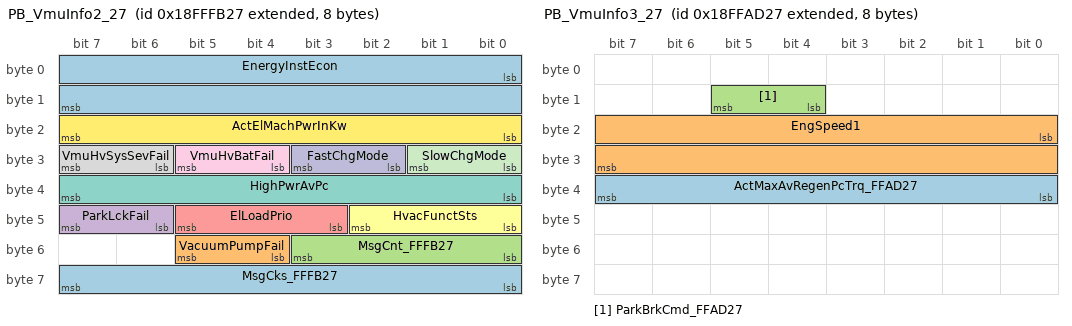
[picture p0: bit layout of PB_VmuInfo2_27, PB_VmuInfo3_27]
BO_ 2566912807 PB_VmuInfo2_27: 8 VCM
 SG_ MsgCks_FFFB27 : 56|8@1+ (1,0) [0|255] "count"  PCM
 SG_ VacuumPumpFail : 52|2@1+ (1,0) [0|3] ""  PCM
 SG_ MsgCnt_FFFB27 : 48|4@1+ (1,0) [0|15] "count"  PCM
 SG_ ParkLckFail : 46|2@1+ (1,0) [0|3] ""  PCM
 SG_ ElLoadPrio : 43|3@1+ (1,0) [0|7] ""  PCM
 SG_ HvacFunctSts : 40|3@1+ (1,0) [0|7] ""  PCM
 SG_ HighPwrAvPc : 32|8@1+ (0.4,0) [0|100] "%"  PCM
 SG_ VmuHvSysSevFail : 30|2@1+ (1,0) [0|3] ""  PCM
 SG_ VmuHvBatFail : 28|2@1+ (1,0) [0|3] ""  PCM
 SG_ FastChgMode : 26|2@1+ (1,0) [0|3] ""  PCM
 SG_ SlowChgMode : 24|2@1+ (1,0) [0|3] ""  PCM
 SG_ ActElMachPwrInKw : 16|8@1+ (1,-125) [-125|125] "%"  PCM
 SG_ EnergyInstEcon : 0|16@1+ (0.001953125,0) [0|125.498046875] "km/KWh"  PCM

BO_ 2566892839 PB_VmuInfo3_27: 8 VCM
 SG_ ActMaxAvRegenPcTrq_FFAD27 : 32|8@1+ (0.4,0) [0|100] "%"  PCM
 SG_ EngSpeed1 : 16|16@1+ (0.5,0) [0|32127.5] "rpm"  PCM
 SG_ ParkBrkCmd_FFAD27 : 12|2@1+ (1,0) [0|3] ""  PCM

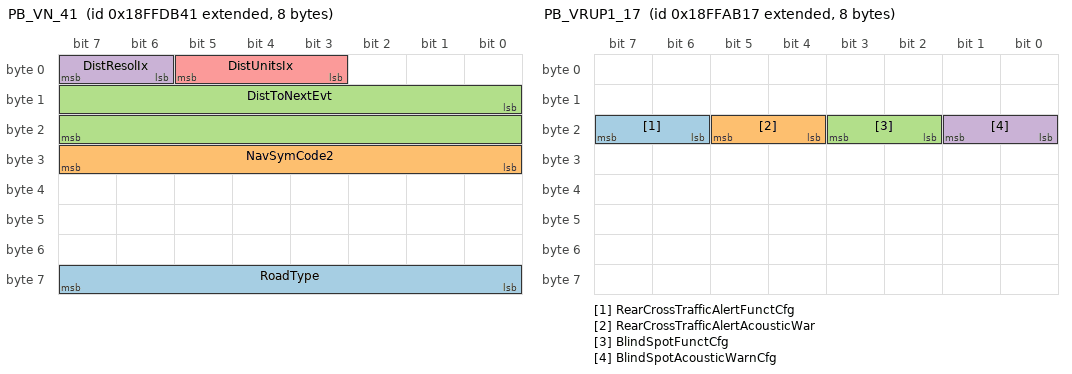
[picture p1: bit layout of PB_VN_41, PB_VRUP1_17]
BO_ 2566904641 PB_VN_41: 8 NIS_RDR
 SG_ RoadType : 56|8@1+ (1,0) [0|250] ""  PCM
 SG_ NavSymCode2 : 24|8@1+ (1,0) [0|250] ""  PCM
 SG_ DistToNextEvt : 8|16@1+ (1,0) [0|64255] ""  PCM
 SG_ DistResolIx : 6|2@1+ (1,0) [0|3] "binary"  PCM
 SG_ DistUnitsIx : 3|3@1+ (1,0) [0|7] "binary"  PCM

BO_ 2566896705 PB_VND_41: 8 NIS_RDR
 SG_ Long : 32|32@1+ (1E-007,-210) [-210|211.1081215] "deg"  PCM
 SG_ Lat : 0|32@1+ (1E-007,-210) [-210|211.1081215] "deg"  PCM

BO_ 2566896714 PB_VND_4A: 8 PCM
 SG_ Long_FFBC4A : 32|32@1+ (1E-007,-210) [-210|211.1081215] "deg" Vector__XXX
 SG_ Lat_FFBC4A : 0|32@1+ (1E-007,-210) [-210|211.1081215] "deg" Vector__XXX

BO_ 2634009665 PB_VNS_41: 402 NIS_RDR
 SG_ NavNextEvtStreetName : 0|8@1+ (1,0) [0|255] "ASCII"  PCM

BO_ 2566892311 PB_VRUP1_17: 8 ICC
 SG_ RearCrossTrafficAlertFunctCfg : 22|2@1+ (1,0) [0|3] ""  PCM
 SG_ RearCrossTrafficAlertAcousticWar : 20|2@1+ (1,0) [0|3] ""  PCM
 SG_ BlindSpotFunctCfg : 18|2@1+ (1,0) [0|3] ""  PCM
 SG_ BlindSpotAcousticWarnCfg : 16|2@1+ (1,0) [0|3] ""  PCM

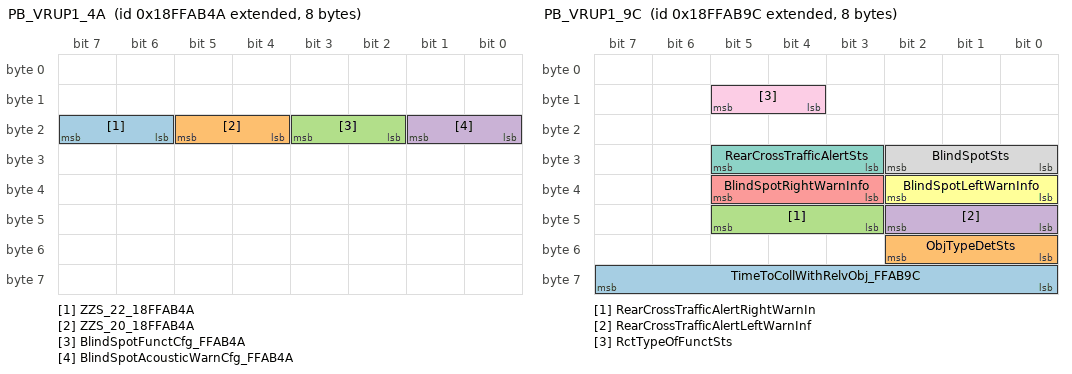
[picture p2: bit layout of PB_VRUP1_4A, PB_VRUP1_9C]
BO_ 2566892362 PB_VRUP1_4A: 8 PCM
 SG_ ZZS_22_18FFAB4A : 22|2@1+ (1,0) [0|3] "" Vector__XXX
 SG_ ZZS_20_18FFAB4A : 20|2@1+ (1,0) [0|3] "" Vector__XXX
 SG_ BlindSpotFunctCfg_FFAB4A : 18|2@1+ (1,0) [0|3] "" Vector__XXX
 SG_ BlindSpotAcousticWarnCfg_FFAB4A : 16|2@1+ (1,0) [0|3] "" Vector__XXX

BO_ 2566892444 PB_VRUP1_9C: 8 RSRRM
 SG_ TimeToCollWithRelvObj_FFAB9C : 56|8@1+ (0.05,0) [0|12.5] "s"  PCM
 SG_ ObjTypeDetSts : 48|3@1+ (1,0) [0|7] ""  PCM
 SG_ RearCrossTrafficAlertRightWarnIn : 43|3@1+ (1,0) [0|7] ""  PCM
 SG_ RearCrossTrafficAlertLeftWarnInf : 40|3@1+ (1,0) [0|7] ""  PCM
 SG_ BlindSpotRightWarnInfo : 35|3@1+ (1,0) [0|7] ""  PCM
 SG_ BlindSpotLeftWarnInfo : 32|3@1+ (1,0) [0|7] ""  PCM
 SG_ RearCrossTrafficAlertSts : 27|3@1+ (1,0) [0|7] ""  PCM
 SG_ BlindSpotSts : 24|3@1+ (1,0) [0|7] ""  PCM
 SG_ RctTypeOfFunctSts : 12|2@1+ (1,0) [0|3] ""  PCM

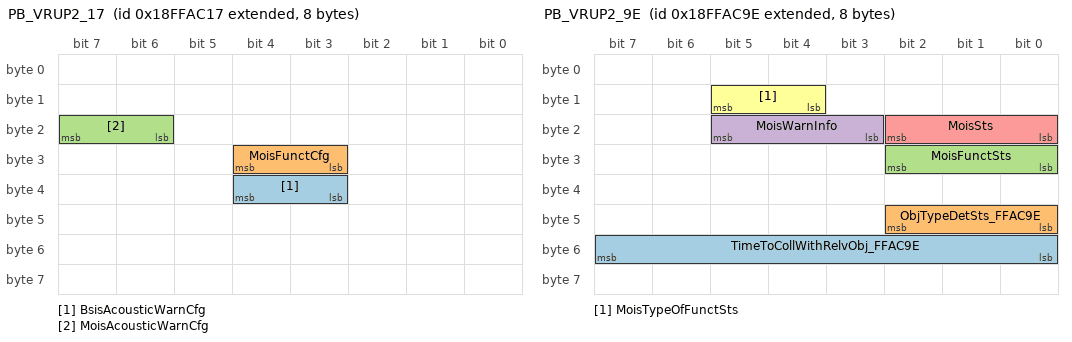
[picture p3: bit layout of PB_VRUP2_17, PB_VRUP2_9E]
BO_ 2566892567 PB_VRUP2_17: 8 ICC
 SG_ BsisAcousticWarnCfg : 35|2@1+ (1,0) [0|3] ""  PCM
 SG_ MoisFunctCfg : 27|2@1+ (1,0) [0|3] ""  PCM
 SG_ MoisAcousticWarnCfg : 22|2@1+ (1,0) [0|3] ""  PCM

BO_ 2566892618 PB_VRUP2_4A: 8 PCM
 SG_ BsisAcousticWarnCfg_FFAC4A : 35|2@1+ (1,0) [0|3] "" Vector__XXX

BO_ 2566892702 PB_VRUP2_9E: 8 ADCU
 SG_ TimeToCollWithRelvObj_FFAC9E : 48|8@1+ (0.05,0) [0|12.5] "s"  PCM
 SG_ ObjTypeDetSts_FFAC9E : 40|3@1+ (1,0) [0|7] ""  PCM
 SG_ MoisFunctSts : 24|3@1+ (1,0) [0|7] ""  PCM
 SG_ MoisWarnInfo : 19|3@1+ (1,0) [0|7] ""  PCM
 SG_ MoisSts : 16|3@1+ (1,0) [0|7] ""  PCM
 SG_ MoisTypeOfFunctSts : 12|2@1+ (1,0) [0|3] ""  PCM

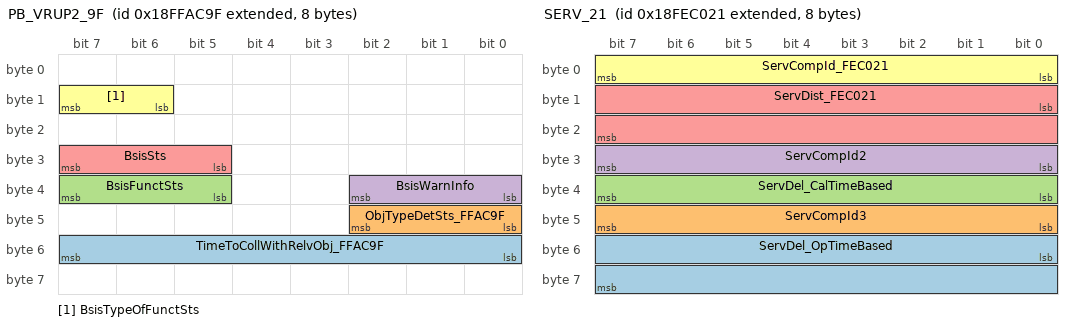
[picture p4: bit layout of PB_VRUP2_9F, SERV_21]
BO_ 2566892703 PB_VRUP2_9F: 8 NODE_9F
 SG_ TimeToCollWithRelvObj_FFAC9F : 48|8@1+ (0.05,0) [0|12.5] "s"  PCM
 SG_ ObjTypeDetSts_FFAC9F : 40|3@1+ (1,0) [0|7] ""  PCM
 SG_ BsisFunctSts : 37|3@1+ (1,0) [0|7] ""  PCM
 SG_ BsisWarnInfo : 32|3@1+ (1,0) [0|7] ""  PCM
 SG_ BsisSts : 29|3@1+ (1,0) [0|7] ""  PCM
 SG_ BsisTypeOfFunctSts : 14|2@1+ (1,0) [0|3] ""  PCM

BO_ 2566865010 PtoSts: 8 EM_PTO
 SG_ PtoDegrModeIx : 56|8@1+ (1,0) [0|255] ""  PCM
 SG_ Pto3EsvCtrl : 52|1@1+ (1,0) [0|1] ""  PCM
 SG_ Pto3LowOilPrs : 51|1@1+ (1,0) [0|1] ""  PCM
 SG_ Pto3Et2Ctrl : 50|1@1+ (1,0) [0|1] ""  PCM
 SG_ Pto3WaterTemp : 49|1@1+ (1,0) [0|1] ""  PCM
 SG_ Pto3VehSpeed : 48|1@1+ (1,0) [0|1] ""  PCM
 SG_ Pto3EngRpm : 47|1@1+ (1,0) [0|1] ""  PCM
 SG_ Pto3Gear : 46|1@1+ (1,0) [0|1] ""  PCM
 SG_ Pto3Clt : 45|1@1+ (1,0) [0|1] ""  PCM
 SG_ Pto3EmIn : 44|1@1+ (1,0) [0|1] ""  PCM
 SG_ Pto3Handbrake : 43|1@1+ (1,0) [0|1] ""  PCM
 SG_ Pto3Brk : 42|1@1+ (1,0) [0|1] ""  PCM
 SG_ Pto3DegrOpMode : 40|2@1+ (1,0) [0|3] ""  PCM
 SG_ Pto2EsvCtrl : 36|1@1+ (1,0) [0|1] ""  PCM
 SG_ Pto2LowOilPrs : 35|1@1+ (1,0) [0|1] ""  PCM
 SG_ Pto2Et2Ctrl : 34|1@1+ (1,0) [0|1] ""  PCM
 SG_ Pto2WaterTemp : 33|1@1+ (1,0) [0|1] ""  PCM
 SG_ Pto2VehSpeed : 32|1@1+ (1,0) [0|1] ""  PCM
 SG_ Pto2EngRpm : 31|1@1+ (1,0) [0|1] ""  PCM
 SG_ Pto2Gear : 30|1@1+ (1,0) [0|1] ""  PCM
 SG_ Pto2Clt : 29|1@1+ (1,0) [0|1] ""  PCM
 SG_ Pto2EmIn : 28|1@1+ (1,0) [0|1] ""  PCM
 SG_ Pto2Handbrake : 27|1@1+ (1,0) [0|1] ""  PCM
 SG_ Pto2Brk : 26|1@1+ (1,0) [0|1] ""  PCM
 SG_ Pto2DegrOpMode : 24|2@1+ (1,0) [0|3] ""  PCM
 SG_ Pto1EsvCtrl : 20|1@1+ (1,0) [0|1] ""  PCM
 SG_ Pto1LowOilPrs : 19|1@1+ (1,0) [0|1] ""  PCM
 SG_ Pto1Et2Ctrl : 18|1@1+ (1,0) [0|1] ""  PCM
 SG_ Pto1WaterTemp : 17|1@1+ (1,0) [0|1] ""  PCM
 SG_ Pto1VehSpeed : 16|1@1+ (1,0) [0|1] ""  PCM
 SG_ Pto1EngRpm : 15|1@1+ (1,0) [0|1] ""  PCM
 SG_ Pto1Gear : 14|1@1+ (1,0) [0|1] ""  PCM
 SG_ Pto1Clt : 13|1@1+ (1,0) [0|1] ""  PCM
 SG_ Pto1EmIn : 12|1@1+ (1,0) [0|1] ""  PCM
 SG_ Pto1Handbrake : 11|1@1+ (1,0) [0|1] ""  PCM
 SG_ Pto1Brk : 10|1@1+ (1,0) [0|1] ""  PCM
 SG_ Pto1DegrOpMode : 8|2@1+ (1,0) [0|3] ""  PCM
 SG_ Pto1EngdSts : 6|2@1+ (1,0) [0|3] ""  PCM
 SG_ Pto2EngdSts : 4|2@1+ (1,0) [0|3] ""  PCM
 SG_ Pto3EngdSts : 2|2@1+ (1,0) [0|3] ""  PCM
 SG_ DegrModeSts : 0|2@1+ (1,0) [0|3] ""  PCM

BO_ 2566840592 RC_DR: 19 EST54_IRCS
 SG_ RetPcTrqAtPeakTrqPnt5 : 144|8@1+ (1,-125) [-125|125] "%"  PCM
 SG_ RetRefTrq : 128|16@1+ (1,0) [0|64255] "Nm"  PCM
 SG_ RetSpeedAtPeakTrqPnt5 : 112|16@1+ (0.125,0) [0|8031.875] "rpm"  PCM
 SG_ RetPcTrqAtPnt4 : 104|8@1+ (1,-125) [-125|125] "%"  PCM
 SG_ RetSpeedAtPnt4 : 88|16@1+ (0.125,0) [0|8031.875] "rpm"  PCM
 SG_ RetPcTrqAtPnt3 : 80|8@1+ (1,-125) [-125|125] "%"  PCM
 SG_ RetSpeedAtPnt3 : 64|16@1+ (0.125,0) [0|8031.875] "rpm"  PCM
 SG_ RetPcTrqAtMaxSpeedPnt2 : 56|8@1+ (1,-125) [-125|125] "%"  PCM
 SG_ MaxRetSpeedPnt2 : 40|16@1+ (0.125,0) [0|8031.875] "rpm"  PCM
 SG_ RetPcTrqAtIdlePnt1 : 32|8@1+ (1,-125) [-125|125] "%"  PCM
 SG_ RetSpeedAtIdlePnt1 : 16|16@1+ (0.125,0) [0|8031.875] "rpm"  PCM
 SG_ RetCtrlMethod : 8|8@1+ (1,0) [0|250] "step"  PCM
 SG_ RetLoc : 4|4@1+ (1,0) [0|15] ""  PCM
 SG_ RetType : 0|4@1+ (1,0) [0|15] ""  PCM

BO_ 2565537610 RQST_4A: 3 PCM
 SG_ PgnRqst : 0|24@1+ (1,0) [0|16777215] "PGN" Vector__XXX

BO_ 2565472330 RQST_4A_00: 3 PCM
 SG_ PgnRqst_EA004A : 0|24@1+ (1,0) [0|16777215] "PGN"  ECM

BO_ 2565473098 RQST_4A_03: 3 PCM
 SG_ PgnRqst_EA034A : 0|24@1+ (1,0) [0|16777215] "PGN"  AI_G5_TCM

BO_ 2565474122 RQST_4A_07: 3 PCM
 SG_ PgnRqst_EA074A : 0|24@1+ (1,0) [0|16777215] "PGN"  NODE_7

BO_ 2565478986 RQST_4A_1A: 3 PCM
 SG_ PgnRqst_EA1A4A : 0|24@1+ (1,0) [0|16777215] "PGN"  ECS

BO_ 2565480778 RQST_4A_21: 3 PCM
 SG_ PgnRqst_EA214A : 0|24@1+ (1,0) [0|16777215] "PGN"  BCM

BO_ 2565481546 RQST_4A_24: 3 PCM
 SG_ PgnRqst_EA244A : 0|24@1+ (1,0) [0|16777215] "PGN"  NODE_24

BO_ 2565482314 RQST_4A_27: 3 PCM
 SG_ PgnRqst_EA274A : 0|24@1+ (1,0) [0|16777215] "PGN"  VCM

BO_ 2565485386 RQST_4A_33: 3 PCM
 SG_ PgnRqst_EA334A : 0|24@1+ (1,0) [0|16777215] "PGN"  OptiTire

BO_ 2565488970 RQST_4A_41: 3 PCM
 SG_ PgnRqst_EA414A : 0|24@1+ (1,0) [0|16777215] "PGN"  NIS_RDR

BO_ 2565491018 RQST_4A_49: 3 PCM
 SG_ PgnRqst_EA494A : 0|24@1+ (1,0) [0|16777215] "PGN"  NODE_49

BO_ 2565504074 RQST_4A_7C: 3 PCM
 SG_ PgnRqst_EA7C4A : 0|24@1+ (1,0) [0|16777215] "PGN"  NODE_7C

BO_ 2565506634 RQST_4A_86: 3 PCM
 SG_ PgnRqst_EA864A : 0|24@1+ (1,0) [0|16777215] "PGN"  NODE_86

BO_ 2565506890 RQST_4A_87: 3 PCM
 SG_ PgnRqst_EA874A : 0|24@1+ (1,0) [0|16777215] "PGN"  NODE_87

BO_ 2565533258 RQST_4A_EE: 3 PCM
 SG_ PgnRqst_EAEE4A : 0|24@1+ (1,0) [0|16777215] "PGN"  DTCO

BO_ 2565533514 RQST_4A_EF: 3 PCM
 SG_ PgnRqst_EAEF4A : 0|24@1+ (1,0) [0|16777215] "PGN"  NODE_EF

BO_ 2565534282 RQST_4A_F2: 3 PCM
 SG_ PgnRqst_EAF24A : 0|24@1+ (1,0) [0|16777215] "PGN"  NODE_F2

BO_ 2565534538 RQST_4A_F3: 3 PCM
 SG_ PgnRqst_EAF34A : 0|24@1+ (1,0) [0|16777215] "PGN"  NODE_F3

BO_ 2565534794 RQST_4A_F4: 3 PCM
 SG_ PgnRqst_EAF44A : 0|24@1+ (1,0) [0|16777215] "PGN"  NODE_F4

BO_ 2565535050 RQST_4A_F5: 3 PCM
 SG_ PgnRqst_EAF54A : 0|24@1+ (1,0) [0|16777215] "PGN"  NODE_F5

BO_ 2565535306 RQST_4A_F6: 3 PCM
 SG_ PgnRqst_EAF64A : 0|24@1+ (1,0) [0|16777215] "PGN"  NODE_F6

BO_ 2566832128 SERV_00: 8 ECM
 SG_ ServDist : 8|16@1+ (5,-160635) [-160635|160640] "km"  PCM
 SG_ ServCompId : 0|8@1+ (1,0) [0|250] "ID"  PCM

BO_ 2566832161 SERV_21: 8 BCM
 SG_ ServDel_OpTimeBased : 48|16@1+ (1,-32127) [-32127|32128] "h"  PCM
 SG_ ServCompId3 : 40|8@1+ (1,0) [0|250] "ID"  PCM
 SG_ ServDel_CalTimeBased : 32|8@1+ (1,-125) [-125|125] "week"  PCM
 SG_ ServCompId2 : 24|8@1+ (1,0) [0|250] "ID"  PCM
 SG_ ServDist_FEC021 : 8|16@1+ (5,-160635) [-160635|160640] "km"  PCM
 SG_ ServCompId_FEC021 : 0|8@1+ (1,0) [0|250] "ID"  PCM

BO_ 2566832366 SERV_EE: 8 DTCO
 SG_ ServDel_CalTimeBased_FEC0EE : 32|8@1+ (1,-125) [-125|125] "week"  PCM
 SG_ ServCompId2_FEC0EE : 24|8@1+ (1,0) [0|250] "ID"  PCM

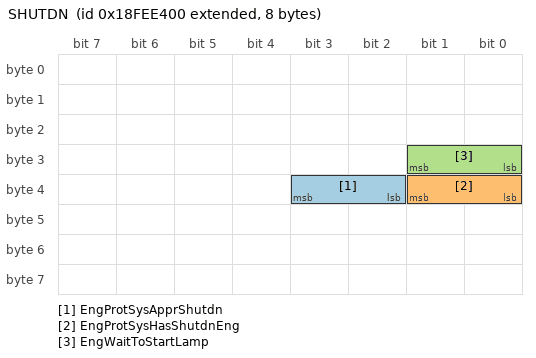
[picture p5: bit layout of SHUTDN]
BO_ 2566841344 SHUTDN: 8 ECM
 SG_ EngProtSysApprShutdn : 34|2@1+ (1,0) [0|3] ""  PCM
 SG_ EngProtSysHasShutdnEng : 32|2@1+ (1,0) [0|3] ""  PCM
 SG_ EngWaitToStartLamp : 24|2@1+ (1,0) [0|3] ""  PCM

BO_ 2566838789 SOFT_05: 202 NODE_5
 SG_ SwIdField5 : 40|8@1+ (1,0) [0|255] "ASCII"  PCM
 SG_ SwIdField4 : 32|8@1+ (1,0) [0|255] "ASCII"  PCM
 SG_ SwIdField3 : 24|8@1+ (1,0) [0|255] "ASCII"  PCM
 SG_ SwIdField2 : 16|8@1+ (1,0) [0|255] "ASCII"  PCM
 SG_ SwIdField1 : 8|8@1+ (1,0) [0|255] "ASCII"  PCM
 SG_ NumOfSwIdFields : 0|8@1+ (1,0) [0|250] "step"  PCM

BO_ 2566838791 SOFT_07: 202 NODE_7
 SG_ SwIdField5_FEDA07 : 40|8@1+ (1,0) [0|255] "ASCII"  PCM
 SG_ SwIdField4_FEDA07 : 32|8@1+ (1,0) [0|255] "ASCII"  PCM
 SG_ SwIdField3_FEDA07 : 24|8@1+ (1,0) [0|255] "ASCII"  PCM
 SG_ SwIdField2_FEDA07 : 16|8@1+ (1,0) [0|255] "ASCII"  PCM
 SG_ SwIdField1_FEDA07 : 8|8@1+ (1,0) [0|255] "ASCII"  PCM
 SG_ NumOfSwIdFields_FEDA07 : 0|8@1+ (1,0) [0|250] "step"  PCM

BO_ 2566838810 SOFT_1A: 202 ECS
 SG_ SwIdField5_FEDA1A : 40|8@1+ (1,0) [0|255] "ASCII"  PCM
 SG_ SwIdField4_FEDA1A : 32|8@1+ (1,0) [0|255] "ASCII"  PCM
 SG_ SwIdField3_FEDA1A : 24|8@1+ (1,0) [0|255] "ASCII"  PCM
 SG_ SwIdField2_FEDA1A : 16|8@1+ (1,0) [0|255] "ASCII"  PCM
 SG_ SwIdField1_FEDA1A : 8|8@1+ (1,0) [0|255] "ASCII"  PCM
 SG_ NumOfSwIdFields_FEDA1A : 0|8@1+ (1,0) [0|250] "step"  PCM

BO_ 2566838813 SOFT_1D: 202 SGW
 SG_ SwIdField5_FEDA1D : 40|8@1+ (1,0) [0|255] "ASCII"  PCM
 SG_ SwIdField4_FEDA1D : 32|8@1+ (1,0) [0|255] "ASCII"  PCM
 SG_ SwIdField3_FEDA1D : 24|8@1+ (1,0) [0|255] "ASCII"  PCM
 SG_ SwIdField2_FEDA1D : 16|8@1+ (1,0) [0|255] "ASCII"  PCM
 SG_ SwIdField1_FEDA1D : 8|8@1+ (1,0) [0|255] "ASCII"  PCM
 SG_ NumOfSwIdFields_FEDA1D : 0|8@1+ (1,0) [0|250] "step"  PCM

BO_ 2566838820 SOFT_24: 202 NODE_24
 SG_ SwIdField5_FEDA24 : 40|8@1+ (1,0) [0|255] "ASCII"  PCM
 SG_ SwIdField4_FEDA24 : 32|8@1+ (1,0) [0|255] "ASCII"  PCM
 SG_ SwIdField3_FEDA24 : 24|8@1+ (1,0) [0|255] "ASCII"  PCM
 SG_ SwIdField2_FEDA24 : 16|8@1+ (1,0) [0|255] "ASCII"  PCM
 SG_ SwIdField1_FEDA24 : 8|8@1+ (1,0) [0|255] "ASCII"  PCM
 SG_ NumOfSwIdFields_FEDA24 : 0|8@1+ (1,0) [0|250] "step"  PCM

BO_ 2566838823 SOFT_27: 202 VCM
 SG_ SwIdField5_FEDA27 : 40|8@1+ (1,0) [0|255] "ASCII"  PCM
 SG_ SwIdField4_FEDA27 : 32|8@1+ (1,0) [0|255] "ASCII"  PCM
 SG_ SwIdField3_FEDA27 : 24|8@1+ (1,0) [0|255] "ASCII"  PCM
 SG_ SwIdField2_FEDA27 : 16|8@1+ (1,0) [0|255] "ASCII"  PCM
 SG_ SwIdField1_FEDA27 : 8|8@1+ (1,0) [0|255] "ASCII"  PCM
 SG_ NumOfSwIdFields_FEDA27 : 0|8@1+ (1,0) [0|250] "step"  PCM

BO_ 2566838831 SOFT_2F: 202 ECAS
 SG_ SwIdField5_FEDA2F : 40|8@1+ (1,0) [0|255] "ASCII"  PCM
 SG_ SwIdField4_FEDA2F : 32|8@1+ (1,0) [0|255] "ASCII"  PCM
 SG_ SwIdField3_FEDA2F : 24|8@1+ (1,0) [0|255] "ASCII"  PCM
 SG_ SwIdField2_FEDA2F : 16|8@1+ (1,0) [0|255] "ASCII"  PCM
 SG_ SwIdField1_FEDA2F : 8|8@1+ (1,0) [0|255] "ASCII"  PCM
 SG_ NumOfSwIdFields_FEDA2F : 0|8@1+ (1,0) [0|250] "step"  PCM

BO_ 2566838832 SOFT_30: 190 CDC
 SG_ SwIdField5_FEDA30 : 40|8@1+ (1,0) [0|255] "ASCII"  PCM
 SG_ SwIdField4_FEDA30 : 32|8@1+ (1,0) [0|255] "ASCII"  PCM
 SG_ SwIdField3_FEDA30 : 24|8@1+ (1,0) [0|255] "ASCII"  PCM
 SG_ SwIdField2_FEDA30 : 16|8@1+ (1,0) [0|255] "ASCII"  PCM
 SG_ SwIdField1_FEDA30 : 8|8@1+ (1,0) [0|255] "ASCII"  PCM
 SG_ NumOfSwIdFields_FEDA30 : 0|8@1+ (1,0) [0|250] "step"  PCM

BO_ 2566838835 SOFT_33: 202 OptiTire
 SG_ SwIdField5_FEDA33 : 40|8@1+ (1,0) [0|255] "ASCII"  PCM
 SG_ SwIdField4_FEDA33 : 32|8@1+ (1,0) [0|255] "ASCII"  PCM
 SG_ SwIdField3_FEDA33 : 24|8@1+ (1,0) [0|255] "ASCII"  PCM
 SG_ SwIdField2_FEDA33 : 16|8@1+ (1,0) [0|255] "ASCII"  PCM
 SG_ SwIdField1_FEDA33 : 8|8@1+ (1,0) [0|255] "ASCII"  PCM
 SG_ NumOfSwIdFields_FEDA33 : 0|8@1+ (1,0) [0|250] "step"  PCM

BO_ 2566838849 SOFT_41: 202 NIS_RDR
 SG_ SwIdField5_FEDA41 : 40|8@1+ (1,0) [0|255] "ASCII"  PCM
 SG_ SwIdField4_FEDA41 : 32|8@1+ (1,0) [0|255] "ASCII"  PCM
 SG_ SwIdField3_FEDA41 : 24|8@1+ (1,0) [0|255] "ASCII"  PCM
 SG_ SwIdField2_FEDA41 : 16|8@1+ (1,0) [0|255] "ASCII"  PCM
 SG_ SwIdField1_FEDA41 : 8|8@1+ (1,0) [0|255] "ASCII"  PCM
 SG_ NumOfSwIdFields_FEDA41 : 0|8@1+ (1,0) [0|250] "step"  PCM

BO_ 2566838857 SOFT_49: 202 NODE_49
 SG_ SwIdField5_FEDA49 : 40|8@1+ (1,0) [0|255] "ASCII"  PCM
 SG_ SwIdField4_FEDA49 : 32|8@1+ (1,0) [0|255] "ASCII"  PCM
 SG_ SwIdField3_FEDA49 : 24|8@1+ (1,0) [0|255] "ASCII"  PCM
 SG_ SwIdField2_FEDA49 : 16|8@1+ (1,0) [0|255] "ASCII"  PCM
 SG_ SwIdField1_FEDA49 : 8|8@1+ (1,0) [0|255] "ASCII"  PCM
 SG_ NumOfSwIdFields_FEDA49 : 0|8@1+ (1,0) [0|250] "step"  PCM

BO_ 2566838858 SOFT_4A: 202 PCM
 SG_ SwIdField5_FEDA4A : 40|8@1+ (1,0) [0|255] "ASCII" Vector__XXX
 SG_ SwIdField4_FEDA4A : 32|8@1+ (1,0) [0|255] "ASCII" Vector__XXX
 SG_ SwIdField3_FEDA4A : 24|8@1+ (1,0) [0|255] "ASCII" Vector__XXX
 SG_ SwIdField2_FEDA4A : 16|8@1+ (1,0) [0|255] "ASCII" Vector__XXX
 SG_ SwIdField1_FEDA4A : 8|8@1+ (1,0) [0|255] "ASCII" Vector__XXX
 SG_ NumOfSwIdFields_FEDA4A : 0|8@1+ (1,0) [0|250] "step" Vector__XXX

BO_ 2566838861 SOFT_4D: 202 SCU
 SG_ SwIdField5_FEDA4D : 40|8@1+ (1,0) [0|255] "ASCII"  PCM
 SG_ SwIdField4_FEDA4D : 32|8@1+ (1,0) [0|255] "ASCII"  PCM
 SG_ SwIdField3_FEDA4D : 24|8@1+ (1,0) [0|255] "ASCII"  PCM
 SG_ SwIdField2_FEDA4D : 16|8@1+ (1,0) [0|255] "ASCII"  PCM
 SG_ SwIdField1_FEDA4D : 8|8@1+ (1,0) [0|255] "ASCII"  PCM
 SG_ NumOfSwIdFields_FEDA4D : 0|8@1+ (1,0) [0|250] "step"  PCM

BO_ 2566838904 SOFT_78: 202 PAM
 SG_ SwIdField5_FEDA78 : 40|8@1+ (1,0) [0|255] "ASCII"  PCM
 SG_ SwIdField4_FEDA78 : 32|8@1+ (1,0) [0|255] "ASCII"  PCM
 SG_ SwIdField3_FEDA78 : 24|8@1+ (1,0) [0|255] "ASCII"  PCM
 SG_ SwIdField2_FEDA78 : 16|8@1+ (1,0) [0|255] "ASCII"  PCM
 SG_ SwIdField1_FEDA78 : 8|8@1+ (1,0) [0|255] "ASCII"  PCM
 SG_ NumOfSwIdFields_FEDA78 : 0|8@1+ (1,0) [0|250] "step"  PCM

BO_ 2566838908 SOFT_7C: 202 NODE_7C
 SG_ SwIdField5_FEDA7C : 40|8@1+ (1,0) [0|255] "ASCII"  PCM
 SG_ SwIdField4_FEDA7C : 32|8@1+ (1,0) [0|255] "ASCII"  PCM
 SG_ SwIdField3_FEDA7C : 24|8@1+ (1,0) [0|255] "ASCII"  PCM
 SG_ SwIdField2_FEDA7C : 16|8@1+ (1,0) [0|255] "ASCII"  PCM
 SG_ SwIdField1_FEDA7C : 8|8@1+ (1,0) [0|255] "ASCII"  PCM
 SG_ NumOfSwIdFields_FEDA7C : 0|8@1+ (1,0) [0|250] "step"  PCM

BO_ 2566839023 SOFT_EF: 202 NODE_EF
 SG_ SwIdField5_FEDAEF : 40|8@1+ (1,0) [0|255] "ASCII"  PCM
 SG_ SwIdField4_FEDAEF : 32|8@1+ (1,0) [0|255] "ASCII"  PCM
 SG_ SwIdField3_FEDAEF : 24|8@1+ (1,0) [0|255] "ASCII"  PCM
 SG_ SwIdField2_FEDAEF : 16|8@1+ (1,0) [0|255] "ASCII"  PCM
 SG_ SwIdField1_FEDAEF : 8|8@1+ (1,0) [0|255] "ASCII"  PCM
 SG_ NumOfSwIdFields_FEDAEF : 0|8@1+ (1,0) [0|250] "step"  PCM

BO_ 2566839026 SOFT_F2: 202 NODE_F2
 SG_ SwIdField5_FEDAF2 : 40|8@1+ (1,0) [0|255] "ASCII"  PCM
 SG_ SwIdField4_FEDAF2 : 32|8@1+ (1,0) [0|255] "ASCII"  PCM
 SG_ SwIdField3_FEDAF2 : 24|8@1+ (1,0) [0|255] "ASCII"  PCM
 SG_ SwIdField2_FEDAF2 : 16|8@1+ (1,0) [0|255] "ASCII"  PCM
 SG_ SwIdField1_FEDAF2 : 8|8@1+ (1,0) [0|255] "ASCII"  PCM
 SG_ NumOfSwIdFields_FEDAF2 : 0|8@1+ (1,0) [0|250] "step"  PCM

BO_ 2566839027 SOFT_F3: 202 NODE_F3
 SG_ SwIdField5_FEDAF3 : 40|8@1+ (1,0) [0|255] "ASCII"  PCM
 SG_ SwIdField4_FEDAF3 : 32|8@1+ (1,0) [0|255] "ASCII"  PCM
 SG_ SwIdField3_FEDAF3 : 24|8@1+ (1,0) [0|255] "ASCII"  PCM
 SG_ SwIdField2_FEDAF3 : 16|8@1+ (1,0) [0|255] "ASCII"  PCM
 SG_ SwIdField1_FEDAF3 : 8|8@1+ (1,0) [0|255] "ASCII"  PCM
 SG_ NumOfSwIdFields_FEDAF3 : 0|8@1+ (1,0) [0|250] "step"  PCM

BO_ 2364543755 SSI_0B: 8 BSM
 SG_ PitchAngleFigOfMerit : 48|2@1+ (1,0) [0|3] ""  PCM
 SG_ PitchAngle : 0|16@1+ (0.002,-64) [-64|64.51] "deg"  PCM

CM_ BO_ 2566912807 "- Active also in Doze mode";
CM_ BO_ 2566896705 "- Navigation actual destination";
CM_ BO_ 2566896714 "- Navigation destination request";
CM_ BO_ 2566892444 "- Faster transmission rate when active and once afterwards";
CM_ BO_ 2566892702 "- Faster transmission rate when active and once afterwards";
CM_ BO_ 2566892703 "- Faster transmission rate when active and once afterwards";
CM_ BO_ 2566840592 "- Multipacket messages handled by SAE Transport Protocol (J1939/21, par 5.10, Multipacket Broadcast with TP.CM/BAM, TP.DT)";
CM_ BO_ 2565537610 "- Any Source Address and ECU specific or Global Destination Addresses shall be accepted (IVECO Std. 18-2253)";
CM_ SG_ 2565537610 PgnRqst "- Value Table filled with the most commonly used PGNs in Iveco applications, ECU implementation may differ";
CM_ BO_ 2565472330 "- Any Source Address and ECU specific or Global Destination Addresses shall be accepted (IVECO Std. 18-2253)";
CM_ SG_ 2565472330 PgnRqst_EA004A "- Value Table filled with the most commonly used PGNs in Iveco applications, ECU implementation may differ";
CM_ BO_ 2565473098 "- Any Source Address and ECU specific or Global Destination Addresses shall be accepted (IVECO Std. 18-2253)";
CM_ SG_ 2565473098 PgnRqst_EA034A "- Value Table filled with the most commonly used PGNs in Iveco applications, ECU implementation may differ";
CM_ BO_ 2565474122 "- Any Source Address and ECU specific or Global Destination Addresses shall be accepted (IVECO Std. 18-2253)";
CM_ SG_ 2565474122 PgnRqst_EA074A "- Value Table filled with the most commonly used PGNs in Iveco applications, ECU implementation may differ";
CM_ BO_ 2565478986 "- Any Source Address and ECU specific or Global Destination Addresses shall be accepted (IVECO Std. 18-2253)";
CM_ SG_ 2565478986 PgnRqst_EA1A4A "- Value Table filled with the most commonly used PGNs in Iveco applications, ECU implementation may differ";
CM_ BO_ 2565480778 "- Any Source Address and ECU specific or Global Destination Addresses shall be accepted (IVECO Std. 18-2253)";
CM_ SG_ 2565480778 PgnRqst_EA214A "- Value Table filled with the most commonly used PGNs in Iveco applications, ECU implementation may differ";
CM_ BO_ 2565481546 "- Any Source Address and ECU specific or Global Destination Addresses shall be accepted (IVECO Std. 18-2253)";
CM_ SG_ 2565481546 PgnRqst_EA244A "- Value Table filled with the most commonly used PGNs in Iveco applications, ECU implementation may differ";
CM_ BO_ 2565482314 "- Any Source Address and ECU specific or Global Destination Addresses shall be accepted (IVECO Std. 18-2253)";
CM_ SG_ 2565482314 PgnRqst_EA274A "- Value Table filled with the most commonly used PGNs in Iveco applications, ECU implementation may differ";
CM_ BO_ 2565485386 "- Any Source Address and ECU specific or Global Destination Addresses shall be accepted (IVECO Std. 18-2253)";
CM_ SG_ 2565485386 PgnRqst_EA334A "- Value Table filled with the most commonly used PGNs in Iveco applications, ECU implementation may differ";
CM_ BO_ 2565488970 "- Any Source Address and ECU specific or Global Destination Addresses shall be accepted (IVECO Std. 18-2253)";
CM_ SG_ 2565488970 PgnRqst_EA414A "- Value Table filled with the most commonly used PGNs in Iveco applications, ECU implementation may differ";
CM_ BO_ 2565491018 "- Any Source Address and ECU specific or Global Destination Addresses shall be accepted (IVECO Std. 18-2253)";
CM_ SG_ 2565491018 PgnRqst_EA494A "- Value Table filled with the most commonly used PGNs in Iveco applications, ECU implementation may differ";
CM_ BO_ 2565504074 "- Any Source Address and ECU specific or Global Destination Addresses shall be accepted (IVECO Std. 18-2253)";
CM_ SG_ 2565504074 PgnRqst_EA7C4A "- Value Table filled with the most commonly used PGNs in Iveco applications, ECU implementation may differ";
CM_ BO_ 2565506634 "- Any Source Address and ECU specific or Global Destination Addresses shall be accepted (IVECO Std. 18-2253)";
CM_ SG_ 2565506634 PgnRqst_EA864A "- Value Table filled with the most commonly used PGNs in Iveco applications, ECU implementation may differ";
CM_ BO_ 2565506890 "- Any Source Address and ECU specific or Global Destination Addresses shall be accepted (IVECO Std. 18-2253)";
CM_ SG_ 2565506890 PgnRqst_EA874A "- Value Table filled with the most commonly used PGNs in Iveco applications, ECU implementation may differ";
CM_ BO_ 2565533258 "- Any Source Address and ECU specific or Global Destination Addresses shall be accepted (IVECO Std. 18-2253)";
CM_ SG_ 2565533258 PgnRqst_EAEE4A "- Value Table filled with the most commonly used PGNs in Iveco applications, ECU implementation may differ";
CM_ BO_ 2565533514 "- Any Source Address and ECU specific or Global Destination Addresses shall be accepted (IVECO Std. 18-2253)";
CM_ SG_ 2565533514 PgnRqst_EAEF4A "- Value Table filled with the most commonly used PGNs in Iveco applications, ECU implementation may differ";
CM_ BO_ 2565534282 "- Any Source Address and ECU specific or Global Destination Addresses shall be accepted (IVECO Std. 18-2253)";
CM_ SG_ 2565534282 PgnRqst_EAF24A "- Value Table filled with the most commonly used PGNs in Iveco applications, ECU implementation may differ";
CM_ BO_ 2565534538 "- Any Source Address and ECU specific or Global Destination Addresses shall be accepted (IVECO Std. 18-2253)";
CM_ SG_ 2565534538 PgnRqst_EAF34A "- Value Table filled with the most commonly used PGNs in Iveco applications, ECU implementation may differ";
CM_ BO_ 2565534794 "- Any Source Address and ECU specific or Global Destination Addresses shall be accepted (IVECO Std. 18-2253)";
CM_ SG_ 2565534794 PgnRqst_EAF44A "- Value Table filled with the most commonly used PGNs in Iveco applications, ECU implementation may differ";
CM_ BO_ 2565535050 "- Any Source Address and ECU specific or Global Destination Addresses shall be accepted (IVECO Std. 18-2253)";
CM_ SG_ 2565535050 PgnRqst_EAF54A "- Value Table filled with the most commonly used PGNs in Iveco applications, ECU implementation may differ";
CM_ BO_ 2565535306 "- Any Source Address and ECU specific or Global Destination Addresses shall be accepted (IVECO Std. 18-2253)";
CM_ SG_ 2565535306 PgnRqst_EAF64A "- Value Table filled with the most commonly used PGNs in Iveco applications, ECU implementation may differ";
CM_ BO_ 2566832161 "-  3 Message Variant(s): Transm.Rates 1000, 60000, OnRequest
-  Cyclic Transmission Rate as result of PGN requests";
CM_ BO_ 2566838789 "- Multipacket message handled by SAE Transport Protocol (J1939/21, par 5.10, Multipacket Broadcast with TP.CM/BAM, TP.DT)";
CM_ SG_ 2566838789 SwIdField5 "- 8+1 characters maximum, IVECO Warning and Fault Database Version (IVECO Std. 18-2253)
-  Variable signal length, 8 bits used for dbc generation only";
CM_ SG_ 2566838789 SwIdField4 "- 15+1 characters maximum; Calibration Identification Number (IVECO Std. 18-2253)
-  Variable signal length, 8 bits used for dbc generation only";
CM_ SG_ 2566838789 SwIdField3 "- 8+1 characters (yyyymmdd); Manufacturer SW Issue Date, optional if Software Version is available (IVECO Std. 18-2253)
-  Variable signal length, 8 bits used for dbc generation only";
CM_ SG_ 2566838789 SwIdField2 "- 15+1 characters maximum; Manufacturer SW Version, Optional if Software Issue Date is available (IVECO Std. 18-2253)
-  Variable signal length, 8 bits used for dbc generation only";
CM_ SG_ 2566838789 SwIdField1 "- 15+1 characters maximum; Manufacturer SW P/N (IVECO Std. 18-2253)
-  Variable signal length, 8 bits used for dbc generation only";
CM_ SG_ 2566838789 NumOfSwIdFields "- 5 (IVECO Std. 18-2253)";
CM_ BO_ 2566838791 "- Multipacket message handled by SAE Transport Protocol (J1939/21, par 5.10, Multipacket Broadcast with TP.CM/BAM, TP.DT)
-  Transport Protocol with Control Flow  (RTS, CTS, EndOfMsgAck, Conn_Abort) shall be also supported by the receiver if the multipacket message has been solicited by a Destination Specific Request
-  Variable Message Length, maximum value used for dbc generation";
CM_ SG_ 2566838791 SwIdField5_FEDA07 "- 8+1 characters maximum, IVECO Warning and Fault Database Version (IVECO Std. 18-2253)
-  Variable signal length, 8 bits used for dbc generation only";
CM_ SG_ 2566838791 SwIdField4_FEDA07 "- 15+1 characters maximum; Calibration Identification Number (IVECO Std. 18-2253)
-  Variable signal length, 8 bits used for dbc generation only";
CM_ SG_ 2566838791 SwIdField3_FEDA07 "- 8+1 characters (yyyymmdd); Manufacturer SW Issue Date, optional if Software Version is available (IVECO Std. 18-2253)
-  Variable signal length, 8 bits used for dbc generation only";
CM_ SG_ 2566838791 SwIdField2_FEDA07 "- 15+1 characters maximum; Manufacturer SW Version, Optional if Software Issue Date is available (IVECO Std. 18-2253)
-  Variable signal length, 8 bits used for dbc generation only";
CM_ SG_ 2566838791 SwIdField1_FEDA07 "- 15+1 characters maximum; Manufacturer SW P/N (IVECO Std. 18-2253)
-  Variable signal length, 8 bits used for dbc generation only";
CM_ SG_ 2566838791 NumOfSwIdFields_FEDA07 "- 5 (IVECO Std. 18-2253)";
CM_ BO_ 2566838810 "- Multipacket message handled by SAE Transport Protocol (J1939/21, par 5.10, Multipacket Broadcast with TP.CM/BAM, TP.DT)
-  Transport Protocol with Control Flow  (RTS, CTS, EndOfMsgAck, Conn_Abort) shall be also supported by the receiver if the multipacket message has been solicited by a Destination Specific Request
-  Variable Message Length, maximum value used for dbc generation";
CM_ SG_ 2566838810 SwIdField5_FEDA1A "- 8+1 characters maximum, IVECO Warning and Fault Database Version (IVECO Std. 18-2253)
-  Variable signal length, 8 bits used for dbc generation only";
CM_ SG_ 2566838810 SwIdField4_FEDA1A "- 15+1 characters maximum; Calibration Identification Number (IVECO Std. 18-2253)
-  Variable signal length, 8 bits used for dbc generation only";
CM_ SG_ 2566838810 SwIdField3_FEDA1A "- 8+1 characters (yyyymmdd); Manufacturer SW Issue Date, optional if Software Version is available (IVECO Std. 18-2253)
-  Variable signal length, 8 bits used for dbc generation only";
CM_ SG_ 2566838810 SwIdField2_FEDA1A "- 15+1 characters maximum; Manufacturer SW Version, Optional if Software Issue Date is available (IVECO Std. 18-2253)
-  Variable signal length, 8 bits used for dbc generation only";
CM_ SG_ 2566838810 SwIdField1_FEDA1A "- 15+1 characters maximum; Manufacturer SW P/N (IVECO Std. 18-2253)
-  Variable signal length, 8 bits used for dbc generation only";
CM_ SG_ 2566838810 NumOfSwIdFields_FEDA1A "- 5 (IVECO Std. 18-2253)";
CM_ BO_ 2566838813 "- Multipacket message handled by SAE Transport Protocol (J1939/21, par 5.10, Multipacket Broadcast with TP.CM/BAM, TP.DT)
-  Transport Protocol with Control Flow  (RTS, CTS, EndOfMsgAck, Conn_Abort) shall be also supported by the receiver if the multipacket message has been solicited by a Destination Specific Request
-  Variable Message Length, maximum value used for dbc generation";
CM_ SG_ 2566838813 SwIdField5_FEDA1D "- 8+1 characters maximum, IVECO Warning and Fault Database Version (IVECO Std. 18-2253)
-  Variable signal length, 8 bits used for dbc generation only";
CM_ SG_ 2566838813 SwIdField4_FEDA1D "- 15+1 characters maximum; Calibration Identification Number (IVECO Std. 18-2253)
-  Variable signal length, 8 bits used for dbc generation only";
CM_ SG_ 2566838813 SwIdField3_FEDA1D "- 8+1 characters (yyyymmdd); Manufacturer SW Issue Date, optional if Software Version is available (IVECO Std. 18-2253)
-  Variable signal length, 8 bits used for dbc generation only";
CM_ SG_ 2566838813 SwIdField2_FEDA1D "- 15+1 characters maximum; Manufacturer SW Version, Optional if Software Issue Date is available (IVECO Std. 18-2253)
-  Variable signal length, 8 bits used for dbc generation only";
CM_ SG_ 2566838813 SwIdField1_FEDA1D "- Variable signal length, 8 bits used for dbc generation only";
CM_ SG_ 2566838813 NumOfSwIdFields_FEDA1D "- 5 (IVECO Std. 18-2253)";
CM_ BO_ 2566838820 "- Multipacket message handled by SAE Transport Protocol (J1939/21, par 5.10, Multipacket Broadcast with TP.CM/BAM, TP.DT)
-  Transport Protocol with Control Flow  (RTS, CTS, EndOfMsgAck, Conn_Abort) shall be also supported by the receiver if the multipacket message has been solicited by a Destination Specific Request
-  Variable Message Length, maximum value used for dbc generation";
CM_ SG_ 2566838820 SwIdField5_FEDA24 "- 8+1 characters maximum, IVECO Warning and Fault Database Version (IVECO Std. 18-2253)
-  Variable signal length, 8 bits used for dbc generation only";
CM_ SG_ 2566838820 SwIdField4_FEDA24 "- 15+1 characters maximum; Calibration Identification Number (IVECO Std. 18-2253)
-  Variable signal length, 8 bits used for dbc generation only";
CM_ SG_ 2566838820 SwIdField3_FEDA24 "- 8+1 characters (yyyymmdd); Manufacturer SW Issue Date, optional if Software Version is available (IVECO Std. 18-2253)
-  Variable signal length, 8 bits used for dbc generation only";
CM_ SG_ 2566838820 SwIdField2_FEDA24 "- 15+1 characters maximum; Manufacturer SW Version, Optional if Software Issue Date is available (IVECO Std. 18-2253)
-  Variable signal length, 8 bits used for dbc generation only";
CM_ SG_ 2566838820 SwIdField1_FEDA24 "- 15+1 characters maximum; Manufacturer SW P/N (IVECO Std. 18-2253)
-  Variable signal length, 8 bits used for dbc generation only";
CM_ SG_ 2566838820 NumOfSwIdFields_FEDA24 "- 5 (IVECO Std. 18-2253)";
CM_ BO_ 2566838823 "- Multipacket message handled by SAE Transport Protocol (J1939/21, par 5.10, Multipacket Broadcast with TP.CM/BAM, TP.DT)
-  Transport Protocol with Control Flow  (RTS, CTS, EndOfMsgAck, Conn_Abort) shall be also supported by the receiver if the multipacket message has been solicited by a Destination Specific Request
-  Variable Message Length, maximum value used for dbc generation";
CM_ SG_ 2566838823 SwIdField5_FEDA27 "- 8+1 characters maximum, IVECO Warning and Fault Database Version (IVECO Std. 18-2253)
-  Variable signal length, 8 bits used for dbc generation only";
CM_ SG_ 2566838823 SwIdField4_FEDA27 "- 15+1 characters maximum; Calibration Identification Number (IVECO Std. 18-2253)
-  Variable signal length, 8 bits used for dbc generation only";
CM_ SG_ 2566838823 SwIdField3_FEDA27 "- 8+1 characters (yyyymmdd); Manufacturer SW Issue Date, optional if Software Version is available (IVECO Std. 18-2253)
-  Variable signal length, 8 bits used for dbc generation only";
CM_ SG_ 2566838823 SwIdField2_FEDA27 "- 15+1 characters maximum; Manufacturer SW Version, Optional if Software Issue Date is available (IVECO Std. 18-2253)
-  Variable signal length, 8 bits used for dbc generation only";
CM_ SG_ 2566838823 SwIdField1_FEDA27 "- Variable signal length, 8 bits used for dbc generation only";
CM_ SG_ 2566838823 NumOfSwIdFields_FEDA27 "- 5 (IVECO Std. 18-2253)";
CM_ BO_ 2566838831 "- Multipacket message handled by SAE Transport Protocol (J1939/21, par 5.10, Multipacket Broadcast with TP.CM/BAM, TP.DT)
-  Transport Protocol with Control Flow  (RTS, CTS, EndOfMsgAck, Conn_Abort) shall be also supported by the receiver if the multipacket message has been solicited by a Destination Specific Request
-  Variable Message Length, maximum value used for dbc generation";
CM_ SG_ 2566838831 SwIdField5_FEDA2F "- 8+1 characters maximum, IVECO Warning and Fault Database Version (IVECO Std. 18-2253)
-  Variable signal length, 8 bits used for dbc generation only";
CM_ SG_ 2566838831 SwIdField4_FEDA2F "- 15+1 characters maximum; Calibration Identification Number (IVECO Std. 18-2253)
-  Variable signal length, 8 bits used for dbc generation only";
CM_ SG_ 2566838831 SwIdField3_FEDA2F "- 8+1 characters (yyyymmdd); Manufacturer SW Issue Date, optional if Software Version is available (IVECO Std. 18-2253)
-  Variable signal length, 8 bits used for dbc generation only";
CM_ SG_ 2566838831 SwIdField2_FEDA2F "- 15+1 characters maximum; Manufacturer SW Version, Optional if Software Issue Date is available (IVECO Std. 18-2253)
-  Variable signal length, 8 bits used for dbc generation only";
CM_ SG_ 2566838831 SwIdField1_FEDA2F "- 15+1 characters maximum; Manufacturer SW P/N (IVECO Std. 18-2253)
-  Variable signal length, 8 bits used for dbc generation only";
CM_ SG_ 2566838831 NumOfSwIdFields_FEDA2F "- 5 (IVECO Std. 18-2253)";
CM_ BO_ 2566838832 "- Multipacket message handled by SAE Transport Protocol (J1939/21, par 5.10, Multipacket Broadcast with TP.CM/BAM, TP.DT)
-  Transport Protocol with Control Flow  (RTS, CTS, EndOfMsgAck, Conn_Abort) shall be also supported by the receiver if the multipacket message has been solicited by a Destination Specific Request
-  Variable Message Length, maximum value used for dbc generation";
CM_ SG_ 2566838832 SwIdField5_FEDA30 "- 8+1 characters maximum, IVECO Warning and Fault Database Version (IVECO Std. 18-2253)
-  Variable signal length, 8 bits used for dbc generation only";
CM_ SG_ 2566838832 SwIdField4_FEDA30 "- 15+1 characters maximum; Calibration Identification Number (IVECO Std. 18-2253)
-  Variable signal length, 8 bits used for dbc generation only";
CM_ SG_ 2566838832 SwIdField3_FEDA30 "- 8+1 characters (yyyymmdd); Manufacturer SW Issue Date, optional if Software Version is available (IVECO Std. 18-2253)
-  Variable signal length, 8 bits used for dbc generation only";
CM_ SG_ 2566838832 SwIdField2_FEDA30 "- 15+1 characters maximum; Manufacturer SW Version, Optional if Software Issue Date is available (IVECO Std. 18-2253)
-  Variable signal length, 8 bits used for dbc generation only";
CM_ SG_ 2566838832 SwIdField1_FEDA30 "- 15+1 characters maximum; Manufacturer SW P/N (IVECO Std. 18-2253)
-  Variable signal length, 8 bits used for dbc generation only";
CM_ SG_ 2566838832 NumOfSwIdFields_FEDA30 "- 5 (IVECO Std. 18-2253)";
CM_ BO_ 2566838835 "- Multipacket message handled by SAE Transport Protocol (J1939/21, par 5.10, Multipacket Broadcast with TP.CM/BAM, TP.DT)
-  Transport Protocol with Control Flow  (RTS, CTS, EndOfMsgAck, Conn_Abort) shall be also supported by the receiver if the multipacket message has been solicited by a Destination Specific Request
-  Variable Message Length, maximum value used for dbc generation";
CM_ SG_ 2566838835 SwIdField5_FEDA33 "- 8+1 characters maximum, IVECO Warning and Fault Database Version (IVECO Std. 18-2253)
-  Variable signal length, 8 bits used for dbc generation only";
CM_ SG_ 2566838835 SwIdField4_FEDA33 "- 15+1 characters maximum; Calibration Identification Number (IVECO Std. 18-2253)
-  Variable signal length, 8 bits used for dbc generation only";
CM_ SG_ 2566838835 SwIdField3_FEDA33 "- 8+1 characters (yyyymmdd); Manufacturer SW Issue Date, optional if Software Version is available (IVECO Std. 18-2253)
-  Variable signal length, 8 bits used for dbc generation only";
CM_ SG_ 2566838835 SwIdField2_FEDA33 "- 15+1 characters maximum; Manufacturer SW Version, Optional if Software Issue Date is available (IVECO Std. 18-2253)
-  Variable signal length, 8 bits used for dbc generation only";
CM_ SG_ 2566838835 SwIdField1_FEDA33 "- 15+1 characters maximum; Manufacturer SW P/N (IVECO Std. 18-2253)
-  Variable signal length, 8 bits used for dbc generation only";
CM_ SG_ 2566838835 NumOfSwIdFields_FEDA33 "- 5 (IVECO Std. 18-2253)";
CM_ BO_ 2566838849 "- Multipacket message handled by SAE Transport Protocol (J1939/21, par 5.10, Multipacket Broadcast with TP.CM/BAM, TP.DT)
-  Transport Protocol with Control Flow  (RTS, CTS, EndOfMsgAck, Conn_Abort) shall be also supported by the receiver if the multipacket message has been solicited by a Destination Specific Request
-  Variable Message Length, maximum value used for dbc generation";
CM_ SG_ 2566838849 SwIdField5_FEDA41 "- 8+1 characters maximum, IVECO Warning and Fault Database Version (IVECO Std. 18-2253)
-  Variable signal length, 8 bits used for dbc generation only";
CM_ SG_ 2566838849 SwIdField4_FEDA41 "- 15+1 characters maximum; Calibration Identification Number (IVECO Std. 18-2253)
-  Variable signal length, 8 bits used for dbc generation only";
CM_ SG_ 2566838849 SwIdField3_FEDA41 "- 8+1 characters (yyyymmdd); Manufacturer SW Issue Date, optional if Software Version is available (IVECO Std. 18-2253)
-  Variable signal length, 8 bits used for dbc generation only";
CM_ SG_ 2566838849 SwIdField2_FEDA41 "- 15+1 characters maximum; Manufacturer SW Version, Optional if Software Issue Date is available (IVECO Std. 18-2253)
-  Variable signal length, 8 bits used for dbc generation only";
CM_ SG_ 2566838849 SwIdField1_FEDA41 "- 15+1 characters maximum; Manufacturer SW P/N (IVECO Std. 18-2253)
-  Variable signal length, 8 bits used for dbc generation only";
CM_ SG_ 2566838849 NumOfSwIdFields_FEDA41 "- 5 (IVECO Std. 18-2253)";
CM_ BO_ 2566838857 "- Multipacket message handled by SAE Transport Protocol (J1939/21, par 5.10, Multipacket Broadcast with TP.CM/BAM, TP.DT)
-  Transport Protocol with Control Flow  (RTS, CTS, EndOfMsgAck, Conn_Abort) shall be also supported by the receiver if the multipacket message has been solicited by a Destination Specific Request
-  Variable Message Length, maximum value used for dbc generation";
CM_ SG_ 2566838857 SwIdField5_FEDA49 "- 8+1 characters maximum, IVECO Warning and Fault Database Version (IVECO Std. 18-2253)
-  Variable signal length, 8 bits used for dbc generation only";
CM_ SG_ 2566838857 SwIdField4_FEDA49 "- 15+1 characters maximum; Calibration Identification Number (IVECO Std. 18-2253)
-  Variable signal length, 8 bits used for dbc generation only";
CM_ SG_ 2566838857 SwIdField3_FEDA49 "- 8+1 characters (yyyymmdd); Manufacturer SW Issue Date, optional if Software Version is available (IVECO Std. 18-2253)
-  Variable signal length, 8 bits used for dbc generation only";
CM_ SG_ 2566838857 SwIdField2_FEDA49 "- 15+1 characters maximum; Manufacturer SW Version, Optional if Software Issue Date is available (IVECO Std. 18-2253)
-  Variable signal length, 8 bits used for dbc generation only";
CM_ SG_ 2566838857 SwIdField1_FEDA49 "- 15+1 characters maximum; Manufacturer SW P/N (IVECO Std. 18-2253)
-  Variable signal length, 8 bits used for dbc generation only";
CM_ SG_ 2566838857 NumOfSwIdFields_FEDA49 "- 5 (IVECO Std. 18-2253)";
CM_ BO_ 2566838858 "- Multipacket message handled by SAE Transport Protocol (J1939/21, par 5.10, Multipacket Broadcast with TP.CM/BAM, TP.DT)
-  Transport Protocol with Control Flow  (RTS, CTS, EndOfMsgAck, Conn_Abort) shall be also supported by the receiver if the multipacket message has been solicited by a Destination Specific Request
-  Variable Message Length, maximum value used for dbc generation";
CM_ SG_ 2566838858 SwIdField5_FEDA4A "- 8+1 characters maximum, IVECO Warning and Fault Database Version (IVECO Std. 18-2253)
-  Variable signal length, 8 bits used for dbc generation only";
CM_ SG_ 2566838858 SwIdField4_FEDA4A "- 15+1 characters maximum; Calibration Identification Number (IVECO Std. 18-2253)
-  Variable signal length, 8 bits used for dbc generation only";
CM_ SG_ 2566838858 SwIdField3_FEDA4A "- 8+1 characters (yyyymmdd); Manufacturer SW Issue Date, optional if Software Version is available (IVECO Std. 18-2253)
-  Variable signal length, 8 bits used for dbc generation only";
CM_ SG_ 2566838858 SwIdField2_FEDA4A "- 15+1 characters maximum; Manufacturer SW Version, Optional if Software Issue Date is available (IVECO Std. 18-2253)
-  Variable signal length, 8 bits used for dbc generation only";
CM_ SG_ 2566838858 SwIdField1_FEDA4A "- 15+1 characters maximum; Manufacturer SW P/N (IVECO Std. 18-2253)
-  Variable signal length, 8 bits used for dbc generation only";
CM_ SG_ 2566838858 NumOfSwIdFields_FEDA4A "- 5 (IVECO Std. 18-2253)";
CM_ BO_ 2566838861 "- Multipacket message handled by SAE Transport Protocol (J1939/21, par 5.10, Multipacket Broadcast with TP.CM/BAM, TP.DT)
-  Transport Protocol with Control Flow  (RTS, CTS, EndOfMsgAck, Conn_Abort) shall be also supported by the receiver if the multipacket message has been solicited by a Destination Specific Request
-  Variable Message Length, maximum value used for dbc generation";
CM_ SG_ 2566838861 SwIdField5_FEDA4D "- 8+1 characters maximum, IVECO Warning and Fault Database Version (IVECO Std. 18-2253)
-  Variable signal length, 8 bits used for dbc generation only";
CM_ SG_ 2566838861 SwIdField4_FEDA4D "- 15+1 characters maximum; Calibration Identification Number (IVECO Std. 18-2253)
-  Variable signal length, 8 bits used for dbc generation only";
CM_ SG_ 2566838861 SwIdField3_FEDA4D "- 8+1 characters (yyyymmdd); Manufacturer SW Issue Date, optional if Software Version is available (IVECO Std. 18-2253)
-  Variable signal length, 8 bits used for dbc generation only";
CM_ SG_ 2566838861 SwIdField2_FEDA4D "- 15+1 characters maximum; Manufacturer SW Version, Optional if Software Issue Date is available (IVECO Std. 18-2253)
-  Variable signal length, 8 bits used for dbc generation only";
CM_ SG_ 2566838861 SwIdField1_FEDA4D "- 15+1 characters maximum; Manufacturer SW P/N (IVECO Std. 18-2253)
-  Variable signal length, 8 bits used for dbc generation only";
CM_ SG_ 2566838861 NumOfSwIdFields_FEDA4D "- 5 (IVECO Std. 18-2253)";
CM_ BO_ 2566838904 "- Multipacket message handled by SAE Transport Protocol (J1939/21, par 5.10, Multipacket Broadcast with TP.CM/BAM, TP.DT)
-  Transport Protocol with Control Flow  (RTS, CTS, EndOfMsgAck, Conn_Abort) shall be also supported by the receiver if the multipacket message has been solicited by a Destination Specific Request
-  Variable Message Length, maximum value used for dbc generation";
CM_ SG_ 2566838904 SwIdField5_FEDA78 "- 8+1 characters maximum, IVECO Warning and Fault Database Version (IVECO Std. 18-2253)
-  Variable signal length, 8 bits used for dbc generation only";
CM_ SG_ 2566838904 SwIdField4_FEDA78 "- 15+1 characters maximum; Calibration Identification Number (IVECO Std. 18-2253)
-  Variable signal length, 8 bits used for dbc generation only";
CM_ SG_ 2566838904 SwIdField3_FEDA78 "- 8+1 characters (yyyymmdd); Manufacturer SW Issue Date, optional if Software Version is available (IVECO Std. 18-2253)
-  Variable signal length, 8 bits used for dbc generation only";
CM_ SG_ 2566838904 SwIdField2_FEDA78 "- 15+1 characters maximum; Manufacturer SW Version, Optional if Software Issue Date is available (IVECO Std. 18-2253)
-  Variable signal length, 8 bits used for dbc generation only";
CM_ SG_ 2566838904 SwIdField1_FEDA78 "- 15+1 characters maximum; Manufacturer SW P/N (IVECO Std. 18-2253)
-  Variable signal length, 8 bits used for dbc generation only";
CM_ SG_ 2566838904 NumOfSwIdFields_FEDA78 "- 5 (IVECO Std. 18-2253)";
CM_ BO_ 2566838908 "- Multipacket message handled by SAE Transport Protocol (J1939/21, par 5.10, Multipacket Broadcast with TP.CM/BAM, TP.DT)
-  Transport Protocol with Control Flow  (RTS, CTS, EndOfMsgAck, Conn_Abort) shall be also supported by the receiver if the multipacket message has been solicited by a Destination Specific Request
-  Variable Message Length, maximum value used for dbc generation";
CM_ SG_ 2566838908 SwIdField5_FEDA7C "- 8+1 characters maximum, IVECO Warning and Fault Database Version (IVECO Std. 18-2253)
-  Variable signal length, 8 bits used for dbc generation only";
CM_ SG_ 2566838908 SwIdField4_FEDA7C "- 15+1 characters maximum; Calibration Identification Number (IVECO Std. 18-2253)
-  Variable signal length, 8 bits used for dbc generation only";
CM_ SG_ 2566838908 SwIdField3_FEDA7C "- 8+1 characters (yyyymmdd); Manufacturer SW Issue Date, optional if Software Version is available (IVECO Std. 18-2253)
-  Variable signal length, 8 bits used for dbc generation only";
CM_ SG_ 2566838908 SwIdField2_FEDA7C "- 15+1 characters maximum; Manufacturer SW Version, Optional if Software Issue Date is available (IVECO Std. 18-2253)
-  Variable signal length, 8 bits used for dbc generation only";
CM_ SG_ 2566838908 SwIdField1_FEDA7C "- 15+1 characters maximum; Manufacturer SW P/N (IVECO Std. 18-2253)
-  Variable signal length, 8 bits used for dbc generation only";
CM_ SG_ 2566838908 NumOfSwIdFields_FEDA7C "- 5 (IVECO Std. 18-2253)";
CM_ BO_ 2566839023 "- Multipacket message handled by SAE Transport Protocol (J1939/21, par 5.10, Multipacket Broadcast with TP.CM/BAM, TP.DT)
-  Transport Protocol with Control Flow  (RTS, CTS, EndOfMsgAck, Conn_Abort) shall be also supported by the receiver if the multipacket message has been solicited by a Destination Specific Request
-  Variable Message Length, maximum value used for dbc generation";
CM_ SG_ 2566839023 SwIdField5_FEDAEF "- 8+1 characters maximum, IVECO Warning and Fault Database Version (IVECO Std. 18-2253)
-  Variable signal length, 8 bits used for dbc generation only";
CM_ SG_ 2566839023 SwIdField4_FEDAEF "- 15+1 characters maximum; Calibration Identification Number (IVECO Std. 18-2253)
-  Variable signal length, 8 bits used for dbc generation only";
CM_ SG_ 2566839023 SwIdField3_FEDAEF "- 8+1 characters (yyyymmdd); Manufacturer SW Issue Date, optional if Software Version is available (IVECO Std. 18-2253)
-  Variable signal length, 8 bits used for dbc generation only";
CM_ SG_ 2566839023 SwIdField2_FEDAEF "- 15+1 characters maximum; Manufacturer SW Version, Optional if Software Issue Date is available (IVECO Std. 18-2253)
-  Variable signal length, 8 bits used for dbc generation only";
CM_ SG_ 2566839023 SwIdField1_FEDAEF "- 15+1 characters maximum; Manufacturer SW P/N (IVECO Std. 18-2253)
-  Variable signal length, 8 bits used for dbc generation only";
CM_ SG_ 2566839023 NumOfSwIdFields_FEDAEF "- 5 (IVECO Std. 18-2253)";
CM_ BO_ 2566839026 "- Multipacket message handled by SAE Transport Protocol (J1939/21, par 5.10, Multipacket Broadcast with TP.CM/BAM, TP.DT)
-  Transport Protocol with Control Flow  (RTS, CTS, EndOfMsgAck, Conn_Abort) shall be also supported by the receiver if the multipacket message has been solicited by a Destination Specific Request
-  Variable Message Length, maximum value used for dbc generation";
CM_ SG_ 2566839026 SwIdField5_FEDAF2 "- 8+1 characters maximum, IVECO Warning and Fault Database Version (IVECO Std. 18-2253)
-  Variable signal length, 8 bits used for dbc generation only";
CM_ SG_ 2566839026 SwIdField4_FEDAF2 "- 15+1 characters maximum; Calibration Identification Number (IVECO Std. 18-2253)
-  Variable signal length, 8 bits used for dbc generation only";
CM_ SG_ 2566839026 SwIdField3_FEDAF2 "- 8+1 characters (yyyymmdd); Manufacturer SW Issue Date, optional if Software Version is available (IVECO Std. 18-2253)
-  Variable signal length, 8 bits used for dbc generation only";
CM_ SG_ 2566839026 SwIdField2_FEDAF2 "- 15+1 characters maximum; Manufacturer SW Version, Optional if Software Issue Date is available (IVECO Std. 18-2253)
-  Variable signal length, 8 bits used for dbc generation only";
CM_ SG_ 2566839026 SwIdField1_FEDAF2 "- 15+1 characters maximum; Manufacturer SW P/N (IVECO Std. 18-2253)
-  Variable signal length, 8 bits used for dbc generation only";
CM_ SG_ 2566839026 NumOfSwIdFields_FEDAF2 "- 5 (IVECO Std. 18-2253)";
CM_ BO_ 2566839027 "- Multipacket message handled by SAE Transport Protocol (J1939/21, par 5.10, Multipacket Broadcast with TP.CM/BAM, TP.DT)
-  Transport Protocol with Control Flow  (RTS, CTS, EndOfMsgAck, Conn_Abort) shall be also supported by the receiver if the multipacket message has been solicited by a Destination Specific Request
-  Variable Message Length, maximum value used for dbc generation";
CM_ SG_ 2566839027 SwIdField5_FEDAF3 "- 8+1 characters maximum, IVECO Warning and Fault Database Version (IVECO Std. 18-2253)
-  Variable signal length, 8 bits used for dbc generation only";
CM_ SG_ 2566839027 SwIdField4_FEDAF3 "- 15+1 characters maximum; Calibration Identification Number (IVECO Std. 18-2253)
-  Variable signal length, 8 bits used for dbc generation only";
CM_ SG_ 2566839027 SwIdField3_FEDAF3 "- 8+1 characters (yyyymmdd); Manufacturer SW Issue Date, optional if Software Version is available (IVECO Std. 18-2253)
-  Variable signal length, 8 bits used for dbc generation only";
CM_ SG_ 2566839027 SwIdField2_FEDAF3 "- 15+1 characters maximum; Manufacturer SW Version, Optional if Software Issue Date is available (IVECO Std. 18-2253)
-  Variable signal length, 8 bits used for dbc generation only";
CM_ SG_ 2566839027 SwIdField1_FEDAF3 "- 15+1 characters maximum; Manufacturer SW P/N (IVECO Std. 18-2253)
-  Variable signal length, 8 bits used for dbc generation only";
CM_ SG_ 2566839027 NumOfSwIdFields_FEDAF3 "- 5 (IVECO Std. 18-2253)";
CM_ BO_ 2364543755 "- SAE Trans.Rate=10ms";
BA_DEF_ BO_  "CI_MsgDefinition" STRING ;
BA_DEF_ BO_  "CI_MsgId" INT 0 2147483647;
BA_DEF_ BO_  "CI_MsgName" STRING ;
BA_DEF_ BO_  "GenMsgCycleTime" INT 0 3600000;
BA_DEF_ BO_  "GenMsgCycleTimeFast" INT 0 3600000;
BA_DEF_ BO_  "GenMsgDelayTime" INT 0 3600000;
BA_DEF_ BO_  "GenMsgILSupport" ENUM  "No","Yes";
BA_DEF_ BO_  "GenMsgNrOfRepetition" INT 0 1000000;
BA_DEF_ BO_  "GenMsgRequestable" INT 0 1;
BA_DEF_ BO_  "GenMsgSendType" ENUM  "cyclic","NotUsed","NotUsed","NotUsed","NotUsed","NotUsed","NotUsed","IfActive","noMsgSendType";
BA_DEF_ BO_  "GenMsgStartDelayTime" INT 0 100000;
BA_DEF_ BO_  "TpJ1939VarDlc" ENUM  "No","Yes";
BA_DEF_ BO_  "VFrameFormat" ENUM  "StandardCAN","ExtendedCAN","reserved","J1939PG";
BA_DEF_ SG_  "CI_ParId" STRING ;
BA_DEF_ SG_  "CI_SigId" INT 0 2147483647;
BA_DEF_ SG_  "CI_SigName" STRING ;
BA_DEF_ SG_  "GenSigEVName" STRING ;
BA_DEF_ SG_  "GenSigILSupport" ENUM  "No","Yes";
BA_DEF_ SG_  "GenSigInactiveValue" INT 0 2147483647;
BA_DEF_ SG_  "GenSigSendType" ENUM  "Cyclic","OnWrite","OnWriteWithRepetition","OnChange","OnChangeWithRepetition","IfActive","IfActiveWithRepetition","NoSigSendType";
BA_DEF_ SG_  "GenSigStartValue" INT 0 2147483647;
BA_DEF_ SG_  "GenSigTimeoutTime_PCM" INT 0 3600000;
BA_DEF_ SG_  "GenSigTimeoutTime_SGW" INT 0 3600000;
BA_DEF_ SG_  "SPN" INT 0 524287;
BA_DEF_ SG_  "SigType" ENUM  "Default","Range","RangeSigned","ASCII","Discrete","Control","ReferencePGN","DTC","StringDelimiter","StringLength","StringLengthControl";
BA_DEF_DEF_  "CI_MsgDefinition" "";
BA_DEF_DEF_  "CI_MsgId" 0;
BA_DEF_DEF_  "CI_MsgName" "";
BA_DEF_DEF_  "GenMsgCycleTime" 0;
BA_DEF_DEF_  "GenMsgCycleTimeFast" 0;
BA_DEF_DEF_  "GenMsgDelayTime" 1;
BA_DEF_DEF_  "GenMsgILSupport" "Yes";
BA_DEF_DEF_  "GenMsgNrOfRepetition" 0;
BA_DEF_DEF_  "GenMsgRequestable" 0;
BA_DEF_DEF_  "GenMsgSendType" "noMsgSendType";
BA_DEF_DEF_  "GenMsgStartDelayTime" 0;
BA_DEF_DEF_  "TpJ1939VarDlc" "No";
BA_DEF_DEF_  "VFrameFormat" "J1939PG";
BA_DEF_DEF_  "CI_ParId" "";
BA_DEF_DEF_  "CI_SigId" 0;
BA_DEF_DEF_  "CI_SigName" "";
BA_DEF_DEF_  "GenSigEVName" "Env@Nodename_@Signame";
BA_DEF_DEF_  "GenSigILSupport" "Yes";
BA_DEF_DEF_  "GenSigInactiveValue" 0;
BA_DEF_DEF_  "GenSigSendType" "NoSigSendType";
BA_DEF_DEF_  "GenSigStartValue" 0;
BA_DEF_DEF_  "GenSigTimeoutTime_PCM" 0;
BA_DEF_DEF_  "GenSigTimeoutTime_SGW" 0;
BA_DEF_DEF_  "SPN" 0;
BA_DEF_DEF_  "SigType" "Default";
BA_ "CI_MsgDefinition" BO_ 2566912807 "Iveco Daily Electric";
BA_ "CI_MsgId" BO_ 2566912807 3692;
BA_ "CI_MsgName" BO_ 2566912807 "PB_VmuInfo2_27 - Proprietary B - VMU Information 2";
BA_ "GenMsgCycleTime" BO_ 2566912807 100;
BA_ "GenMsgCycleTimeFast" BO_ 2566912807 100;
BA_ "GenMsgDelayTime" BO_ 2566912807 50;
BA_ "GenMsgSendType" BO_ 2566912807 0;
BA_ "GenMsgStartDelayTime" BO_ 2566912807 88;
BA_ "CI_MsgDefinition" BO_ 2566892839 "Iveco Proprietary";
BA_ "CI_MsgId" BO_ 2566892839 44732;
BA_ "CI_MsgName" BO_ 2566892839 "PB_VmuInfo3_27 - Proprietary B - VMU Information 3";
BA_ "GenMsgCycleTime" BO_ 2566892839 50;
BA_ "GenMsgCycleTimeFast" BO_ 2566892839 50;
BA_ "GenMsgDelayTime" BO_ 2566892839 25;
BA_ "GenMsgSendType" BO_ 2566892839 0;
BA_ "GenMsgStartDelayTime" BO_ 2566892839 48;
BA_ "CI_MsgDefinition" BO_ 2566904641 "Iveco NH Proprietary";
BA_ "CI_MsgId" BO_ 2566904641 10301;
BA_ "CI_MsgName" BO_ 2566904641 "PB_VN_41 - Proprietary B - Iveco Vehicle Navigation";
BA_ "GenMsgCycleTime" BO_ 2566904641 1000;
BA_ "GenMsgCycleTimeFast" BO_ 2566904641 1000;
BA_ "GenMsgDelayTime" BO_ 2566904641 100;
BA_ "GenMsgSendType" BO_ 2566904641 0;
BA_ "GenMsgStartDelayTime" BO_ 2566904641 276;
BA_ "CI_MsgDefinition" BO_ 2566896705 "Iveco Proprietary";
BA_ "CI_MsgId" BO_ 2566896705 10313;
BA_ "CI_MsgName" BO_ 2566896705 "PB_VND_41 - Proprietary B - Vehicle Navigation Destination";
BA_ "GenMsgCycleTime" BO_ 2566896705 1000;
BA_ "GenMsgCycleTimeFast" BO_ 2566896705 1000;
BA_ "GenMsgDelayTime" BO_ 2566896705 500;
BA_ "GenMsgSendType" BO_ 2566896705 0;
BA_ "GenMsgStartDelayTime" BO_ 2566896705 268;
BA_ "CI_MsgDefinition" BO_ 2566896714 "Iveco Proprietary";
BA_ "CI_MsgId" BO_ 2566896714 10316;
BA_ "CI_MsgName" BO_ 2566896714 "PB_VND_4A - Proprietary B - Vehicle Navigation Destination";
BA_ "GenMsgCycleTime" BO_ 2566896714 1000;
BA_ "GenMsgCycleTimeFast" BO_ 2566896714 1000;
BA_ "GenMsgDelayTime" BO_ 2566896714 500;
BA_ "GenMsgSendType" BO_ 2566896714 0;
BA_ "GenMsgStartDelayTime" BO_ 2566896714 30;
BA_ "CI_MsgDefinition" BO_ 2634009665 "Iveco Proprietary";
BA_ "CI_MsgId" BO_ 2634009665 44876;
BA_ "CI_MsgName" BO_ 2634009665 "PB_VNS_41 - Proprietary B - Iveco Vehicle Navigation Street Name";
BA_ "TpJ1939VarDlc" BO_ 2634009665 1;
BA_ "CI_MsgDefinition" BO_ 2566892311 "Iveco Proprietary";
BA_ "CI_MsgId" BO_ 2566892311 42263;
BA_ "CI_MsgName" BO_ 2566892311 "PB_VRUP1_17 - Proprietary B - Vulnerable Road User Protection 1";
BA_ "GenMsgCycleTime" BO_ 2566892311 1000;
BA_ "GenMsgCycleTimeFast" BO_ 2566892311 1000;
BA_ "GenMsgDelayTime" BO_ 2566892311 100;
BA_ "GenMsgSendType" BO_ 2566892311 0;
BA_ "GenMsgStartDelayTime" BO_ 2566892311 261;
BA_ "CI_MsgDefinition" BO_ 2566892362 "Iveco Proprietary";
BA_ "CI_MsgId" BO_ 2566892362 42271;
BA_ "CI_MsgName" BO_ 2566892362 "PB_VRUP1_4A - Proprietary B - Vulnerable Road User Protection 1";
BA_ "CI_MsgDefinition" BO_ 2566892444 "Iveco Proprietary";
BA_ "CI_MsgId" BO_ 2566892444 42244;
BA_ "CI_MsgName" BO_ 2566892444 "PB_VRUP1_9C - Proprietary B - Vulnerable Road User Protection 1";
BA_ "GenMsgCycleTime" BO_ 2566892444 200;
BA_ "GenMsgCycleTimeFast" BO_ 2566892444 20;
BA_ "GenMsgDelayTime" BO_ 2566892444 10;
BA_ "GenMsgSendType" BO_ 2566892444 0;
BA_ "GenMsgStartDelayTime" BO_ 2566892444 25;
BA_ "CI_MsgDefinition" BO_ 2566892567 "Iveco Proprietary";
BA_ "CI_MsgId" BO_ 2566892567 42294;
BA_ "CI_MsgName" BO_ 2566892567 "PB_VRUP2_17 - Proprietary B - Vulnerable Road User Protection 1";
BA_ "GenMsgCycleTime" BO_ 2566892567 1000;
BA_ "GenMsgCycleTimeFast" BO_ 2566892567 1000;
BA_ "GenMsgDelayTime" BO_ 2566892567 100;
BA_ "GenMsgSendType" BO_ 2566892567 0;
BA_ "GenMsgStartDelayTime" BO_ 2566892567 262;
BA_ "CI_MsgDefinition" BO_ 2566892618 "Iveco Proprietary";
BA_ "CI_MsgId" BO_ 2566892618 42728;
BA_ "CI_MsgName" BO_ 2566892618 "PB_VRUP2_4A - Proprietary B - Vulnerable Road User Protection 1";
BA_ "CI_MsgDefinition" BO_ 2566892702 "Iveco Proprietary";
BA_ "CI_MsgId" BO_ 2566892702 42279;
BA_ "CI_MsgName" BO_ 2566892702 "PB_VRUP2_9E - Proprietary B - Vulnerable Road User Protection 1";
BA_ "GenMsgCycleTime" BO_ 2566892702 200;
BA_ "GenMsgCycleTimeFast" BO_ 2566892702 50;
BA_ "GenMsgDelayTime" BO_ 2566892702 25;
BA_ "GenMsgSendType" BO_ 2566892702 0;
BA_ "GenMsgStartDelayTime" BO_ 2566892702 46;
BA_ "CI_MsgDefinition" BO_ 2566892703 "Iveco Proprietary";
BA_ "CI_MsgId" BO_ 2566892703 42286;
BA_ "CI_MsgName" BO_ 2566892703 "PB_VRUP2_9F - Proprietary B - Vulnerable Road User Protection 1";
BA_ "GenMsgCycleTime" BO_ 2566892703 200;
BA_ "GenMsgCycleTimeFast" BO_ 2566892703 50;
BA_ "GenMsgDelayTime" BO_ 2566892703 25;
BA_ "GenMsgSendType" BO_ 2566892703 0;
BA_ "GenMsgStartDelayTime" BO_ 2566892703 47;
BA_ "CI_MsgDefinition" BO_ 2566865010 "Iveco SPR2 Proprietary";
BA_ "CI_MsgId" BO_ 2566865010 10836;
BA_ "CI_MsgName" BO_ 2566865010 "PtoSts - PTO Status";
BA_ "GenMsgCycleTime" BO_ 2566865010 1000;
BA_ "GenMsgCycleTimeFast" BO_ 2566865010 1000;
BA_ "GenMsgDelayTime" BO_ 2566865010 500;
BA_ "GenMsgSendType" BO_ 2566865010 0;
BA_ "GenMsgStartDelayTime" BO_ 2566865010 254;
BA_ "CI_MsgDefinition" BO_ 2566840592 "J1939DA";
BA_ "CI_MsgId" BO_ 2566840592 1075;
BA_ "CI_MsgName" BO_ 2566840592 "RC_DR - Retarder Configuration";
BA_ "GenMsgCycleTime" BO_ 2566840592 5000;
BA_ "GenMsgCycleTimeFast" BO_ 2566840592 5000;
BA_ "GenMsgDelayTime" BO_ 2566840592 500;
BA_ "GenMsgSendType" BO_ 2566840592 0;
BA_ "GenMsgStartDelayTime" BO_ 2566840592 337;
BA_ "CI_MsgDefinition" BO_ 2565537610 "J1939-21";
BA_ "CI_MsgId" BO_ 2565537610 26957;
BA_ "CI_MsgName" BO_ 2565537610 "RQST_4A - Request";
BA_ "CI_MsgDefinition" BO_ 2565472330 "J1939-21";
BA_ "CI_MsgId" BO_ 2565472330 26939;
BA_ "CI_MsgName" BO_ 2565472330 "RQST_4A_00 - Request";
BA_ "CI_MsgDefinition" BO_ 2565473098 "J1939-21";
BA_ "CI_MsgId" BO_ 2565473098 26941;
BA_ "CI_MsgName" BO_ 2565473098 "RQST_4A_03 - Request";
BA_ "CI_MsgDefinition" BO_ 2565474122 "J1939-21";
BA_ "CI_MsgId" BO_ 2565474122 38656;
BA_ "CI_MsgName" BO_ 2565474122 "RQST_4A_07 - Request";
BA_ "CI_MsgDefinition" BO_ 2565478986 "J1939-21";
BA_ "CI_MsgId" BO_ 2565478986 34420;
BA_ "CI_MsgName" BO_ 2565478986 "RQST_4A_1A - Request";
BA_ "CI_MsgDefinition" BO_ 2565480778 "J1939-21";
BA_ "CI_MsgId" BO_ 2565480778 26947;
BA_ "CI_MsgName" BO_ 2565480778 "RQST_4A_21 - Request";
BA_ "CI_MsgDefinition" BO_ 2565481546 "J1939-21";
BA_ "CI_MsgId" BO_ 2565481546 38658;
BA_ "CI_MsgName" BO_ 2565481546 "RQST_4A_24 - Request";
BA_ "CI_MsgDefinition" BO_ 2565482314 "J1939-21";
BA_ "CI_MsgId" BO_ 2565482314 26949;
BA_ "CI_MsgName" BO_ 2565482314 "RQST_4A_27 - Request";
BA_ "CI_MsgDefinition" BO_ 2565485386 "J1939-21";
BA_ "CI_MsgId" BO_ 2565485386 26951;
BA_ "CI_MsgName" BO_ 2565485386 "RQST_4A_33 - Request";
BA_ "CI_MsgDefinition" BO_ 2565488970 "J1939-21";
BA_ "CI_MsgId" BO_ 2565488970 26953;
BA_ "CI_MsgName" BO_ 2565488970 "RQST_4A_41 - Request";
BA_ "CI_MsgDefinition" BO_ 2565491018 "J1939-21";
BA_ "CI_MsgId" BO_ 2565491018 34422;
BA_ "CI_MsgName" BO_ 2565491018 "RQST_4A_49 - Request";
BA_ "CI_MsgDefinition" BO_ 2565504074 "J1939-21";
BA_ "CI_MsgId" BO_ 2565504074 36876;
BA_ "CI_MsgName" BO_ 2565504074 "RQST_4A_7C - Request";
BA_ "CI_MsgDefinition" BO_ 2565506634 "J1939-21";
BA_ "CI_MsgId" BO_ 2565506634 40589;
BA_ "CI_MsgName" BO_ 2565506634 "RQST_4A_86 - Request";
BA_ "CI_MsgDefinition" BO_ 2565506890 "J1939-21";
BA_ "CI_MsgId" BO_ 2565506890 40591;
BA_ "CI_MsgName" BO_ 2565506890 "RQST_4A_87 - Request";
BA_ "CI_MsgDefinition" BO_ 2565533258 "J1939-21";
BA_ "CI_MsgId" BO_ 2565533258 26955;
BA_ "CI_MsgName" BO_ 2565533258 "RQST_4A_EE - Request";
BA_ "CI_MsgDefinition" BO_ 2565533514 "J1939-21";
BA_ "CI_MsgId" BO_ 2565533514 34787;
BA_ "CI_MsgName" BO_ 2565533514 "RQST_4A_EF - Request";
BA_ "CI_MsgDefinition" BO_ 2565534282 "J1939-21";
BA_ "CI_MsgId" BO_ 2565534282 39146;
BA_ "CI_MsgName" BO_ 2565534282 "RQST_4A_F2 - Request";
BA_ "CI_MsgDefinition" BO_ 2565534538 "J1939-21";
BA_ "CI_MsgId" BO_ 2565534538 32808;
BA_ "CI_MsgName" BO_ 2565534538 "RQST_4A_F3 - Request";
BA_ "CI_MsgDefinition" BO_ 2565534794 "J1939-21";
BA_ "CI_MsgId" BO_ 2565534794 26840;
BA_ "CI_MsgName" BO_ 2565534794 "RQST_4A_F4 - Request";
BA_ "CI_MsgDefinition" BO_ 2565535050 "J1939-21";
BA_ "CI_MsgId" BO_ 2565535050 26842;
BA_ "CI_MsgName" BO_ 2565535050 "RQST_4A_F5 - Request";
BA_ "CI_MsgDefinition" BO_ 2565535306 "J1939-21";
BA_ "CI_MsgId" BO_ 2565535306 26844;
BA_ "CI_MsgName" BO_ 2565535306 "RQST_4A_F6 - Request";
BA_ "CI_MsgDefinition" BO_ 2566832128 "J1939DA";
BA_ "CI_MsgId" BO_ 2566832128 5866;
BA_ "CI_MsgName" BO_ 2566832128 "SERV_00 - Service Information";
BA_ "CI_MsgDefinition" BO_ 2566832161 "J1939DA";
BA_ "CI_MsgId" BO_ 2566832161 5890;
BA_ "CI_MsgName" BO_ 2566832161 "SERV_21 - Service Information";
BA_ "GenMsgCycleTime" BO_ 2566832161 1000;
BA_ "GenMsgCycleTimeFast" BO_ 2566832161 1000;
BA_ "GenMsgDelayTime" BO_ 2566832161 500;
BA_ "GenMsgSendType" BO_ 2566832161 0;
BA_ "GenMsgStartDelayTime" BO_ 2566832161 183;
BA_ "CI_MsgDefinition" BO_ 2566832366 "J1939DA";
BA_ "CI_MsgId" BO_ 2566832366 5916;
BA_ "CI_MsgName" BO_ 2566832366 "SERV_EE - Service Information";
BA_ "CI_MsgDefinition" BO_ 2566841344 "J1939DA";
BA_ "CI_MsgId" BO_ 2566841344 2164;
BA_ "CI_MsgName" BO_ 2566841344 "SHUTDN - Shutdown";
BA_ "GenMsgCycleTime" BO_ 2566841344 1000;
BA_ "GenMsgCycleTimeFast" BO_ 2566841344 1000;
BA_ "GenMsgDelayTime" BO_ 2566841344 500;
BA_ "GenMsgSendType" BO_ 2566841344 0;
BA_ "GenMsgStartDelayTime" BO_ 2566841344 228;
BA_ "CI_MsgDefinition" BO_ 2566838789 "J1939DA";
BA_ "CI_MsgId" BO_ 2566838789 26223;
BA_ "CI_MsgName" BO_ 2566838789 "SOFT_05 - Software Identification";
BA_ "TpJ1939VarDlc" BO_ 2566838789 1;
BA_ "CI_MsgDefinition" BO_ 2566838791 "J1939DA";
BA_ "CI_MsgId" BO_ 2566838791 38558;
BA_ "CI_MsgName" BO_ 2566838791 "SOFT_07 - Software Identification";
BA_ "TpJ1939VarDlc" BO_ 2566838791 1;
BA_ "CI_MsgDefinition" BO_ 2566838810 "J1939DA";
BA_ "CI_MsgId" BO_ 2566838810 34486;
BA_ "CI_MsgName" BO_ 2566838810 "SOFT_1A - Software Identification";
BA_ "TpJ1939VarDlc" BO_ 2566838810 1;
BA_ "CI_MsgDefinition" BO_ 2566838813 "J1939DA";
BA_ "CI_MsgId" BO_ 2566838813 26279;
BA_ "CI_MsgName" BO_ 2566838813 "SOFT_1D - Software Identification";
BA_ "TpJ1939VarDlc" BO_ 2566838813 1;
BA_ "CI_MsgDefinition" BO_ 2566838820 "J1939DA";
BA_ "CI_MsgId" BO_ 2566838820 38565;
BA_ "CI_MsgName" BO_ 2566838820 "SOFT_24 - Software Identification";
BA_ "TpJ1939VarDlc" BO_ 2566838820 1;
BA_ "CI_MsgDefinition" BO_ 2566838823 "J1939DA";
BA_ "CI_MsgId" BO_ 2566838823 26293;
BA_ "CI_MsgName" BO_ 2566838823 "SOFT_27 - Software Identification";
BA_ "TpJ1939VarDlc" BO_ 2566838823 1;
BA_ "CI_MsgDefinition" BO_ 2566838831 "J1939DA";
BA_ "CI_MsgId" BO_ 2566838831 26307;
BA_ "CI_MsgName" BO_ 2566838831 "SOFT_2F - Software Identification";
BA_ "TpJ1939VarDlc" BO_ 2566838831 1;
BA_ "CI_MsgDefinition" BO_ 2566838832 "J1939DA";
BA_ "CI_MsgId" BO_ 2566838832 39844;
BA_ "CI_MsgName" BO_ 2566838832 "SOFT_30 - Software Identification";
BA_ "GenMsgDelayTime" BO_ 2566838832 10;
BA_ "TpJ1939VarDlc" BO_ 2566838832 1;
BA_ "CI_MsgDefinition" BO_ 2566838835 "J1939DA";
BA_ "CI_MsgId" BO_ 2566838835 26314;
BA_ "CI_MsgName" BO_ 2566838835 "SOFT_33 - Software Identification";
BA_ "TpJ1939VarDlc" BO_ 2566838835 1;
BA_ "CI_MsgDefinition" BO_ 2566838849 "J1939DA";
BA_ "CI_MsgId" BO_ 2566838849 26328;
BA_ "CI_MsgName" BO_ 2566838849 "SOFT_41 - Software Identification";
BA_ "TpJ1939VarDlc" BO_ 2566838849 1;
BA_ "CI_MsgDefinition" BO_ 2566838857 "J1939DA";
BA_ "CI_MsgId" BO_ 2566838857 34493;
BA_ "CI_MsgName" BO_ 2566838857 "SOFT_49 - Software Identification";
BA_ "TpJ1939VarDlc" BO_ 2566838857 1;
BA_ "CI_MsgDefinition" BO_ 2566838858 "J1939DA";
BA_ "CI_MsgId" BO_ 2566838858 26363;
BA_ "CI_MsgName" BO_ 2566838858 "SOFT_4A - Software Identification";
BA_ "TpJ1939VarDlc" BO_ 2566838858 1;
BA_ "CI_MsgDefinition" BO_ 2566838861 "J1939DA";
BA_ "CI_MsgId" BO_ 2566838861 37242;
BA_ "CI_MsgName" BO_ 2566838861 "SOFT_4D - Software Identification";
BA_ "TpJ1939VarDlc" BO_ 2566838861 1;
BA_ "CI_MsgDefinition" BO_ 2566838904 "J1939DA";
BA_ "CI_MsgId" BO_ 2566838904 40195;
BA_ "CI_MsgName" BO_ 2566838904 "SOFT_78 - Software Identification";
BA_ "TpJ1939VarDlc" BO_ 2566838904 1;
BA_ "CI_MsgDefinition" BO_ 2566838908 "J1939DA";
BA_ "CI_MsgId" BO_ 2566838908 36827;
BA_ "CI_MsgName" BO_ 2566838908 "SOFT_7C - Software Identification";
BA_ "TpJ1939VarDlc" BO_ 2566838908 1;
BA_ "CI_MsgDefinition" BO_ 2566839023 "J1939DA";
BA_ "CI_MsgId" BO_ 2566839023 34794;
BA_ "CI_MsgName" BO_ 2566839023 "SOFT_EF - Software Identification";
BA_ "TpJ1939VarDlc" BO_ 2566839023 1;
BA_ "CI_MsgDefinition" BO_ 2566839026 "J1939DA";
BA_ "CI_MsgId" BO_ 2566839026 39082;
BA_ "CI_MsgName" BO_ 2566839026 "SOFT_F2 - Software Identification";
BA_ "TpJ1939VarDlc" BO_ 2566839026 1;
BA_ "CI_MsgDefinition" BO_ 2566839027 "J1939DA";
BA_ "CI_MsgId" BO_ 2566839027 33380;
BA_ "CI_MsgName" BO_ 2566839027 "SOFT_F3 - Software Identification";
BA_ "TpJ1939VarDlc" BO_ 2566839027 1;
BA_ "CI_MsgDefinition" BO_ 2364543755 "J1939DA";
BA_ "CI_MsgId" BO_ 2364543755 891;
BA_ "CI_MsgName" BO_ 2364543755 "SSI_0B - Slope Sensor Information";
BA_ "GenMsgCycleTime" BO_ 2364543755 100;
BA_ "GenMsgCycleTimeFast" BO_ 2364543755 100;
BA_ "GenMsgDelayTime" BO_ 2364543755 10;
BA_ "GenMsgSendType" BO_ 2364543755 0;
BA_ "GenMsgStartDelayTime" BO_ 2364543755 52;
BA_ "CI_ParId" SG_ 2566912807 MsgCks_FFFB27 "7042";
BA_ "CI_SigId" SG_ 2566912807 MsgCks_FFFB27 40253;
BA_ "CI_SigName" SG_ 2566912807 MsgCks_FFFB27 "Message Checksum";
BA_ "GenSigTimeoutTime_PCM" SG_ 2566912807 MsgCks_FFFB27 500;
BA_ "SPN" SG_ 2566912807 MsgCks_FFFB27 7042;
BA_ "SigType" SG_ 2566912807 MsgCks_FFFB27 1;
BA_ "CI_ParId" SG_ 2566912807 VacuumPumpFail "ID2587";
BA_ "CI_SigId" SG_ 2566912807 VacuumPumpFail 45400;
BA_ "CI_SigName" SG_ 2566912807 VacuumPumpFail "Vacuum Pump Failure";
BA_ "GenSigTimeoutTime_PCM" SG_ 2566912807 VacuumPumpFail 500;
BA_ "SigType" SG_ 2566912807 VacuumPumpFail 4;
BA_ "CI_ParId" SG_ 2566912807 MsgCnt_FFFB27 "7041";
BA_ "CI_SigId" SG_ 2566912807 MsgCnt_FFFB27 40252;
BA_ "CI_SigName" SG_ 2566912807 MsgCnt_FFFB27 "Message Counter";
BA_ "GenSigTimeoutTime_PCM" SG_ 2566912807 MsgCnt_FFFB27 500;
BA_ "SPN" SG_ 2566912807 MsgCnt_FFFB27 7041;
BA_ "CI_ParId" SG_ 2566912807 ParkLckFail "ID2586";
BA_ "CI_SigId" SG_ 2566912807 ParkLckFail 45399;
BA_ "CI_SigName" SG_ 2566912807 ParkLckFail "Park Lock Failure";
BA_ "GenSigTimeoutTime_PCM" SG_ 2566912807 ParkLckFail 500;
BA_ "SigType" SG_ 2566912807 ParkLckFail 4;
BA_ "CI_ParId" SG_ 2566912807 ElLoadPrio "ID1504";
BA_ "CI_SigId" SG_ 2566912807 ElLoadPrio 35831;
BA_ "CI_SigName" SG_ 2566912807 ElLoadPrio "Electrical Load Priority";
BA_ "GenSigTimeoutTime_PCM" SG_ 2566912807 ElLoadPrio 500;
BA_ "CI_ParId" SG_ 2566912807 HvacFunctSts "ID1514";
BA_ "CI_SigId" SG_ 2566912807 HvacFunctSts 35252;
BA_ "CI_SigName" SG_ 2566912807 HvacFunctSts "HVAC Functional Status";
BA_ "GenSigTimeoutTime_PCM" SG_ 2566912807 HvacFunctSts 500;
BA_ "CI_ParId" SG_ 2566912807 HighPwrAvPc "ID1510";
BA_ "CI_SigId" SG_ 2566912807 HighPwrAvPc 33132;
BA_ "CI_SigName" SG_ 2566912807 HighPwrAvPc "High Power Available Percent ";
BA_ "GenSigTimeoutTime_PCM" SG_ 2566912807 HighPwrAvPc 500;
BA_ "SigType" SG_ 2566912807 HighPwrAvPc 1;
BA_ "CI_ParId" SG_ 2566912807 VmuHvSysSevFail "ID2578";
BA_ "CI_SigId" SG_ 2566912807 VmuHvSysSevFail 45356;
BA_ "CI_SigName" SG_ 2566912807 VmuHvSysSevFail "VMU HV System Severe Failure";
BA_ "GenSigTimeoutTime_PCM" SG_ 2566912807 VmuHvSysSevFail 500;
BA_ "SigType" SG_ 2566912807 VmuHvSysSevFail 4;
BA_ "CI_ParId" SG_ 2566912807 VmuHvBatFail "ID2577";
BA_ "CI_SigId" SG_ 2566912807 VmuHvBatFail 45355;
BA_ "CI_SigName" SG_ 2566912807 VmuHvBatFail "VMU HV Battery Failure";
BA_ "GenSigTimeoutTime_PCM" SG_ 2566912807 VmuHvBatFail 500;
BA_ "SigType" SG_ 2566912807 VmuHvBatFail 4;
BA_ "CI_ParId" SG_ 2566912807 FastChgMode "ID1509";
BA_ "CI_SigId" SG_ 2566912807 FastChgMode 32956;
BA_ "CI_SigName" SG_ 2566912807 FastChgMode "Fast Charging Mode";
BA_ "GenSigTimeoutTime_PCM" SG_ 2566912807 FastChgMode 500;
BA_ "SigType" SG_ 2566912807 FastChgMode 4;
BA_ "CI_ParId" SG_ 2566912807 SlowChgMode "ID1508";
BA_ "CI_SigId" SG_ 2566912807 SlowChgMode 32955;
BA_ "CI_SigName" SG_ 2566912807 SlowChgMode "Slow Charging Mode";
BA_ "GenSigTimeoutTime_PCM" SG_ 2566912807 SlowChgMode 500;
BA_ "SigType" SG_ 2566912807 SlowChgMode 4;
BA_ "CI_ParId" SG_ 2566912807 ActElMachPwrInKw "ID1507";
BA_ "CI_SigId" SG_ 2566912807 ActElMachPwrInKw 3694;
BA_ "CI_SigName" SG_ 2566912807 ActElMachPwrInKw "Actual Electric Machine Power in KW";
BA_ "GenSigTimeoutTime_PCM" SG_ 2566912807 ActElMachPwrInKw 500;
BA_ "SigType" SG_ 2566912807 ActElMachPwrInKw 1;
BA_ "CI_ParId" SG_ 2566912807 EnergyInstEcon "ID1506";
BA_ "CI_SigId" SG_ 2566912807 EnergyInstEcon 3693;
BA_ "CI_SigName" SG_ 2566912807 EnergyInstEcon "Energy Instantaneous Economy";
BA_ "GenSigTimeoutTime_PCM" SG_ 2566912807 EnergyInstEcon 500;
BA_ "SigType" SG_ 2566912807 EnergyInstEcon 1;
BA_ "CI_ParId" SG_ 2566892839 ActMaxAvRegenPcTrq_FFAD27 "ID2511";
BA_ "CI_SigId" SG_ 2566892839 ActMaxAvRegenPcTrq_FFAD27 44736;
BA_ "CI_SigName" SG_ 2566892839 ActMaxAvRegenPcTrq_FFAD27 "Actual Maximum Available Regeneration - Percent Torque";
BA_ "GenSigTimeoutTime_PCM" SG_ 2566892839 ActMaxAvRegenPcTrq_FFAD27 500;
BA_ "SigType" SG_ 2566892839 ActMaxAvRegenPcTrq_FFAD27 1;
BA_ "CI_ParId" SG_ 2566892839 EngSpeed1 "4201";
BA_ "CI_SigId" SG_ 2566892839 EngSpeed1 44735;
BA_ "CI_SigName" SG_ 2566892839 EngSpeed1 "Engine Speed 1";
BA_ "GenSigTimeoutTime_PCM" SG_ 2566892839 EngSpeed1 500;
BA_ "SPN" SG_ 2566892839 EngSpeed1 4201;
BA_ "SigType" SG_ 2566892839 EngSpeed1 1;
BA_ "CI_ParId" SG_ 2566892839 ParkBrkCmd_FFAD27 "5630";
BA_ "CI_SigId" SG_ 2566892839 ParkBrkCmd_FFAD27 45398;
BA_ "CI_SigName" SG_ 2566892839 ParkBrkCmd_FFAD27 "Park Brake Command";
BA_ "GenSigTimeoutTime_PCM" SG_ 2566892839 ParkBrkCmd_FFAD27 500;
BA_ "SPN" SG_ 2566892839 ParkBrkCmd_FFAD27 5630;
BA_ "SigType" SG_ 2566892839 ParkBrkCmd_FFAD27 4;
BA_ "CI_ParId" SG_ 2566904641 RoadType "I247";
BA_ "CI_SigId" SG_ 2566904641 RoadType 10310;
BA_ "CI_SigName" SG_ 2566904641 RoadType "Road Type";
BA_ "GenSigSendType" SG_ 2566904641 RoadType 3;
BA_ "GenSigTimeoutTime_PCM" SG_ 2566904641 RoadType 5000;
BA_ "CI_ParId" SG_ 2566904641 NavSymCode2 "I256";
BA_ "CI_SigId" SG_ 2566904641 NavSymCode2 44594;
BA_ "CI_SigName" SG_ 2566904641 NavSymCode2 "Navigation Symbol Code 2";
BA_ "GenSigSendType" SG_ 2566904641 NavSymCode2 3;
BA_ "GenSigTimeoutTime_PCM" SG_ 2566904641 NavSymCode2 5000;
BA_ "CI_ParId" SG_ 2566904641 DistToNextEvt "I730";
BA_ "CI_SigId" SG_ 2566904641 DistToNextEvt 10305;
BA_ "CI_SigName" SG_ 2566904641 DistToNextEvt "Distance to Next Event";
BA_ "GenSigSendType" SG_ 2566904641 DistToNextEvt 3;
BA_ "GenSigTimeoutTime_PCM" SG_ 2566904641 DistToNextEvt 5000;
BA_ "CI_ParId" SG_ 2566904641 DistResolIx "I729";
BA_ "CI_SigId" SG_ 2566904641 DistResolIx 10304;
BA_ "CI_SigName" SG_ 2566904641 DistResolIx "Distance Resolution Index";
BA_ "GenSigSendType" SG_ 2566904641 DistResolIx 3;
BA_ "GenSigTimeoutTime_PCM" SG_ 2566904641 DistResolIx 5000;
BA_ "CI_ParId" SG_ 2566904641 DistUnitsIx "I728";
BA_ "CI_SigId" SG_ 2566904641 DistUnitsIx 10303;
BA_ "CI_SigName" SG_ 2566904641 DistUnitsIx "Distance Units Index";
BA_ "GenSigSendType" SG_ 2566904641 DistUnitsIx 3;
BA_ "GenSigTimeoutTime_PCM" SG_ 2566904641 DistUnitsIx 5000;
BA_ "CI_ParId" SG_ 2566896705 Long "585";
BA_ "CI_SigId" SG_ 2566896705 Long 10315;
BA_ "CI_SigName" SG_ 2566896705 Long "Longitude";
BA_ "GenSigSendType" SG_ 2566896705 Long 3;
BA_ "GenSigTimeoutTime_PCM" SG_ 2566896705 Long 5000;
BA_ "SPN" SG_ 2566896705 Long 585;
BA_ "SigType" SG_ 2566896705 Long 1;
BA_ "CI_ParId" SG_ 2566896705 Lat "584";
BA_ "CI_SigId" SG_ 2566896705 Lat 10314;
BA_ "CI_SigName" SG_ 2566896705 Lat "Latitude";
BA_ "GenSigSendType" SG_ 2566896705 Lat 3;
BA_ "GenSigTimeoutTime_PCM" SG_ 2566896705 Lat 5000;
BA_ "SPN" SG_ 2566896705 Lat 584;
BA_ "SigType" SG_ 2566896705 Lat 1;
BA_ "CI_ParId" SG_ 2566896714 Long_FFBC4A "585";
BA_ "CI_SigId" SG_ 2566896714 Long_FFBC4A 10318;
BA_ "CI_SigName" SG_ 2566896714 Long_FFBC4A "Longitude";
BA_ "GenSigSendType" SG_ 2566896714 Long_FFBC4A 3;
BA_ "GenSigTimeoutTime_SGW" SG_ 2566896714 Long_FFBC4A 5000;
BA_ "SPN" SG_ 2566896714 Long_FFBC4A 585;
BA_ "SigType" SG_ 2566896714 Long_FFBC4A 1;
BA_ "CI_ParId" SG_ 2566896714 Lat_FFBC4A "584";
BA_ "CI_SigId" SG_ 2566896714 Lat_FFBC4A 10317;
BA_ "CI_SigName" SG_ 2566896714 Lat_FFBC4A "Latitude";
BA_ "GenSigSendType" SG_ 2566896714 Lat_FFBC4A 3;
BA_ "GenSigTimeoutTime_SGW" SG_ 2566896714 Lat_FFBC4A 5000;
BA_ "SPN" SG_ 2566896714 Lat_FFBC4A 584;
BA_ "SigType" SG_ 2566896714 Lat_FFBC4A 1;
BA_ "CI_ParId" SG_ 2634009665 NavNextEvtStreetName "I727";
BA_ "CI_SigId" SG_ 2634009665 NavNextEvtStreetName 44877;
BA_ "CI_SigName" SG_ 2634009665 NavNextEvtStreetName "Navigation Next Event Street Name";
BA_ "GenSigSendType" SG_ 2634009665 NavNextEvtStreetName 3;
BA_ "SigType" SG_ 2634009665 NavNextEvtStreetName 8;
BA_ "CI_ParId" SG_ 2566892311 RearCrossTrafficAlertFunctCfg "ID2290";
BA_ "CI_SigId" SG_ 2566892311 RearCrossTrafficAlertFunctCfg 42270;
BA_ "CI_SigName" SG_ 2566892311 RearCrossTrafficAlertFunctCfg "Rear Cross Traffic Alert Function Configuration";
BA_ "GenSigSendType" SG_ 2566892311 RearCrossTrafficAlertFunctCfg 3;
BA_ "GenSigTimeoutTime_PCM" SG_ 2566892311 RearCrossTrafficAlertFunctCfg 5000;
BA_ "SigType" SG_ 2566892311 RearCrossTrafficAlertFunctCfg 4;
BA_ "CI_ParId" SG_ 2566892311 RearCrossTrafficAlertAcousticWar "ID2289";
BA_ "CI_SigId" SG_ 2566892311 RearCrossTrafficAlertAcousticWar 42269;
BA_ "CI_SigName" SG_ 2566892311 RearCrossTrafficAlertAcousticWar "Rear Cross Traffic Alert Acoustic Warning Configuration";
BA_ "GenSigSendType" SG_ 2566892311 RearCrossTrafficAlertAcousticWar 3;
BA_ "GenSigTimeoutTime_PCM" SG_ 2566892311 RearCrossTrafficAlertAcousticWar 5000;
BA_ "SigType" SG_ 2566892311 RearCrossTrafficAlertAcousticWar 4;
BA_ "CI_ParId" SG_ 2566892311 BlindSpotFunctCfg "ID2285";
BA_ "CI_SigId" SG_ 2566892311 BlindSpotFunctCfg 42267;
BA_ "CI_SigName" SG_ 2566892311 BlindSpotFunctCfg "Blind Spot Function Configuration";
BA_ "GenSigSendType" SG_ 2566892311 BlindSpotFunctCfg 3;
BA_ "GenSigTimeoutTime_PCM" SG_ 2566892311 BlindSpotFunctCfg 5000;
BA_ "SigType" SG_ 2566892311 BlindSpotFunctCfg 4;
BA_ "CI_ParId" SG_ 2566892311 BlindSpotAcousticWarnCfg "ID2284";
BA_ "CI_SigId" SG_ 2566892311 BlindSpotAcousticWarnCfg 42266;
BA_ "CI_SigName" SG_ 2566892311 BlindSpotAcousticWarnCfg "Blind Spot Acoustic Warning Configuration";
BA_ "GenSigSendType" SG_ 2566892311 BlindSpotAcousticWarnCfg 3;
BA_ "GenSigTimeoutTime_PCM" SG_ 2566892311 BlindSpotAcousticWarnCfg 5000;
BA_ "SigType" SG_ 2566892311 BlindSpotAcousticWarnCfg 4;
BA_ "CI_ParId" SG_ 2566892362 ZZS_22_18FFAB4A "ID2290";
BA_ "CI_SigId" SG_ 2566892362 ZZS_22_18FFAB4A 42278;
BA_ "CI_SigName" SG_ 2566892362 ZZS_22_18FFAB4A "Rear Cross Traffic Alert Function Configuration";
BA_ "SigType" SG_ 2566892362 ZZS_22_18FFAB4A 4;
BA_ "CI_ParId" SG_ 2566892362 ZZS_20_18FFAB4A "ID2289";
BA_ "CI_SigId" SG_ 2566892362 ZZS_20_18FFAB4A 42277;
BA_ "CI_SigName" SG_ 2566892362 ZZS_20_18FFAB4A "Rear Cross Traffic Alert Acoustic Warning Configuration";
BA_ "SigType" SG_ 2566892362 ZZS_20_18FFAB4A 4;
BA_ "CI_ParId" SG_ 2566892362 BlindSpotFunctCfg_FFAB4A "ID2285";
BA_ "CI_SigId" SG_ 2566892362 BlindSpotFunctCfg_FFAB4A 42275;
BA_ "CI_SigName" SG_ 2566892362 BlindSpotFunctCfg_FFAB4A "Blind Spot Function Configuration";
BA_ "SigType" SG_ 2566892362 BlindSpotFunctCfg_FFAB4A 4;
BA_ "CI_ParId" SG_ 2566892362 BlindSpotAcousticWarnCfg_FFAB4A "ID2284";
BA_ "CI_SigId" SG_ 2566892362 BlindSpotAcousticWarnCfg_FFAB4A 42274;
BA_ "CI_SigName" SG_ 2566892362 BlindSpotAcousticWarnCfg_FFAB4A "Blind Spot Acoustic Warning Configuration";
BA_ "SigType" SG_ 2566892362 BlindSpotAcousticWarnCfg_FFAB4A 4;
BA_ "CI_ParId" SG_ 2566892444 TimeToCollWithRelvObj_FFAB9C "ID2304";
BA_ "CI_SigId" SG_ 2566892444 TimeToCollWithRelvObj_FFAB9C 42262;
BA_ "CI_SigName" SG_ 2566892444 TimeToCollWithRelvObj_FFAB9C "Time to collision with relevant object";
BA_ "GenSigTimeoutTime_PCM" SG_ 2566892444 TimeToCollWithRelvObj_FFAB9C 1000;
BA_ "SigType" SG_ 2566892444 TimeToCollWithRelvObj_FFAB9C 1;
BA_ "CI_ParId" SG_ 2566892444 ObjTypeDetSts "ID2303";
BA_ "CI_SigId" SG_ 2566892444 ObjTypeDetSts 42261;
BA_ "CI_SigName" SG_ 2566892444 ObjTypeDetSts "Object Type Detection Status";
BA_ "GenSigTimeoutTime_PCM" SG_ 2566892444 ObjTypeDetSts 1000;
BA_ "CI_ParId" SG_ 2566892444 RearCrossTrafficAlertRightWarnIn "ID2293";
BA_ "CI_SigId" SG_ 2566892444 RearCrossTrafficAlertRightWarnIn 42252;
BA_ "CI_SigName" SG_ 2566892444 RearCrossTrafficAlertRightWarnIn "Rear Cross Traffic Alert Right Warning Information";
BA_ "GenSigTimeoutTime_PCM" SG_ 2566892444 RearCrossTrafficAlertRightWarnIn 1000;
BA_ "CI_ParId" SG_ 2566892444 RearCrossTrafficAlertLeftWarnInf "ID2292";
BA_ "CI_SigId" SG_ 2566892444 RearCrossTrafficAlertLeftWarnInf 42251;
BA_ "CI_SigName" SG_ 2566892444 RearCrossTrafficAlertLeftWarnInf "Rear Cross Traffic Alert Left Warning Information";
BA_ "GenSigTimeoutTime_PCM" SG_ 2566892444 RearCrossTrafficAlertLeftWarnInf 1000;
BA_ "CI_ParId" SG_ 2566892444 BlindSpotRightWarnInfo "ID2288";
BA_ "CI_SigId" SG_ 2566892444 BlindSpotRightWarnInfo 42250;
BA_ "CI_SigName" SG_ 2566892444 BlindSpotRightWarnInfo "Blind Spot Right Warning Information";
BA_ "GenSigTimeoutTime_PCM" SG_ 2566892444 BlindSpotRightWarnInfo 1000;
BA_ "CI_ParId" SG_ 2566892444 BlindSpotLeftWarnInfo "ID2287";
BA_ "CI_SigId" SG_ 2566892444 BlindSpotLeftWarnInfo 42249;
BA_ "CI_SigName" SG_ 2566892444 BlindSpotLeftWarnInfo "Blind Spot Left Warning Information";
BA_ "GenSigTimeoutTime_PCM" SG_ 2566892444 BlindSpotLeftWarnInfo 1000;
BA_ "CI_ParId" SG_ 2566892444 RearCrossTrafficAlertSts "ID2291";
BA_ "CI_SigId" SG_ 2566892444 RearCrossTrafficAlertSts 42248;
BA_ "CI_SigName" SG_ 2566892444 RearCrossTrafficAlertSts "Rear Cross Traffic Alert Status";
BA_ "GenSigTimeoutTime_PCM" SG_ 2566892444 RearCrossTrafficAlertSts 1000;
BA_ "CI_ParId" SG_ 2566892444 BlindSpotSts "ID2286";
BA_ "CI_SigId" SG_ 2566892444 BlindSpotSts 42247;
BA_ "CI_SigName" SG_ 2566892444 BlindSpotSts "Blind Spot Status";
BA_ "GenSigTimeoutTime_PCM" SG_ 2566892444 BlindSpotSts 1000;
BA_ "CI_ParId" SG_ 2566892444 RctTypeOfFunctSts "ID2422";
BA_ "CI_SigId" SG_ 2566892444 RctTypeOfFunctSts 44218;
BA_ "CI_SigName" SG_ 2566892444 RctTypeOfFunctSts "RCT Type of Function Status";
BA_ "GenSigTimeoutTime_PCM" SG_ 2566892444 RctTypeOfFunctSts 1000;
BA_ "SigType" SG_ 2566892444 RctTypeOfFunctSts 4;
BA_ "CI_ParId" SG_ 2566892567 BsisAcousticWarnCfg "ID2299";
BA_ "CI_SigId" SG_ 2566892567 BsisAcousticWarnCfg 42299;
BA_ "CI_SigName" SG_ 2566892567 BsisAcousticWarnCfg "BSIS Acoustic Warning Configuration";
BA_ "GenSigSendType" SG_ 2566892567 BsisAcousticWarnCfg 3;
BA_ "GenSigTimeoutTime_PCM" SG_ 2566892567 BsisAcousticWarnCfg 5000;
BA_ "SigType" SG_ 2566892567 BsisAcousticWarnCfg 4;
BA_ "CI_ParId" SG_ 2566892567 MoisFunctCfg "ID2295";
BA_ "CI_SigId" SG_ 2566892567 MoisFunctCfg 42298;
BA_ "CI_SigName" SG_ 2566892567 MoisFunctCfg "MOIS Function Configuration";
BA_ "GenSigSendType" SG_ 2566892567 MoisFunctCfg 3;
BA_ "GenSigStartValue" SG_ 2566892567 MoisFunctCfg 1;
BA_ "GenSigTimeoutTime_PCM" SG_ 2566892567 MoisFunctCfg 5000;
BA_ "SigType" SG_ 2566892567 MoisFunctCfg 4;
BA_ "CI_ParId" SG_ 2566892567 MoisAcousticWarnCfg "ID2294";
BA_ "CI_SigId" SG_ 2566892567 MoisAcousticWarnCfg 42297;
BA_ "CI_SigName" SG_ 2566892567 MoisAcousticWarnCfg "MOIS Acoustic Warning Configuration";
BA_ "GenSigSendType" SG_ 2566892567 MoisAcousticWarnCfg 3;
BA_ "GenSigTimeoutTime_PCM" SG_ 2566892567 MoisAcousticWarnCfg 5000;
BA_ "SigType" SG_ 2566892567 MoisAcousticWarnCfg 4;
BA_ "CI_ParId" SG_ 2566892618 BsisAcousticWarnCfg_FFAC4A "ID2299";
BA_ "CI_SigId" SG_ 2566892618 BsisAcousticWarnCfg_FFAC4A 42733;
BA_ "CI_SigName" SG_ 2566892618 BsisAcousticWarnCfg_FFAC4A "BSIS Acoustic Warning Configuration";
BA_ "SigType" SG_ 2566892618 BsisAcousticWarnCfg_FFAC4A 4;
BA_ "CI_ParId" SG_ 2566892702 TimeToCollWithRelvObj_FFAC9E "ID2304";
BA_ "CI_SigId" SG_ 2566892702 TimeToCollWithRelvObj_FFAC9E 42285;
BA_ "CI_SigName" SG_ 2566892702 TimeToCollWithRelvObj_FFAC9E "Time to collision with relevant object";
BA_ "GenSigTimeoutTime_PCM" SG_ 2566892702 TimeToCollWithRelvObj_FFAC9E 1000;
BA_ "SigType" SG_ 2566892702 TimeToCollWithRelvObj_FFAC9E 1;
BA_ "CI_ParId" SG_ 2566892702 ObjTypeDetSts_FFAC9E "ID2303";
BA_ "CI_SigId" SG_ 2566892702 ObjTypeDetSts_FFAC9E 42284;
BA_ "CI_SigName" SG_ 2566892702 ObjTypeDetSts_FFAC9E "Object Type Detection Status";
BA_ "GenSigTimeoutTime_PCM" SG_ 2566892702 ObjTypeDetSts_FFAC9E 1000;
BA_ "CI_ParId" SG_ 2566892702 MoisFunctSts "ID2298";
BA_ "CI_SigId" SG_ 2566892702 MoisFunctSts 42727;
BA_ "CI_SigName" SG_ 2566892702 MoisFunctSts "MOIS Function Status";
BA_ "GenSigTimeoutTime_PCM" SG_ 2566892702 MoisFunctSts 1000;
BA_ "CI_ParId" SG_ 2566892702 MoisWarnInfo "ID2297";
BA_ "CI_SigId" SG_ 2566892702 MoisWarnInfo 42283;
BA_ "CI_SigName" SG_ 2566892702 MoisWarnInfo "MOIS Warning Information";
BA_ "GenSigTimeoutTime_PCM" SG_ 2566892702 MoisWarnInfo 1000;
BA_ "CI_ParId" SG_ 2566892702 MoisSts "ID2296";
BA_ "CI_SigId" SG_ 2566892702 MoisSts 42282;
BA_ "CI_SigName" SG_ 2566892702 MoisSts "MOIS Status";
BA_ "GenSigTimeoutTime_PCM" SG_ 2566892702 MoisSts 1000;
BA_ "CI_ParId" SG_ 2566892702 MoisTypeOfFunctSts "ID2420";
BA_ "CI_SigId" SG_ 2566892702 MoisTypeOfFunctSts 44219;
BA_ "CI_SigName" SG_ 2566892702 MoisTypeOfFunctSts "MOIS Type of Function Status";
BA_ "GenSigTimeoutTime_PCM" SG_ 2566892702 MoisTypeOfFunctSts 1000;
BA_ "SigType" SG_ 2566892702 MoisTypeOfFunctSts 4;
BA_ "CI_ParId" SG_ 2566892703 TimeToCollWithRelvObj_FFAC9F "ID2304";
BA_ "CI_SigId" SG_ 2566892703 TimeToCollWithRelvObj_FFAC9F 42293;
BA_ "CI_SigName" SG_ 2566892703 TimeToCollWithRelvObj_FFAC9F "Time to collision with relevant object";
BA_ "GenSigTimeoutTime_PCM" SG_ 2566892703 TimeToCollWithRelvObj_FFAC9F 1000;
BA_ "SigType" SG_ 2566892703 TimeToCollWithRelvObj_FFAC9F 1;
BA_ "CI_ParId" SG_ 2566892703 ObjTypeDetSts_FFAC9F "ID2303";
BA_ "CI_SigId" SG_ 2566892703 ObjTypeDetSts_FFAC9F 42292;
BA_ "CI_SigName" SG_ 2566892703 ObjTypeDetSts_FFAC9F "Object Type Detection Status";
BA_ "GenSigTimeoutTime_PCM" SG_ 2566892703 ObjTypeDetSts_FFAC9F 1000;
BA_ "CI_ParId" SG_ 2566892703 BsisFunctSts "ID2302";
BA_ "CI_SigId" SG_ 2566892703 BsisFunctSts 42291;
BA_ "CI_SigName" SG_ 2566892703 BsisFunctSts "BSIS Function Status";
BA_ "GenSigTimeoutTime_PCM" SG_ 2566892703 BsisFunctSts 1000;
BA_ "CI_ParId" SG_ 2566892703 BsisWarnInfo "ID2301";
BA_ "CI_SigId" SG_ 2566892703 BsisWarnInfo 42290;
BA_ "CI_SigName" SG_ 2566892703 BsisWarnInfo "BSIS Warning Information";
BA_ "GenSigTimeoutTime_PCM" SG_ 2566892703 BsisWarnInfo 1000;
BA_ "CI_ParId" SG_ 2566892703 BsisSts "ID2300";
BA_ "CI_SigId" SG_ 2566892703 BsisSts 42289;
BA_ "CI_SigName" SG_ 2566892703 BsisSts "BSIS Status";
BA_ "GenSigTimeoutTime_PCM" SG_ 2566892703 BsisSts 1000;
BA_ "CI_ParId" SG_ 2566892703 BsisTypeOfFunctSts "ID2421";
BA_ "CI_SigId" SG_ 2566892703 BsisTypeOfFunctSts 44220;
BA_ "CI_SigName" SG_ 2566892703 BsisTypeOfFunctSts "BSIS Type of Function Status";
BA_ "GenSigTimeoutTime_PCM" SG_ 2566892703 BsisTypeOfFunctSts 1000;
BA_ "SigType" SG_ 2566892703 BsisTypeOfFunctSts 4;
BA_ "CI_ParId" SG_ 2566865010 PtoDegrModeIx "IS385";
BA_ "CI_SigId" SG_ 2566865010 PtoDegrModeIx 10877;
BA_ "CI_SigName" SG_ 2566865010 PtoDegrModeIx "PTO Degraded Mode Index";
BA_ "GenSigTimeoutTime_PCM" SG_ 2566865010 PtoDegrModeIx 5000;
BA_ "CI_ParId" SG_ 2566865010 Pto3EsvCtrl "ID0232";
BA_ "CI_SigId" SG_ 2566865010 Pto3EsvCtrl 10876;
BA_ "CI_SigName" SG_ 2566865010 Pto3EsvCtrl "PTO 3 ESV Control";
BA_ "GenSigTimeoutTime_PCM" SG_ 2566865010 Pto3EsvCtrl 5000;
BA_ "CI_ParId" SG_ 2566865010 Pto3LowOilPrs "ID0231";
BA_ "CI_SigId" SG_ 2566865010 Pto3LowOilPrs 10875;
BA_ "CI_SigName" SG_ 2566865010 Pto3LowOilPrs "PTO 3 Low Oil Pressure";
BA_ "GenSigTimeoutTime_PCM" SG_ 2566865010 Pto3LowOilPrs 5000;
BA_ "CI_ParId" SG_ 2566865010 Pto3Et2Ctrl "IS382";
BA_ "CI_SigId" SG_ 2566865010 Pto3Et2Ctrl 10874;
BA_ "CI_SigName" SG_ 2566865010 Pto3Et2Ctrl "PTO 3 Eurotronic Control";
BA_ "GenSigTimeoutTime_PCM" SG_ 2566865010 Pto3Et2Ctrl 5000;
BA_ "CI_ParId" SG_ 2566865010 Pto3WaterTemp "IS383";
BA_ "CI_SigId" SG_ 2566865010 Pto3WaterTemp 10873;
BA_ "CI_SigName" SG_ 2566865010 Pto3WaterTemp "PTO 3 Water Temp";
BA_ "GenSigTimeoutTime_PCM" SG_ 2566865010 Pto3WaterTemp 5000;
BA_ "CI_ParId" SG_ 2566865010 Pto3VehSpeed "IS384";
BA_ "CI_SigId" SG_ 2566865010 Pto3VehSpeed 10872;
BA_ "CI_SigName" SG_ 2566865010 Pto3VehSpeed "PTO 3 Vehicle Speed";
BA_ "GenSigTimeoutTime_PCM" SG_ 2566865010 Pto3VehSpeed 5000;
BA_ "CI_ParId" SG_ 2566865010 Pto3EngRpm "IS375";
BA_ "CI_SigId" SG_ 2566865010 Pto3EngRpm 10871;
BA_ "CI_SigName" SG_ 2566865010 Pto3EngRpm "PTO 3 Engine RPM";
BA_ "GenSigTimeoutTime_PCM" SG_ 2566865010 Pto3EngRpm 5000;
BA_ "CI_ParId" SG_ 2566865010 Pto3Gear "IS376";
BA_ "CI_SigId" SG_ 2566865010 Pto3Gear 10870;
BA_ "CI_SigName" SG_ 2566865010 Pto3Gear "PTO 3 Gear";
BA_ "GenSigTimeoutTime_PCM" SG_ 2566865010 Pto3Gear 5000;
BA_ "CI_ParId" SG_ 2566865010 Pto3Clt "IS377";
BA_ "CI_SigId" SG_ 2566865010 Pto3Clt 10869;
BA_ "CI_SigName" SG_ 2566865010 Pto3Clt "PTO 3 Clutch";
BA_ "GenSigTimeoutTime_PCM" SG_ 2566865010 Pto3Clt 5000;
BA_ "CI_ParId" SG_ 2566865010 Pto3EmIn "IS854";
BA_ "CI_SigId" SG_ 2566865010 Pto3EmIn 10868;
BA_ "CI_SigName" SG_ 2566865010 Pto3EmIn "PTO 3 EM input";
BA_ "GenSigTimeoutTime_PCM" SG_ 2566865010 Pto3EmIn 5000;
BA_ "CI_ParId" SG_ 2566865010 Pto3Handbrake "IS379";
BA_ "CI_SigId" SG_ 2566865010 Pto3Handbrake 10867;
BA_ "CI_SigName" SG_ 2566865010 Pto3Handbrake "PTO 3 Handbrake";
BA_ "GenSigTimeoutTime_PCM" SG_ 2566865010 Pto3Handbrake 5000;
BA_ "CI_ParId" SG_ 2566865010 Pto3Brk "IS380";
BA_ "CI_SigId" SG_ 2566865010 Pto3Brk 10866;
BA_ "CI_SigName" SG_ 2566865010 Pto3Brk "PTO 3 Brake";
BA_ "GenSigTimeoutTime_PCM" SG_ 2566865010 Pto3Brk 5000;
BA_ "CI_ParId" SG_ 2566865010 Pto3DegrOpMode "IS381";
BA_ "CI_SigId" SG_ 2566865010 Pto3DegrOpMode 10865;
BA_ "CI_SigName" SG_ 2566865010 Pto3DegrOpMode "PTO 3 Degraded Operation Mode";
BA_ "GenSigTimeoutTime_PCM" SG_ 2566865010 Pto3DegrOpMode 5000;
BA_ "SigType" SG_ 2566865010 Pto3DegrOpMode 4;
BA_ "CI_ParId" SG_ 2566865010 Pto2EsvCtrl "ID0230";
BA_ "CI_SigId" SG_ 2566865010 Pto2EsvCtrl 10864;
BA_ "CI_SigName" SG_ 2566865010 Pto2EsvCtrl "PTO 2 ESV Control";
BA_ "GenSigTimeoutTime_PCM" SG_ 2566865010 Pto2EsvCtrl 5000;
BA_ "CI_ParId" SG_ 2566865010 Pto2LowOilPrs "ID0229";
BA_ "CI_SigId" SG_ 2566865010 Pto2LowOilPrs 10863;
BA_ "CI_SigName" SG_ 2566865010 Pto2LowOilPrs "PTO 2 Low Oil Pressure";
BA_ "GenSigTimeoutTime_PCM" SG_ 2566865010 Pto2LowOilPrs 5000;
BA_ "CI_ParId" SG_ 2566865010 Pto2Et2Ctrl "IS372";
BA_ "CI_SigId" SG_ 2566865010 Pto2Et2Ctrl 10862;
BA_ "CI_SigName" SG_ 2566865010 Pto2Et2Ctrl "PTO 2 Eurotronic Control";
BA_ "GenSigTimeoutTime_PCM" SG_ 2566865010 Pto2Et2Ctrl 5000;
BA_ "CI_ParId" SG_ 2566865010 Pto2WaterTemp "IS373";
BA_ "CI_SigId" SG_ 2566865010 Pto2WaterTemp 10861;
BA_ "CI_SigName" SG_ 2566865010 Pto2WaterTemp "PTO 2 Water Temp";
BA_ "GenSigTimeoutTime_PCM" SG_ 2566865010 Pto2WaterTemp 5000;
BA_ "CI_ParId" SG_ 2566865010 Pto2VehSpeed "IS374";
BA_ "CI_SigId" SG_ 2566865010 Pto2VehSpeed 10860;
BA_ "CI_SigName" SG_ 2566865010 Pto2VehSpeed "PTO 2 Vehicle Speed";
BA_ "GenSigTimeoutTime_PCM" SG_ 2566865010 Pto2VehSpeed 5000;
BA_ "CI_ParId" SG_ 2566865010 Pto2EngRpm "IS365";
BA_ "CI_SigId" SG_ 2566865010 Pto2EngRpm 10859;
BA_ "CI_SigName" SG_ 2566865010 Pto2EngRpm "PTO 2 Engine RPM";
BA_ "GenSigTimeoutTime_PCM" SG_ 2566865010 Pto2EngRpm 5000;
BA_ "CI_ParId" SG_ 2566865010 Pto2Gear "IS366";
BA_ "CI_SigId" SG_ 2566865010 Pto2Gear 10858;
BA_ "CI_SigName" SG_ 2566865010 Pto2Gear "PTO 2 Gear";
BA_ "GenSigTimeoutTime_PCM" SG_ 2566865010 Pto2Gear 5000;
BA_ "CI_ParId" SG_ 2566865010 Pto2Clt "IS367";
BA_ "CI_SigId" SG_ 2566865010 Pto2Clt 10857;
BA_ "CI_SigName" SG_ 2566865010 Pto2Clt "PTO 2 Clutch";
BA_ "GenSigTimeoutTime_PCM" SG_ 2566865010 Pto2Clt 5000;
BA_ "CI_ParId" SG_ 2566865010 Pto2EmIn "IS853";
BA_ "CI_SigId" SG_ 2566865010 Pto2EmIn 10856;
BA_ "CI_SigName" SG_ 2566865010 Pto2EmIn "PTO 2 EM input";
BA_ "GenSigTimeoutTime_PCM" SG_ 2566865010 Pto2EmIn 5000;
BA_ "CI_ParId" SG_ 2566865010 Pto2Handbrake "IS369";
BA_ "CI_SigId" SG_ 2566865010 Pto2Handbrake 10855;
BA_ "CI_SigName" SG_ 2566865010 Pto2Handbrake "PTO 2 Handbrake";
BA_ "GenSigTimeoutTime_PCM" SG_ 2566865010 Pto2Handbrake 5000;
BA_ "CI_ParId" SG_ 2566865010 Pto2Brk "IS370";
BA_ "CI_SigId" SG_ 2566865010 Pto2Brk 10854;
BA_ "CI_SigName" SG_ 2566865010 Pto2Brk "PTO 2 Brake ";
BA_ "GenSigTimeoutTime_PCM" SG_ 2566865010 Pto2Brk 5000;
BA_ "CI_ParId" SG_ 2566865010 Pto2DegrOpMode "IS371";
BA_ "CI_SigId" SG_ 2566865010 Pto2DegrOpMode 10853;
BA_ "CI_SigName" SG_ 2566865010 Pto2DegrOpMode "PTO 2 Degraded Operation Mode";
BA_ "GenSigTimeoutTime_PCM" SG_ 2566865010 Pto2DegrOpMode 5000;
BA_ "SigType" SG_ 2566865010 Pto2DegrOpMode 4;
BA_ "CI_ParId" SG_ 2566865010 Pto1EsvCtrl "ID0228";
BA_ "CI_SigId" SG_ 2566865010 Pto1EsvCtrl 10852;
BA_ "CI_SigName" SG_ 2566865010 Pto1EsvCtrl "PTO 1 ESV Control";
BA_ "GenSigTimeoutTime_PCM" SG_ 2566865010 Pto1EsvCtrl 5000;
BA_ "CI_ParId" SG_ 2566865010 Pto1LowOilPrs "ID0227";
BA_ "CI_SigId" SG_ 2566865010 Pto1LowOilPrs 10851;
BA_ "CI_SigName" SG_ 2566865010 Pto1LowOilPrs "PTO 1 Low Oil Pressure";
BA_ "GenSigTimeoutTime_PCM" SG_ 2566865010 Pto1LowOilPrs 5000;
BA_ "CI_ParId" SG_ 2566865010 Pto1Et2Ctrl "IS362";
BA_ "CI_SigId" SG_ 2566865010 Pto1Et2Ctrl 10850;
BA_ "CI_SigName" SG_ 2566865010 Pto1Et2Ctrl "PTO 1 Eurotronic Control";
BA_ "GenSigTimeoutTime_PCM" SG_ 2566865010 Pto1Et2Ctrl 5000;
BA_ "CI_ParId" SG_ 2566865010 Pto1WaterTemp "IS363";
BA_ "CI_SigId" SG_ 2566865010 Pto1WaterTemp 10849;
BA_ "CI_SigName" SG_ 2566865010 Pto1WaterTemp "PTO 1 Water Temp";
BA_ "GenSigTimeoutTime_PCM" SG_ 2566865010 Pto1WaterTemp 5000;
BA_ "CI_ParId" SG_ 2566865010 Pto1VehSpeed "IS364";
BA_ "CI_SigId" SG_ 2566865010 Pto1VehSpeed 10848;
BA_ "CI_SigName" SG_ 2566865010 Pto1VehSpeed "PTO 1 Vehicle Speed";
BA_ "GenSigTimeoutTime_PCM" SG_ 2566865010 Pto1VehSpeed 5000;
BA_ "CI_ParId" SG_ 2566865010 Pto1EngRpm "IS355";
BA_ "CI_SigId" SG_ 2566865010 Pto1EngRpm 10847;
BA_ "CI_SigName" SG_ 2566865010 Pto1EngRpm "PTO 1 Engine RPM";
BA_ "GenSigTimeoutTime_PCM" SG_ 2566865010 Pto1EngRpm 5000;
BA_ "CI_ParId" SG_ 2566865010 Pto1Gear "IS356";
BA_ "CI_SigId" SG_ 2566865010 Pto1Gear 10846;
BA_ "CI_SigName" SG_ 2566865010 Pto1Gear "PTO 1 Gear";
BA_ "GenSigTimeoutTime_PCM" SG_ 2566865010 Pto1Gear 5000;
BA_ "CI_ParId" SG_ 2566865010 Pto1Clt "IS357";
BA_ "CI_SigId" SG_ 2566865010 Pto1Clt 10845;
BA_ "CI_SigName" SG_ 2566865010 Pto1Clt "PTO 1 Clutch";
BA_ "GenSigTimeoutTime_PCM" SG_ 2566865010 Pto1Clt 5000;
BA_ "CI_ParId" SG_ 2566865010 Pto1EmIn "IS852";
BA_ "CI_SigId" SG_ 2566865010 Pto1EmIn 10844;
BA_ "CI_SigName" SG_ 2566865010 Pto1EmIn "PTO 1 EM Input";
BA_ "GenSigTimeoutTime_PCM" SG_ 2566865010 Pto1EmIn 5000;
BA_ "CI_ParId" SG_ 2566865010 Pto1Handbrake "IS359";
BA_ "CI_SigId" SG_ 2566865010 Pto1Handbrake 10843;
BA_ "CI_SigName" SG_ 2566865010 Pto1Handbrake "PTO 1 Handbrake";
BA_ "GenSigTimeoutTime_PCM" SG_ 2566865010 Pto1Handbrake 5000;
BA_ "CI_ParId" SG_ 2566865010 Pto1Brk "IS360";
BA_ "CI_SigId" SG_ 2566865010 Pto1Brk 10842;
BA_ "CI_SigName" SG_ 2566865010 Pto1Brk "PTO 1 Brake";
BA_ "GenSigTimeoutTime_PCM" SG_ 2566865010 Pto1Brk 5000;
BA_ "CI_ParId" SG_ 2566865010 Pto1DegrOpMode "IS361";
BA_ "CI_SigId" SG_ 2566865010 Pto1DegrOpMode 10841;
BA_ "CI_SigName" SG_ 2566865010 Pto1DegrOpMode "PTO 1 Degraded Operation Mode";
BA_ "GenSigTimeoutTime_PCM" SG_ 2566865010 Pto1DegrOpMode 5000;
BA_ "SigType" SG_ 2566865010 Pto1DegrOpMode 4;
BA_ "CI_ParId" SG_ 2566865010 Pto1EngdSts "IS745";
BA_ "CI_SigId" SG_ 2566865010 Pto1EngdSts 10840;
BA_ "CI_SigName" SG_ 2566865010 Pto1EngdSts "PTO 1 Engaged Status";
BA_ "GenSigTimeoutTime_PCM" SG_ 2566865010 Pto1EngdSts 5000;
BA_ "SigType" SG_ 2566865010 Pto1EngdSts 4;
BA_ "CI_ParId" SG_ 2566865010 Pto2EngdSts "IS746";
BA_ "CI_SigId" SG_ 2566865010 Pto2EngdSts 10839;
BA_ "CI_SigName" SG_ 2566865010 Pto2EngdSts "PTO 2 Engaged Status";
BA_ "GenSigTimeoutTime_PCM" SG_ 2566865010 Pto2EngdSts 5000;
BA_ "SigType" SG_ 2566865010 Pto2EngdSts 4;
BA_ "CI_ParId" SG_ 2566865010 Pto3EngdSts "IS747";
BA_ "CI_SigId" SG_ 2566865010 Pto3EngdSts 10838;
BA_ "CI_SigName" SG_ 2566865010 Pto3EngdSts "PTO 3 Engaged Status";
BA_ "GenSigTimeoutTime_PCM" SG_ 2566865010 Pto3EngdSts 5000;
BA_ "SigType" SG_ 2566865010 Pto3EngdSts 4;
BA_ "CI_ParId" SG_ 2566865010 DegrModeSts "IS354";
BA_ "CI_SigId" SG_ 2566865010 DegrModeSts 10837;
BA_ "CI_SigName" SG_ 2566865010 DegrModeSts "Degraded Mode Status";
BA_ "GenSigTimeoutTime_PCM" SG_ 2566865010 DegrModeSts 5000;
BA_ "SigType" SG_ 2566865010 DegrModeSts 4;
BA_ "CI_ParId" SG_ 2566840592 RetPcTrqAtPeakTrqPnt5 "555";
BA_ "CI_SigId" SG_ 2566840592 RetPcTrqAtPeakTrqPnt5 1089;
BA_ "CI_SigName" SG_ 2566840592 RetPcTrqAtPeakTrqPnt5 "Retarder Percent Torque At Peak Torque, Point 5";
BA_ "GenSigSendType" SG_ 2566840592 RetPcTrqAtPeakTrqPnt5 3;
BA_ "GenSigTimeoutTime_PCM" SG_ 2566840592 RetPcTrqAtPeakTrqPnt5 25000;
BA_ "SPN" SG_ 2566840592 RetPcTrqAtPeakTrqPnt5 555;
BA_ "SigType" SG_ 2566840592 RetPcTrqAtPeakTrqPnt5 1;
BA_ "CI_ParId" SG_ 2566840592 RetRefTrq "556";
BA_ "CI_SigId" SG_ 2566840592 RetRefTrq 1088;
BA_ "CI_SigName" SG_ 2566840592 RetRefTrq "Retarder Reference Torque";
BA_ "GenSigSendType" SG_ 2566840592 RetRefTrq 3;
BA_ "GenSigTimeoutTime_PCM" SG_ 2566840592 RetRefTrq 25000;
BA_ "SPN" SG_ 2566840592 RetRefTrq 556;
BA_ "SigType" SG_ 2566840592 RetRefTrq 1;
BA_ "CI_ParId" SG_ 2566840592 RetSpeedAtPeakTrqPnt5 "547";
BA_ "CI_SigId" SG_ 2566840592 RetSpeedAtPeakTrqPnt5 1087;
BA_ "CI_SigName" SG_ 2566840592 RetSpeedAtPeakTrqPnt5 "Retarder Speed At Peak Torque, Point 5";
BA_ "GenSigSendType" SG_ 2566840592 RetSpeedAtPeakTrqPnt5 3;
BA_ "GenSigTimeoutTime_PCM" SG_ 2566840592 RetSpeedAtPeakTrqPnt5 25000;
BA_ "SPN" SG_ 2566840592 RetSpeedAtPeakTrqPnt5 547;
BA_ "SigType" SG_ 2566840592 RetSpeedAtPeakTrqPnt5 1;
BA_ "CI_ParId" SG_ 2566840592 RetPcTrqAtPnt4 "554";
BA_ "CI_SigId" SG_ 2566840592 RetPcTrqAtPnt4 1086;
BA_ "CI_SigName" SG_ 2566840592 RetPcTrqAtPnt4 "Retarder Percent Torque At Point 4";
BA_ "GenSigSendType" SG_ 2566840592 RetPcTrqAtPnt4 3;
BA_ "GenSigTimeoutTime_PCM" SG_ 2566840592 RetPcTrqAtPnt4 25000;
BA_ "SPN" SG_ 2566840592 RetPcTrqAtPnt4 554;
BA_ "SigType" SG_ 2566840592 RetPcTrqAtPnt4 1;
BA_ "CI_ParId" SG_ 2566840592 RetSpeedAtPnt4 "550";
BA_ "CI_SigId" SG_ 2566840592 RetSpeedAtPnt4 1085;
BA_ "CI_SigName" SG_ 2566840592 RetSpeedAtPnt4 "Retarder Speed At Point 4";
BA_ "GenSigSendType" SG_ 2566840592 RetSpeedAtPnt4 3;
BA_ "GenSigTimeoutTime_PCM" SG_ 2566840592 RetSpeedAtPnt4 25000;
BA_ "SPN" SG_ 2566840592 RetSpeedAtPnt4 550;
BA_ "SigType" SG_ 2566840592 RetSpeedAtPnt4 1;
BA_ "CI_ParId" SG_ 2566840592 RetPcTrqAtPnt3 "553";
BA_ "CI_SigId" SG_ 2566840592 RetPcTrqAtPnt3 1084;
BA_ "CI_SigName" SG_ 2566840592 RetPcTrqAtPnt3 "Retarder Percent Torque At Point 3";
BA_ "GenSigSendType" SG_ 2566840592 RetPcTrqAtPnt3 3;
BA_ "GenSigTimeoutTime_PCM" SG_ 2566840592 RetPcTrqAtPnt3 25000;
BA_ "SPN" SG_ 2566840592 RetPcTrqAtPnt3 553;
BA_ "SigType" SG_ 2566840592 RetPcTrqAtPnt3 1;
BA_ "CI_ParId" SG_ 2566840592 RetSpeedAtPnt3 "549";
BA_ "CI_SigId" SG_ 2566840592 RetSpeedAtPnt3 1083;
BA_ "CI_SigName" SG_ 2566840592 RetSpeedAtPnt3 "Retarder Speed At Point 3";
BA_ "GenSigSendType" SG_ 2566840592 RetSpeedAtPnt3 3;
BA_ "GenSigTimeoutTime_PCM" SG_ 2566840592 RetSpeedAtPnt3 25000;
BA_ "SPN" SG_ 2566840592 RetSpeedAtPnt3 549;
BA_ "SigType" SG_ 2566840592 RetSpeedAtPnt3 1;
BA_ "CI_ParId" SG_ 2566840592 RetPcTrqAtMaxSpeedPnt2 "552";
BA_ "CI_SigId" SG_ 2566840592 RetPcTrqAtMaxSpeedPnt2 1082;
BA_ "CI_SigName" SG_ 2566840592 RetPcTrqAtMaxSpeedPnt2 "Retarder Percent Torque At Maximum Speed, Point 2";
BA_ "GenSigSendType" SG_ 2566840592 RetPcTrqAtMaxSpeedPnt2 3;
BA_ "GenSigTimeoutTime_PCM" SG_ 2566840592 RetPcTrqAtMaxSpeedPnt2 25000;
BA_ "SPN" SG_ 2566840592 RetPcTrqAtMaxSpeedPnt2 552;
BA_ "SigType" SG_ 2566840592 RetPcTrqAtMaxSpeedPnt2 1;
BA_ "CI_ParId" SG_ 2566840592 MaxRetSpeedPnt2 "548";
BA_ "CI_SigId" SG_ 2566840592 MaxRetSpeedPnt2 1081;
BA_ "CI_SigName" SG_ 2566840592 MaxRetSpeedPnt2 "Maximum Retarder Speed, Point 2";
BA_ "GenSigSendType" SG_ 2566840592 MaxRetSpeedPnt2 3;
BA_ "GenSigTimeoutTime_PCM" SG_ 2566840592 MaxRetSpeedPnt2 25000;
BA_ "SPN" SG_ 2566840592 MaxRetSpeedPnt2 548;
BA_ "SigType" SG_ 2566840592 MaxRetSpeedPnt2 1;
BA_ "CI_ParId" SG_ 2566840592 RetPcTrqAtIdlePnt1 "551";
BA_ "CI_SigId" SG_ 2566840592 RetPcTrqAtIdlePnt1 1080;
BA_ "CI_SigName" SG_ 2566840592 RetPcTrqAtIdlePnt1 "Retarder Percent Torque At Idle, Point 1";
BA_ "GenSigSendType" SG_ 2566840592 RetPcTrqAtIdlePnt1 3;
BA_ "GenSigTimeoutTime_PCM" SG_ 2566840592 RetPcTrqAtIdlePnt1 25000;
BA_ "SPN" SG_ 2566840592 RetPcTrqAtIdlePnt1 551;
BA_ "SigType" SG_ 2566840592 RetPcTrqAtIdlePnt1 1;
BA_ "CI_ParId" SG_ 2566840592 RetSpeedAtIdlePnt1 "546";
BA_ "CI_SigId" SG_ 2566840592 RetSpeedAtIdlePnt1 1079;
BA_ "CI_SigName" SG_ 2566840592 RetSpeedAtIdlePnt1 "Retarder Speed At Idle, Point 1";
BA_ "GenSigSendType" SG_ 2566840592 RetSpeedAtIdlePnt1 3;
BA_ "GenSigTimeoutTime_PCM" SG_ 2566840592 RetSpeedAtIdlePnt1 25000;
BA_ "SPN" SG_ 2566840592 RetSpeedAtIdlePnt1 546;
BA_ "SigType" SG_ 2566840592 RetSpeedAtIdlePnt1 1;
BA_ "CI_ParId" SG_ 2566840592 RetCtrlMethod "557";
BA_ "CI_SigId" SG_ 2566840592 RetCtrlMethod 1078;
BA_ "CI_SigName" SG_ 2566840592 RetCtrlMethod "Retarder Control Method";
BA_ "GenSigSendType" SG_ 2566840592 RetCtrlMethod 3;
BA_ "GenSigTimeoutTime_PCM" SG_ 2566840592 RetCtrlMethod 25000;
BA_ "SPN" SG_ 2566840592 RetCtrlMethod 557;
BA_ "SigType" SG_ 2566840592 RetCtrlMethod 1;
BA_ "CI_ParId" SG_ 2566840592 RetLoc "902";
BA_ "CI_SigId" SG_ 2566840592 RetLoc 1077;
BA_ "CI_SigName" SG_ 2566840592 RetLoc "Retarder Location";
BA_ "GenSigSendType" SG_ 2566840592 RetLoc 3;
BA_ "GenSigTimeoutTime_PCM" SG_ 2566840592 RetLoc 25000;
BA_ "SPN" SG_ 2566840592 RetLoc 902;
BA_ "CI_ParId" SG_ 2566840592 RetType "901";
BA_ "CI_SigId" SG_ 2566840592 RetType 1076;
BA_ "CI_SigName" SG_ 2566840592 RetType "Retarder Type";
BA_ "GenSigSendType" SG_ 2566840592 RetType 3;
BA_ "GenSigTimeoutTime_PCM" SG_ 2566840592 RetType 25000;
BA_ "SPN" SG_ 2566840592 RetType 901;
BA_ "CI_ParId" SG_ 2565537610 PgnRqst "2540";
BA_ "CI_SigId" SG_ 2565537610 PgnRqst 26958;
BA_ "CI_SigName" SG_ 2565537610 PgnRqst "Parameter Group Number (RQST)";
BA_ "SPN" SG_ 2565537610 PgnRqst 2540;
BA_ "SigType" SG_ 2565537610 PgnRqst 6;
BA_ "CI_ParId" SG_ 2565472330 PgnRqst_EA004A "2540";
BA_ "CI_SigId" SG_ 2565472330 PgnRqst_EA004A 26940;
BA_ "CI_SigName" SG_ 2565472330 PgnRqst_EA004A "Parameter Group Number (RQST)";
BA_ "SPN" SG_ 2565472330 PgnRqst_EA004A 2540;
BA_ "SigType" SG_ 2565472330 PgnRqst_EA004A 6;
BA_ "CI_ParId" SG_ 2565473098 PgnRqst_EA034A "2540";
BA_ "CI_SigId" SG_ 2565473098 PgnRqst_EA034A 26942;
BA_ "CI_SigName" SG_ 2565473098 PgnRqst_EA034A "Parameter Group Number (RQST)";
BA_ "SPN" SG_ 2565473098 PgnRqst_EA034A 2540;
BA_ "SigType" SG_ 2565473098 PgnRqst_EA034A 6;
BA_ "CI_ParId" SG_ 2565474122 PgnRqst_EA074A "2540";
BA_ "CI_SigId" SG_ 2565474122 PgnRqst_EA074A 38657;
BA_ "CI_SigName" SG_ 2565474122 PgnRqst_EA074A "Parameter Group Number (RQST)";
BA_ "SPN" SG_ 2565474122 PgnRqst_EA074A 2540;
BA_ "SigType" SG_ 2565474122 PgnRqst_EA074A 6;
BA_ "CI_ParId" SG_ 2565478986 PgnRqst_EA1A4A "2540";
BA_ "CI_SigId" SG_ 2565478986 PgnRqst_EA1A4A 34421;
BA_ "CI_SigName" SG_ 2565478986 PgnRqst_EA1A4A "Parameter Group Number (RQST)";
BA_ "SPN" SG_ 2565478986 PgnRqst_EA1A4A 2540;
BA_ "SigType" SG_ 2565478986 PgnRqst_EA1A4A 6;
BA_ "CI_ParId" SG_ 2565480778 PgnRqst_EA214A "2540";
BA_ "CI_SigId" SG_ 2565480778 PgnRqst_EA214A 26948;
BA_ "CI_SigName" SG_ 2565480778 PgnRqst_EA214A "Parameter Group Number (RQST)";
BA_ "SPN" SG_ 2565480778 PgnRqst_EA214A 2540;
BA_ "SigType" SG_ 2565480778 PgnRqst_EA214A 6;
BA_ "CI_ParId" SG_ 2565481546 PgnRqst_EA244A "2540";
BA_ "CI_SigId" SG_ 2565481546 PgnRqst_EA244A 38659;
BA_ "CI_SigName" SG_ 2565481546 PgnRqst_EA244A "Parameter Group Number (RQST)";
BA_ "SPN" SG_ 2565481546 PgnRqst_EA244A 2540;
BA_ "SigType" SG_ 2565481546 PgnRqst_EA244A 6;
BA_ "CI_ParId" SG_ 2565482314 PgnRqst_EA274A "2540";
BA_ "CI_SigId" SG_ 2565482314 PgnRqst_EA274A 26950;
BA_ "CI_SigName" SG_ 2565482314 PgnRqst_EA274A "Parameter Group Number (RQST)";
BA_ "SPN" SG_ 2565482314 PgnRqst_EA274A 2540;
BA_ "SigType" SG_ 2565482314 PgnRqst_EA274A 6;
BA_ "CI_ParId" SG_ 2565485386 PgnRqst_EA334A "2540";
BA_ "CI_SigId" SG_ 2565485386 PgnRqst_EA334A 26952;
BA_ "CI_SigName" SG_ 2565485386 PgnRqst_EA334A "Parameter Group Number (RQST)";
BA_ "SPN" SG_ 2565485386 PgnRqst_EA334A 2540;
BA_ "SigType" SG_ 2565485386 PgnRqst_EA334A 6;
BA_ "CI_ParId" SG_ 2565488970 PgnRqst_EA414A "2540";
BA_ "CI_SigId" SG_ 2565488970 PgnRqst_EA414A 26954;
BA_ "CI_SigName" SG_ 2565488970 PgnRqst_EA414A "Parameter Group Number (RQST)";
BA_ "SPN" SG_ 2565488970 PgnRqst_EA414A 2540;
BA_ "SigType" SG_ 2565488970 PgnRqst_EA414A 6;
BA_ "CI_ParId" SG_ 2565491018 PgnRqst_EA494A "2540";
BA_ "CI_SigId" SG_ 2565491018 PgnRqst_EA494A 34423;
BA_ "CI_SigName" SG_ 2565491018 PgnRqst_EA494A "Parameter Group Number (RQST)";
BA_ "SPN" SG_ 2565491018 PgnRqst_EA494A 2540;
BA_ "SigType" SG_ 2565491018 PgnRqst_EA494A 6;
BA_ "CI_ParId" SG_ 2565504074 PgnRqst_EA7C4A "2540";
BA_ "CI_SigId" SG_ 2565504074 PgnRqst_EA7C4A 36877;
BA_ "CI_SigName" SG_ 2565504074 PgnRqst_EA7C4A "Parameter Group Number (RQST)";
BA_ "SPN" SG_ 2565504074 PgnRqst_EA7C4A 2540;
BA_ "SigType" SG_ 2565504074 PgnRqst_EA7C4A 6;
BA_ "CI_ParId" SG_ 2565506634 PgnRqst_EA864A "2540";
BA_ "CI_SigId" SG_ 2565506634 PgnRqst_EA864A 40590;
BA_ "CI_SigName" SG_ 2565506634 PgnRqst_EA864A "Parameter Group Number (RQST)";
BA_ "SPN" SG_ 2565506634 PgnRqst_EA864A 2540;
BA_ "SigType" SG_ 2565506634 PgnRqst_EA864A 6;
BA_ "CI_ParId" SG_ 2565506890 PgnRqst_EA874A "2540";
BA_ "CI_SigId" SG_ 2565506890 PgnRqst_EA874A 40592;
BA_ "CI_SigName" SG_ 2565506890 PgnRqst_EA874A "Parameter Group Number (RQST)";
BA_ "SPN" SG_ 2565506890 PgnRqst_EA874A 2540;
BA_ "SigType" SG_ 2565506890 PgnRqst_EA874A 6;
BA_ "CI_ParId" SG_ 2565533258 PgnRqst_EAEE4A "2540";
BA_ "CI_SigId" SG_ 2565533258 PgnRqst_EAEE4A 26956;
BA_ "CI_SigName" SG_ 2565533258 PgnRqst_EAEE4A "Parameter Group Number (RQST)";
BA_ "SPN" SG_ 2565533258 PgnRqst_EAEE4A 2540;
BA_ "SigType" SG_ 2565533258 PgnRqst_EAEE4A 6;
BA_ "CI_ParId" SG_ 2565533514 PgnRqst_EAEF4A "2540";
BA_ "CI_SigId" SG_ 2565533514 PgnRqst_EAEF4A 34788;
BA_ "CI_SigName" SG_ 2565533514 PgnRqst_EAEF4A "Parameter Group Number (RQST)";
BA_ "SPN" SG_ 2565533514 PgnRqst_EAEF4A 2540;
BA_ "SigType" SG_ 2565533514 PgnRqst_EAEF4A 6;
BA_ "CI_ParId" SG_ 2565534282 PgnRqst_EAF24A "2540";
BA_ "CI_SigId" SG_ 2565534282 PgnRqst_EAF24A 39147;
BA_ "CI_SigName" SG_ 2565534282 PgnRqst_EAF24A "Parameter Group Number (RQST)";
BA_ "SPN" SG_ 2565534282 PgnRqst_EAF24A 2540;
BA_ "SigType" SG_ 2565534282 PgnRqst_EAF24A 6;
BA_ "CI_ParId" SG_ 2565534538 PgnRqst_EAF34A "2540";
BA_ "CI_SigId" SG_ 2565534538 PgnRqst_EAF34A 32809;
BA_ "CI_SigName" SG_ 2565534538 PgnRqst_EAF34A "Parameter Group Number (RQST)";
BA_ "SPN" SG_ 2565534538 PgnRqst_EAF34A 2540;
BA_ "SigType" SG_ 2565534538 PgnRqst_EAF34A 6;
BA_ "CI_ParId" SG_ 2565534794 PgnRqst_EAF44A "2540";
BA_ "CI_SigId" SG_ 2565534794 PgnRqst_EAF44A 26841;
BA_ "CI_SigName" SG_ 2565534794 PgnRqst_EAF44A "Parameter Group Number (RQST)";
BA_ "SPN" SG_ 2565534794 PgnRqst_EAF44A 2540;
BA_ "SigType" SG_ 2565534794 PgnRqst_EAF44A 6;
BA_ "CI_ParId" SG_ 2565535050 PgnRqst_EAF54A "2540";
BA_ "CI_SigId" SG_ 2565535050 PgnRqst_EAF54A 26843;
BA_ "CI_SigName" SG_ 2565535050 PgnRqst_EAF54A "Parameter Group Number (RQST)";
BA_ "SPN" SG_ 2565535050 PgnRqst_EAF54A 2540;
BA_ "SigType" SG_ 2565535050 PgnRqst_EAF54A 6;
BA_ "CI_ParId" SG_ 2565535306 PgnRqst_EAF64A "2540";
BA_ "CI_SigId" SG_ 2565535306 PgnRqst_EAF64A 26845;
BA_ "CI_SigName" SG_ 2565535306 PgnRqst_EAF64A "Parameter Group Number (RQST)";
BA_ "SPN" SG_ 2565535306 PgnRqst_EAF64A 2540;
BA_ "SigType" SG_ 2565535306 PgnRqst_EAF64A 6;
BA_ "CI_ParId" SG_ 2566832128 ServDist "914";
BA_ "CI_SigId" SG_ 2566832128 ServDist 5868;
BA_ "CI_SigName" SG_ 2566832128 ServDist "Service Distance";
BA_ "SPN" SG_ 2566832128 ServDist 914;
BA_ "SigType" SG_ 2566832128 ServDist 1;
BA_ "CI_ParId" SG_ 2566832128 ServCompId "911";
BA_ "CI_SigId" SG_ 2566832128 ServCompId 5867;
BA_ "CI_SigName" SG_ 2566832128 ServCompId "Service Component Identification";
BA_ "SPN" SG_ 2566832128 ServCompId 911;
BA_ "SigType" SG_ 2566832128 ServCompId 1;
BA_ "CI_ParId" SG_ 2566832161 ServDel_OpTimeBased "916";
BA_ "CI_SigId" SG_ 2566832161 ServDel_OpTimeBased 5896;
BA_ "CI_SigName" SG_ 2566832161 ServDel_OpTimeBased "Service Delay/Operational Time Based";
BA_ "GenSigTimeoutTime_PCM" SG_ 2566832161 ServDel_OpTimeBased 5000;
BA_ "SPN" SG_ 2566832161 ServDel_OpTimeBased 916;
BA_ "SigType" SG_ 2566832161 ServDel_OpTimeBased 1;
BA_ "CI_ParId" SG_ 2566832161 ServCompId3 "913";
BA_ "CI_SigId" SG_ 2566832161 ServCompId3 5895;
BA_ "CI_SigName" SG_ 2566832161 ServCompId3 "Service Component Identification 3";
BA_ "GenSigTimeoutTime_PCM" SG_ 2566832161 ServCompId3 5000;
BA_ "SPN" SG_ 2566832161 ServCompId3 913;
BA_ "SigType" SG_ 2566832161 ServCompId3 1;
BA_ "CI_ParId" SG_ 2566832161 ServDel_CalTimeBased "915";
BA_ "CI_SigId" SG_ 2566832161 ServDel_CalTimeBased 5894;
BA_ "CI_SigName" SG_ 2566832161 ServDel_CalTimeBased "Service Delay/Calendar Time Based";
BA_ "GenSigTimeoutTime_PCM" SG_ 2566832161 ServDel_CalTimeBased 5000;
BA_ "SPN" SG_ 2566832161 ServDel_CalTimeBased 915;
BA_ "SigType" SG_ 2566832161 ServDel_CalTimeBased 1;
BA_ "CI_ParId" SG_ 2566832161 ServCompId2 "912";
BA_ "CI_SigId" SG_ 2566832161 ServCompId2 5893;
BA_ "CI_SigName" SG_ 2566832161 ServCompId2 "Service Component Identification 2";
BA_ "GenSigTimeoutTime_PCM" SG_ 2566832161 ServCompId2 5000;
BA_ "SPN" SG_ 2566832161 ServCompId2 912;
BA_ "SigType" SG_ 2566832161 ServCompId2 1;
BA_ "CI_ParId" SG_ 2566832161 ServDist_FEC021 "914";
BA_ "CI_SigId" SG_ 2566832161 ServDist_FEC021 5892;
BA_ "CI_SigName" SG_ 2566832161 ServDist_FEC021 "Service Distance";
BA_ "GenSigTimeoutTime_PCM" SG_ 2566832161 ServDist_FEC021 5000;
BA_ "SPN" SG_ 2566832161 ServDist_FEC021 914;
BA_ "SigType" SG_ 2566832161 ServDist_FEC021 1;
BA_ "CI_ParId" SG_ 2566832161 ServCompId_FEC021 "911";
BA_ "CI_SigId" SG_ 2566832161 ServCompId_FEC021 5891;
BA_ "CI_SigName" SG_ 2566832161 ServCompId_FEC021 "Service Component Identification";
BA_ "GenSigTimeoutTime_PCM" SG_ 2566832161 ServCompId_FEC021 5000;
BA_ "SPN" SG_ 2566832161 ServCompId_FEC021 911;
BA_ "SigType" SG_ 2566832161 ServCompId_FEC021 1;
BA_ "CI_ParId" SG_ 2566832366 ServDel_CalTimeBased_FEC0EE "915";
BA_ "CI_SigId" SG_ 2566832366 ServDel_CalTimeBased_FEC0EE 5920;
BA_ "CI_SigName" SG_ 2566832366 ServDel_CalTimeBased_FEC0EE "Service Delay/Calendar Time Based";
BA_ "SPN" SG_ 2566832366 ServDel_CalTimeBased_FEC0EE 915;
BA_ "SigType" SG_ 2566832366 ServDel_CalTimeBased_FEC0EE 1;
BA_ "CI_ParId" SG_ 2566832366 ServCompId2_FEC0EE "912";
BA_ "CI_SigId" SG_ 2566832366 ServCompId2_FEC0EE 5919;
BA_ "CI_SigName" SG_ 2566832366 ServCompId2_FEC0EE "Service Component Identification 2";
BA_ "SPN" SG_ 2566832366 ServCompId2_FEC0EE 912;
BA_ "SigType" SG_ 2566832366 ServCompId2_FEC0EE 1;
BA_ "CI_ParId" SG_ 2566841344 EngProtSysApprShutdn "1109";
BA_ "CI_SigId" SG_ 2566841344 EngProtSysApprShutdn 2176;
BA_ "CI_SigName" SG_ 2566841344 EngProtSysApprShutdn "Engine Protection System Approaching Shutdown";
BA_ "GenSigTimeoutTime_PCM" SG_ 2566841344 EngProtSysApprShutdn 5000;
BA_ "SPN" SG_ 2566841344 EngProtSysApprShutdn 1109;
BA_ "SigType" SG_ 2566841344 EngProtSysApprShutdn 4;
BA_ "CI_ParId" SG_ 2566841344 EngProtSysHasShutdnEng "1110";
BA_ "CI_SigId" SG_ 2566841344 EngProtSysHasShutdnEng 2175;
BA_ "CI_SigName" SG_ 2566841344 EngProtSysHasShutdnEng "Engine Protection System has Shutdown Engine";
BA_ "GenSigTimeoutTime_PCM" SG_ 2566841344 EngProtSysHasShutdnEng 5000;
BA_ "SPN" SG_ 2566841344 EngProtSysHasShutdnEng 1110;
BA_ "SigType" SG_ 2566841344 EngProtSysHasShutdnEng 4;
BA_ "CI_ParId" SG_ 2566841344 EngWaitToStartLamp "1081";
BA_ "CI_SigId" SG_ 2566841344 EngWaitToStartLamp 2174;
BA_ "CI_SigName" SG_ 2566841344 EngWaitToStartLamp "Engine Wait to Start Lamp";
BA_ "GenSigTimeoutTime_PCM" SG_ 2566841344 EngWaitToStartLamp 5000;
BA_ "SPN" SG_ 2566841344 EngWaitToStartLamp 1081;
BA_ "SigType" SG_ 2566841344 EngWaitToStartLamp 4;
BA_ "CI_ParId" SG_ 2566838789 SwIdField5 "234";
BA_ "CI_SigId" SG_ 2566838789 SwIdField5 26229;
BA_ "CI_SigName" SG_ 2566838789 SwIdField5 "Software Identification - Field 5";
BA_ "SPN" SG_ 2566838789 SwIdField5 234;
BA_ "SigType" SG_ 2566838789 SwIdField5 8;
BA_ "CI_ParId" SG_ 2566838789 SwIdField4 "234";
BA_ "CI_SigId" SG_ 2566838789 SwIdField4 26228;
BA_ "CI_SigName" SG_ 2566838789 SwIdField4 "Software Identification - Field 4";
BA_ "SPN" SG_ 2566838789 SwIdField4 234;
BA_ "SigType" SG_ 2566838789 SwIdField4 8;
BA_ "CI_ParId" SG_ 2566838789 SwIdField3 "234";
BA_ "CI_SigId" SG_ 2566838789 SwIdField3 26227;
BA_ "CI_SigName" SG_ 2566838789 SwIdField3 "Software Identification - Field 3";
BA_ "SPN" SG_ 2566838789 SwIdField3 234;
BA_ "SigType" SG_ 2566838789 SwIdField3 8;
BA_ "CI_ParId" SG_ 2566838789 SwIdField2 "234";
BA_ "CI_SigId" SG_ 2566838789 SwIdField2 26226;
BA_ "CI_SigName" SG_ 2566838789 SwIdField2 "Software Identification - Field 2";
BA_ "SPN" SG_ 2566838789 SwIdField2 234;
BA_ "SigType" SG_ 2566838789 SwIdField2 8;
BA_ "CI_ParId" SG_ 2566838789 SwIdField1 "234";
BA_ "CI_SigId" SG_ 2566838789 SwIdField1 26225;
BA_ "CI_SigName" SG_ 2566838789 SwIdField1 "Software Identification - Field 1";
BA_ "SPN" SG_ 2566838789 SwIdField1 234;
BA_ "SigType" SG_ 2566838789 SwIdField1 8;
BA_ "CI_ParId" SG_ 2566838789 NumOfSwIdFields "965";
BA_ "CI_SigId" SG_ 2566838789 NumOfSwIdFields 26224;
BA_ "CI_SigName" SG_ 2566838789 NumOfSwIdFields "Number of Software Identification Fields";
BA_ "SPN" SG_ 2566838789 NumOfSwIdFields 965;
BA_ "SigType" SG_ 2566838789 NumOfSwIdFields 1;
BA_ "CI_ParId" SG_ 2566838791 SwIdField5_FEDA07 "234";
BA_ "CI_SigId" SG_ 2566838791 SwIdField5_FEDA07 38564;
BA_ "CI_SigName" SG_ 2566838791 SwIdField5_FEDA07 "Software Identification - Field 5";
BA_ "SPN" SG_ 2566838791 SwIdField5_FEDA07 234;
BA_ "SigType" SG_ 2566838791 SwIdField5_FEDA07 8;
BA_ "CI_ParId" SG_ 2566838791 SwIdField4_FEDA07 "234";
BA_ "CI_SigId" SG_ 2566838791 SwIdField4_FEDA07 38563;
BA_ "CI_SigName" SG_ 2566838791 SwIdField4_FEDA07 "Software Identification - Field 4";
BA_ "SPN" SG_ 2566838791 SwIdField4_FEDA07 234;
BA_ "SigType" SG_ 2566838791 SwIdField4_FEDA07 8;
BA_ "CI_ParId" SG_ 2566838791 SwIdField3_FEDA07 "234";
BA_ "CI_SigId" SG_ 2566838791 SwIdField3_FEDA07 38562;
BA_ "CI_SigName" SG_ 2566838791 SwIdField3_FEDA07 "Software Identification - Field 3";
BA_ "SPN" SG_ 2566838791 SwIdField3_FEDA07 234;
BA_ "SigType" SG_ 2566838791 SwIdField3_FEDA07 8;
BA_ "CI_ParId" SG_ 2566838791 SwIdField2_FEDA07 "234";
BA_ "CI_SigId" SG_ 2566838791 SwIdField2_FEDA07 38561;
BA_ "CI_SigName" SG_ 2566838791 SwIdField2_FEDA07 "Software Identification - Field 2";
BA_ "SPN" SG_ 2566838791 SwIdField2_FEDA07 234;
BA_ "SigType" SG_ 2566838791 SwIdField2_FEDA07 8;
BA_ "CI_ParId" SG_ 2566838791 SwIdField1_FEDA07 "234";
BA_ "CI_SigId" SG_ 2566838791 SwIdField1_FEDA07 38560;
BA_ "CI_SigName" SG_ 2566838791 SwIdField1_FEDA07 "Software Identification - Field 1";
BA_ "SPN" SG_ 2566838791 SwIdField1_FEDA07 234;
BA_ "SigType" SG_ 2566838791 SwIdField1_FEDA07 8;
BA_ "CI_ParId" SG_ 2566838791 NumOfSwIdFields_FEDA07 "965";
BA_ "CI_SigId" SG_ 2566838791 NumOfSwIdFields_FEDA07 38559;
BA_ "CI_SigName" SG_ 2566838791 NumOfSwIdFields_FEDA07 "Number of Software Identification Fields";
BA_ "SPN" SG_ 2566838791 NumOfSwIdFields_FEDA07 965;
BA_ "SigType" SG_ 2566838791 NumOfSwIdFields_FEDA07 1;
BA_ "CI_ParId" SG_ 2566838810 SwIdField5_FEDA1A "234";
BA_ "CI_SigId" SG_ 2566838810 SwIdField5_FEDA1A 34492;
BA_ "CI_SigName" SG_ 2566838810 SwIdField5_FEDA1A "Software Identification - Field 5";
BA_ "SPN" SG_ 2566838810 SwIdField5_FEDA1A 234;
BA_ "SigType" SG_ 2566838810 SwIdField5_FEDA1A 8;
BA_ "CI_ParId" SG_ 2566838810 SwIdField4_FEDA1A "234";
BA_ "CI_SigId" SG_ 2566838810 SwIdField4_FEDA1A 34491;
BA_ "CI_SigName" SG_ 2566838810 SwIdField4_FEDA1A "Software Identification - Field 4";
BA_ "SPN" SG_ 2566838810 SwIdField4_FEDA1A 234;
BA_ "SigType" SG_ 2566838810 SwIdField4_FEDA1A 8;
BA_ "CI_ParId" SG_ 2566838810 SwIdField3_FEDA1A "234";
BA_ "CI_SigId" SG_ 2566838810 SwIdField3_FEDA1A 34490;
BA_ "CI_SigName" SG_ 2566838810 SwIdField3_FEDA1A "Software Identification - Field 3";
BA_ "SPN" SG_ 2566838810 SwIdField3_FEDA1A 234;
BA_ "SigType" SG_ 2566838810 SwIdField3_FEDA1A 8;
BA_ "CI_ParId" SG_ 2566838810 SwIdField2_FEDA1A "234";
BA_ "CI_SigId" SG_ 2566838810 SwIdField2_FEDA1A 34489;
BA_ "CI_SigName" SG_ 2566838810 SwIdField2_FEDA1A "Software Identification - Field 2";
BA_ "SPN" SG_ 2566838810 SwIdField2_FEDA1A 234;
BA_ "SigType" SG_ 2566838810 SwIdField2_FEDA1A 8;
BA_ "CI_ParId" SG_ 2566838810 SwIdField1_FEDA1A "234";
BA_ "CI_SigId" SG_ 2566838810 SwIdField1_FEDA1A 34488;
BA_ "CI_SigName" SG_ 2566838810 SwIdField1_FEDA1A "Software Identification - Field 1";
BA_ "SPN" SG_ 2566838810 SwIdField1_FEDA1A 234;
BA_ "SigType" SG_ 2566838810 SwIdField1_FEDA1A 8;
BA_ "CI_ParId" SG_ 2566838810 NumOfSwIdFields_FEDA1A "965";
BA_ "CI_SigId" SG_ 2566838810 NumOfSwIdFields_FEDA1A 34487;
BA_ "CI_SigName" SG_ 2566838810 NumOfSwIdFields_FEDA1A "Number of Software Identification Fields";
BA_ "SPN" SG_ 2566838810 NumOfSwIdFields_FEDA1A 965;
BA_ "SigType" SG_ 2566838810 NumOfSwIdFields_FEDA1A 1;
BA_ "CI_ParId" SG_ 2566838813 SwIdField5_FEDA1D "234";
BA_ "CI_SigId" SG_ 2566838813 SwIdField5_FEDA1D 26285;
BA_ "CI_SigName" SG_ 2566838813 SwIdField5_FEDA1D "Software Identification - Field 5";
BA_ "SPN" SG_ 2566838813 SwIdField5_FEDA1D 234;
BA_ "SigType" SG_ 2566838813 SwIdField5_FEDA1D 8;
BA_ "CI_ParId" SG_ 2566838813 SwIdField4_FEDA1D "234";
BA_ "CI_SigId" SG_ 2566838813 SwIdField4_FEDA1D 26284;
BA_ "CI_SigName" SG_ 2566838813 SwIdField4_FEDA1D "Software Identification - Field 4";
BA_ "SPN" SG_ 2566838813 SwIdField4_FEDA1D 234;
BA_ "SigType" SG_ 2566838813 SwIdField4_FEDA1D 8;
BA_ "CI_ParId" SG_ 2566838813 SwIdField3_FEDA1D "234";
BA_ "CI_SigId" SG_ 2566838813 SwIdField3_FEDA1D 26283;
BA_ "CI_SigName" SG_ 2566838813 SwIdField3_FEDA1D "Software Identification - Field 3";
BA_ "SPN" SG_ 2566838813 SwIdField3_FEDA1D 234;
BA_ "SigType" SG_ 2566838813 SwIdField3_FEDA1D 8;
BA_ "CI_ParId" SG_ 2566838813 SwIdField2_FEDA1D "234";
BA_ "CI_SigId" SG_ 2566838813 SwIdField2_FEDA1D 26282;
BA_ "CI_SigName" SG_ 2566838813 SwIdField2_FEDA1D "Software Identification - Field 2";
BA_ "SPN" SG_ 2566838813 SwIdField2_FEDA1D 234;
BA_ "SigType" SG_ 2566838813 SwIdField2_FEDA1D 8;
BA_ "CI_ParId" SG_ 2566838813 SwIdField1_FEDA1D "234";
BA_ "CI_SigId" SG_ 2566838813 SwIdField1_FEDA1D 26281;
BA_ "CI_SigName" SG_ 2566838813 SwIdField1_FEDA1D "Software Identification - Field 1";
BA_ "SPN" SG_ 2566838813 SwIdField1_FEDA1D 234;
BA_ "SigType" SG_ 2566838813 SwIdField1_FEDA1D 8;
BA_ "CI_ParId" SG_ 2566838813 NumOfSwIdFields_FEDA1D "965";
BA_ "CI_SigId" SG_ 2566838813 NumOfSwIdFields_FEDA1D 26280;
BA_ "CI_SigName" SG_ 2566838813 NumOfSwIdFields_FEDA1D "Number of Software Identification Fields";
BA_ "SPN" SG_ 2566838813 NumOfSwIdFields_FEDA1D 965;
BA_ "SigType" SG_ 2566838813 NumOfSwIdFields_FEDA1D 1;
BA_ "CI_ParId" SG_ 2566838820 SwIdField5_FEDA24 "234";
BA_ "CI_SigId" SG_ 2566838820 SwIdField5_FEDA24 38571;
BA_ "CI_SigName" SG_ 2566838820 SwIdField5_FEDA24 "Software Identification - Field 5";
BA_ "SPN" SG_ 2566838820 SwIdField5_FEDA24 234;
BA_ "SigType" SG_ 2566838820 SwIdField5_FEDA24 8;
BA_ "CI_ParId" SG_ 2566838820 SwIdField4_FEDA24 "234";
BA_ "CI_SigId" SG_ 2566838820 SwIdField4_FEDA24 38570;
BA_ "CI_SigName" SG_ 2566838820 SwIdField4_FEDA24 "Software Identification - Field 4";
BA_ "SPN" SG_ 2566838820 SwIdField4_FEDA24 234;
BA_ "SigType" SG_ 2566838820 SwIdField4_FEDA24 8;
BA_ "CI_ParId" SG_ 2566838820 SwIdField3_FEDA24 "234";
BA_ "CI_SigId" SG_ 2566838820 SwIdField3_FEDA24 38569;
BA_ "CI_SigName" SG_ 2566838820 SwIdField3_FEDA24 "Software Identification - Field 3";
BA_ "SPN" SG_ 2566838820 SwIdField3_FEDA24 234;
BA_ "SigType" SG_ 2566838820 SwIdField3_FEDA24 8;
BA_ "CI_ParId" SG_ 2566838820 SwIdField2_FEDA24 "234";
BA_ "CI_SigId" SG_ 2566838820 SwIdField2_FEDA24 38568;
BA_ "CI_SigName" SG_ 2566838820 SwIdField2_FEDA24 "Software Identification - Field 2";
BA_ "SPN" SG_ 2566838820 SwIdField2_FEDA24 234;
BA_ "SigType" SG_ 2566838820 SwIdField2_FEDA24 8;
BA_ "CI_ParId" SG_ 2566838820 SwIdField1_FEDA24 "234";
BA_ "CI_SigId" SG_ 2566838820 SwIdField1_FEDA24 38567;
BA_ "CI_SigName" SG_ 2566838820 SwIdField1_FEDA24 "Software Identification - Field 1";
BA_ "SPN" SG_ 2566838820 SwIdField1_FEDA24 234;
BA_ "SigType" SG_ 2566838820 SwIdField1_FEDA24 8;
BA_ "CI_ParId" SG_ 2566838820 NumOfSwIdFields_FEDA24 "965";
BA_ "CI_SigId" SG_ 2566838820 NumOfSwIdFields_FEDA24 38566;
BA_ "CI_SigName" SG_ 2566838820 NumOfSwIdFields_FEDA24 "Number of Software Identification Fields";
BA_ "SPN" SG_ 2566838820 NumOfSwIdFields_FEDA24 965;
BA_ "SigType" SG_ 2566838820 NumOfSwIdFields_FEDA24 1;
BA_ "CI_ParId" SG_ 2566838823 SwIdField5_FEDA27 "234";
BA_ "CI_SigId" SG_ 2566838823 SwIdField5_FEDA27 26299;
BA_ "CI_SigName" SG_ 2566838823 SwIdField5_FEDA27 "Software Identification - Field 5";
BA_ "SPN" SG_ 2566838823 SwIdField5_FEDA27 234;
BA_ "SigType" SG_ 2566838823 SwIdField5_FEDA27 8;
BA_ "CI_ParId" SG_ 2566838823 SwIdField4_FEDA27 "234";
BA_ "CI_SigId" SG_ 2566838823 SwIdField4_FEDA27 26298;
BA_ "CI_SigName" SG_ 2566838823 SwIdField4_FEDA27 "Software Identification - Field 4";
BA_ "SPN" SG_ 2566838823 SwIdField4_FEDA27 234;
BA_ "SigType" SG_ 2566838823 SwIdField4_FEDA27 8;
BA_ "CI_ParId" SG_ 2566838823 SwIdField3_FEDA27 "234";
BA_ "CI_SigId" SG_ 2566838823 SwIdField3_FEDA27 26297;
BA_ "CI_SigName" SG_ 2566838823 SwIdField3_FEDA27 "Software Identification - Field 3";
BA_ "SPN" SG_ 2566838823 SwIdField3_FEDA27 234;
BA_ "SigType" SG_ 2566838823 SwIdField3_FEDA27 8;
BA_ "CI_ParId" SG_ 2566838823 SwIdField2_FEDA27 "234";
BA_ "CI_SigId" SG_ 2566838823 SwIdField2_FEDA27 26296;
BA_ "CI_SigName" SG_ 2566838823 SwIdField2_FEDA27 "Software Identification - Field 2";
BA_ "SPN" SG_ 2566838823 SwIdField2_FEDA27 234;
BA_ "SigType" SG_ 2566838823 SwIdField2_FEDA27 8;
BA_ "CI_ParId" SG_ 2566838823 SwIdField1_FEDA27 "234";
BA_ "CI_SigId" SG_ 2566838823 SwIdField1_FEDA27 26295;
BA_ "CI_SigName" SG_ 2566838823 SwIdField1_FEDA27 "Software Identification - Field 1";
BA_ "SPN" SG_ 2566838823 SwIdField1_FEDA27 234;
BA_ "SigType" SG_ 2566838823 SwIdField1_FEDA27 8;
BA_ "CI_ParId" SG_ 2566838823 NumOfSwIdFields_FEDA27 "965";
BA_ "CI_SigId" SG_ 2566838823 NumOfSwIdFields_FEDA27 26294;
BA_ "CI_SigName" SG_ 2566838823 NumOfSwIdFields_FEDA27 "Number of Software Identification Fields";
BA_ "SPN" SG_ 2566838823 NumOfSwIdFields_FEDA27 965;
BA_ "SigType" SG_ 2566838823 NumOfSwIdFields_FEDA27 1;
BA_ "CI_ParId" SG_ 2566838831 SwIdField5_FEDA2F "234";
BA_ "CI_SigId" SG_ 2566838831 SwIdField5_FEDA2F 26313;
BA_ "CI_SigName" SG_ 2566838831 SwIdField5_FEDA2F "Software Identification - Field 5";
BA_ "SPN" SG_ 2566838831 SwIdField5_FEDA2F 234;
BA_ "SigType" SG_ 2566838831 SwIdField5_FEDA2F 8;
BA_ "CI_ParId" SG_ 2566838831 SwIdField4_FEDA2F "234";
BA_ "CI_SigId" SG_ 2566838831 SwIdField4_FEDA2F 26312;
BA_ "CI_SigName" SG_ 2566838831 SwIdField4_FEDA2F "Software Identification - Field 4";
BA_ "SPN" SG_ 2566838831 SwIdField4_FEDA2F 234;
BA_ "SigType" SG_ 2566838831 SwIdField4_FEDA2F 8;
BA_ "CI_ParId" SG_ 2566838831 SwIdField3_FEDA2F "234";
BA_ "CI_SigId" SG_ 2566838831 SwIdField3_FEDA2F 26311;
BA_ "CI_SigName" SG_ 2566838831 SwIdField3_FEDA2F "Software Identification - Field 3";
BA_ "SPN" SG_ 2566838831 SwIdField3_FEDA2F 234;
BA_ "SigType" SG_ 2566838831 SwIdField3_FEDA2F 8;
BA_ "CI_ParId" SG_ 2566838831 SwIdField2_FEDA2F "234";
BA_ "CI_SigId" SG_ 2566838831 SwIdField2_FEDA2F 26310;
BA_ "CI_SigName" SG_ 2566838831 SwIdField2_FEDA2F "Software Identification - Field 2";
BA_ "SPN" SG_ 2566838831 SwIdField2_FEDA2F 234;
BA_ "SigType" SG_ 2566838831 SwIdField2_FEDA2F 8;
BA_ "CI_ParId" SG_ 2566838831 SwIdField1_FEDA2F "234";
BA_ "CI_SigId" SG_ 2566838831 SwIdField1_FEDA2F 26309;
BA_ "CI_SigName" SG_ 2566838831 SwIdField1_FEDA2F "Software Identification - Field 1";
BA_ "SPN" SG_ 2566838831 SwIdField1_FEDA2F 234;
BA_ "SigType" SG_ 2566838831 SwIdField1_FEDA2F 8;
BA_ "CI_ParId" SG_ 2566838831 NumOfSwIdFields_FEDA2F "965";
BA_ "CI_SigId" SG_ 2566838831 NumOfSwIdFields_FEDA2F 26308;
BA_ "CI_SigName" SG_ 2566838831 NumOfSwIdFields_FEDA2F "Number of Software Identification Fields";
BA_ "SPN" SG_ 2566838831 NumOfSwIdFields_FEDA2F 965;
BA_ "SigType" SG_ 2566838831 NumOfSwIdFields_FEDA2F 1;
BA_ "CI_ParId" SG_ 2566838832 SwIdField5_FEDA30 "234";
BA_ "CI_SigId" SG_ 2566838832 SwIdField5_FEDA30 34820;
BA_ "CI_SigName" SG_ 2566838832 SwIdField5_FEDA30 "Software Identification - Field 5";
BA_ "SPN" SG_ 2566838832 SwIdField5_FEDA30 234;
BA_ "SigType" SG_ 2566838832 SwIdField5_FEDA30 8;
BA_ "CI_ParId" SG_ 2566838832 SwIdField4_FEDA30 "234";
BA_ "CI_SigId" SG_ 2566838832 SwIdField4_FEDA30 34819;
BA_ "CI_SigName" SG_ 2566838832 SwIdField4_FEDA30 "Software Identification - Field 4";
BA_ "SPN" SG_ 2566838832 SwIdField4_FEDA30 234;
BA_ "SigType" SG_ 2566838832 SwIdField4_FEDA30 8;
BA_ "CI_ParId" SG_ 2566838832 SwIdField3_FEDA30 "234";
BA_ "CI_SigId" SG_ 2566838832 SwIdField3_FEDA30 34818;
BA_ "CI_SigName" SG_ 2566838832 SwIdField3_FEDA30 "Software Identification - Field 3";
BA_ "SPN" SG_ 2566838832 SwIdField3_FEDA30 234;
BA_ "SigType" SG_ 2566838832 SwIdField3_FEDA30 8;
BA_ "CI_ParId" SG_ 2566838832 SwIdField2_FEDA30 "234";
BA_ "CI_SigId" SG_ 2566838832 SwIdField2_FEDA30 34817;
BA_ "CI_SigName" SG_ 2566838832 SwIdField2_FEDA30 "Software Identification - Field 2";
BA_ "SPN" SG_ 2566838832 SwIdField2_FEDA30 234;
BA_ "SigType" SG_ 2566838832 SwIdField2_FEDA30 8;
BA_ "CI_ParId" SG_ 2566838832 SwIdField1_FEDA30 "234";
BA_ "CI_SigId" SG_ 2566838832 SwIdField1_FEDA30 34816;
BA_ "CI_SigName" SG_ 2566838832 SwIdField1_FEDA30 "Software Identification - Field 1";
BA_ "SPN" SG_ 2566838832 SwIdField1_FEDA30 234;
BA_ "SigType" SG_ 2566838832 SwIdField1_FEDA30 8;
BA_ "CI_ParId" SG_ 2566838832 NumOfSwIdFields_FEDA30 "965";
BA_ "CI_SigId" SG_ 2566838832 NumOfSwIdFields_FEDA30 34815;
BA_ "CI_SigName" SG_ 2566838832 NumOfSwIdFields_FEDA30 "Number of Software Identification Fields";
BA_ "SPN" SG_ 2566838832 NumOfSwIdFields_FEDA30 965;
BA_ "SigType" SG_ 2566838832 NumOfSwIdFields_FEDA30 1;
BA_ "CI_ParId" SG_ 2566838835 SwIdField5_FEDA33 "234";
BA_ "CI_SigId" SG_ 2566838835 SwIdField5_FEDA33 26320;
BA_ "CI_SigName" SG_ 2566838835 SwIdField5_FEDA33 "Software Identification - Field 5";
BA_ "SPN" SG_ 2566838835 SwIdField5_FEDA33 234;
BA_ "SigType" SG_ 2566838835 SwIdField5_FEDA33 8;
BA_ "CI_ParId" SG_ 2566838835 SwIdField4_FEDA33 "234";
BA_ "CI_SigId" SG_ 2566838835 SwIdField4_FEDA33 26319;
BA_ "CI_SigName" SG_ 2566838835 SwIdField4_FEDA33 "Software Identification - Field 4";
BA_ "SPN" SG_ 2566838835 SwIdField4_FEDA33 234;
BA_ "SigType" SG_ 2566838835 SwIdField4_FEDA33 8;
BA_ "CI_ParId" SG_ 2566838835 SwIdField3_FEDA33 "234";
BA_ "CI_SigId" SG_ 2566838835 SwIdField3_FEDA33 26318;
BA_ "CI_SigName" SG_ 2566838835 SwIdField3_FEDA33 "Software Identification - Field 3";
BA_ "SPN" SG_ 2566838835 SwIdField3_FEDA33 234;
BA_ "SigType" SG_ 2566838835 SwIdField3_FEDA33 8;
BA_ "CI_ParId" SG_ 2566838835 SwIdField2_FEDA33 "234";
BA_ "CI_SigId" SG_ 2566838835 SwIdField2_FEDA33 26317;
BA_ "CI_SigName" SG_ 2566838835 SwIdField2_FEDA33 "Software Identification - Field 2";
BA_ "SPN" SG_ 2566838835 SwIdField2_FEDA33 234;
BA_ "SigType" SG_ 2566838835 SwIdField2_FEDA33 8;
BA_ "CI_ParId" SG_ 2566838835 SwIdField1_FEDA33 "234";
BA_ "CI_SigId" SG_ 2566838835 SwIdField1_FEDA33 26316;
BA_ "CI_SigName" SG_ 2566838835 SwIdField1_FEDA33 "Software Identification - Field 1";
BA_ "SPN" SG_ 2566838835 SwIdField1_FEDA33 234;
BA_ "SigType" SG_ 2566838835 SwIdField1_FEDA33 8;
BA_ "CI_ParId" SG_ 2566838835 NumOfSwIdFields_FEDA33 "965";
BA_ "CI_SigId" SG_ 2566838835 NumOfSwIdFields_FEDA33 26315;
BA_ "CI_SigName" SG_ 2566838835 NumOfSwIdFields_FEDA33 "Number of Software Identification Fields";
BA_ "SPN" SG_ 2566838835 NumOfSwIdFields_FEDA33 965;
BA_ "SigType" SG_ 2566838835 NumOfSwIdFields_FEDA33 1;
BA_ "CI_ParId" SG_ 2566838849 SwIdField5_FEDA41 "234";
BA_ "CI_SigId" SG_ 2566838849 SwIdField5_FEDA41 26334;
BA_ "CI_SigName" SG_ 2566838849 SwIdField5_FEDA41 "Software Identification - Field 5";
BA_ "SPN" SG_ 2566838849 SwIdField5_FEDA41 234;
BA_ "SigType" SG_ 2566838849 SwIdField5_FEDA41 8;
BA_ "CI_ParId" SG_ 2566838849 SwIdField4_FEDA41 "234";
BA_ "CI_SigId" SG_ 2566838849 SwIdField4_FEDA41 26333;
BA_ "CI_SigName" SG_ 2566838849 SwIdField4_FEDA41 "Software Identification - Field 4";
BA_ "SPN" SG_ 2566838849 SwIdField4_FEDA41 234;
BA_ "SigType" SG_ 2566838849 SwIdField4_FEDA41 8;
BA_ "CI_ParId" SG_ 2566838849 SwIdField3_FEDA41 "234";
BA_ "CI_SigId" SG_ 2566838849 SwIdField3_FEDA41 26332;
BA_ "CI_SigName" SG_ 2566838849 SwIdField3_FEDA41 "Software Identification - Field 3";
BA_ "SPN" SG_ 2566838849 SwIdField3_FEDA41 234;
BA_ "SigType" SG_ 2566838849 SwIdField3_FEDA41 8;
BA_ "CI_ParId" SG_ 2566838849 SwIdField2_FEDA41 "234";
BA_ "CI_SigId" SG_ 2566838849 SwIdField2_FEDA41 26331;
BA_ "CI_SigName" SG_ 2566838849 SwIdField2_FEDA41 "Software Identification - Field 2";
BA_ "SPN" SG_ 2566838849 SwIdField2_FEDA41 234;
BA_ "SigType" SG_ 2566838849 SwIdField2_FEDA41 8;
BA_ "CI_ParId" SG_ 2566838849 SwIdField1_FEDA41 "234";
BA_ "CI_SigId" SG_ 2566838849 SwIdField1_FEDA41 26330;
BA_ "CI_SigName" SG_ 2566838849 SwIdField1_FEDA41 "Software Identification - Field 1";
BA_ "SPN" SG_ 2566838849 SwIdField1_FEDA41 234;
BA_ "SigType" SG_ 2566838849 SwIdField1_FEDA41 8;
BA_ "CI_ParId" SG_ 2566838849 NumOfSwIdFields_FEDA41 "965";
BA_ "CI_SigId" SG_ 2566838849 NumOfSwIdFields_FEDA41 26329;
BA_ "CI_SigName" SG_ 2566838849 NumOfSwIdFields_FEDA41 "Number of Software Identification Fields";
BA_ "SPN" SG_ 2566838849 NumOfSwIdFields_FEDA41 965;
BA_ "SigType" SG_ 2566838849 NumOfSwIdFields_FEDA41 1;
BA_ "CI_ParId" SG_ 2566838857 SwIdField5_FEDA49 "234";
BA_ "CI_SigId" SG_ 2566838857 SwIdField5_FEDA49 34499;
BA_ "CI_SigName" SG_ 2566838857 SwIdField5_FEDA49 "Software Identification - Field 5";
BA_ "SPN" SG_ 2566838857 SwIdField5_FEDA49 234;
BA_ "SigType" SG_ 2566838857 SwIdField5_FEDA49 8;
BA_ "CI_ParId" SG_ 2566838857 SwIdField4_FEDA49 "234";
BA_ "CI_SigId" SG_ 2566838857 SwIdField4_FEDA49 34498;
BA_ "CI_SigName" SG_ 2566838857 SwIdField4_FEDA49 "Software Identification - Field 4";
BA_ "SPN" SG_ 2566838857 SwIdField4_FEDA49 234;
BA_ "SigType" SG_ 2566838857 SwIdField4_FEDA49 8;
BA_ "CI_ParId" SG_ 2566838857 SwIdField3_FEDA49 "234";
BA_ "CI_SigId" SG_ 2566838857 SwIdField3_FEDA49 34497;
BA_ "CI_SigName" SG_ 2566838857 SwIdField3_FEDA49 "Software Identification - Field 3";
BA_ "SPN" SG_ 2566838857 SwIdField3_FEDA49 234;
BA_ "SigType" SG_ 2566838857 SwIdField3_FEDA49 8;
BA_ "CI_ParId" SG_ 2566838857 SwIdField2_FEDA49 "234";
BA_ "CI_SigId" SG_ 2566838857 SwIdField2_FEDA49 34496;
BA_ "CI_SigName" SG_ 2566838857 SwIdField2_FEDA49 "Software Identification - Field 2";
BA_ "SPN" SG_ 2566838857 SwIdField2_FEDA49 234;
BA_ "SigType" SG_ 2566838857 SwIdField2_FEDA49 8;
BA_ "CI_ParId" SG_ 2566838857 SwIdField1_FEDA49 "234";
BA_ "CI_SigId" SG_ 2566838857 SwIdField1_FEDA49 34495;
BA_ "CI_SigName" SG_ 2566838857 SwIdField1_FEDA49 "Software Identification - Field 1";
BA_ "SPN" SG_ 2566838857 SwIdField1_FEDA49 234;
BA_ "SigType" SG_ 2566838857 SwIdField1_FEDA49 8;
BA_ "CI_ParId" SG_ 2566838857 NumOfSwIdFields_FEDA49 "965";
BA_ "CI_SigId" SG_ 2566838857 NumOfSwIdFields_FEDA49 34494;
BA_ "CI_SigName" SG_ 2566838857 NumOfSwIdFields_FEDA49 "Number of Software Identification Fields";
BA_ "SPN" SG_ 2566838857 NumOfSwIdFields_FEDA49 965;
BA_ "SigType" SG_ 2566838857 NumOfSwIdFields_FEDA49 1;
BA_ "CI_ParId" SG_ 2566838858 SwIdField5_FEDA4A "234";
BA_ "CI_SigId" SG_ 2566838858 SwIdField5_FEDA4A 26369;
BA_ "CI_SigName" SG_ 2566838858 SwIdField5_FEDA4A "Software Identification - Field 5";
BA_ "SPN" SG_ 2566838858 SwIdField5_FEDA4A 234;
BA_ "SigType" SG_ 2566838858 SwIdField5_FEDA4A 8;
BA_ "CI_ParId" SG_ 2566838858 SwIdField4_FEDA4A "234";
BA_ "CI_SigId" SG_ 2566838858 SwIdField4_FEDA4A 26368;
BA_ "CI_SigName" SG_ 2566838858 SwIdField4_FEDA4A "Software Identification - Field 4";
BA_ "SPN" SG_ 2566838858 SwIdField4_FEDA4A 234;
BA_ "SigType" SG_ 2566838858 SwIdField4_FEDA4A 8;
BA_ "CI_ParId" SG_ 2566838858 SwIdField3_FEDA4A "234";
BA_ "CI_SigId" SG_ 2566838858 SwIdField3_FEDA4A 26367;
BA_ "CI_SigName" SG_ 2566838858 SwIdField3_FEDA4A "Software Identification - Field 3";
BA_ "SPN" SG_ 2566838858 SwIdField3_FEDA4A 234;
BA_ "SigType" SG_ 2566838858 SwIdField3_FEDA4A 8;
BA_ "CI_ParId" SG_ 2566838858 SwIdField2_FEDA4A "234";
BA_ "CI_SigId" SG_ 2566838858 SwIdField2_FEDA4A 26366;
BA_ "CI_SigName" SG_ 2566838858 SwIdField2_FEDA4A "Software Identification - Field 2";
BA_ "SPN" SG_ 2566838858 SwIdField2_FEDA4A 234;
BA_ "SigType" SG_ 2566838858 SwIdField2_FEDA4A 8;
BA_ "CI_ParId" SG_ 2566838858 SwIdField1_FEDA4A "234";
BA_ "CI_SigId" SG_ 2566838858 SwIdField1_FEDA4A 26365;
BA_ "CI_SigName" SG_ 2566838858 SwIdField1_FEDA4A "Software Identification - Field 1";
BA_ "SPN" SG_ 2566838858 SwIdField1_FEDA4A 234;
BA_ "SigType" SG_ 2566838858 SwIdField1_FEDA4A 8;
BA_ "CI_ParId" SG_ 2566838858 NumOfSwIdFields_FEDA4A "965";
BA_ "CI_SigId" SG_ 2566838858 NumOfSwIdFields_FEDA4A 26364;
BA_ "CI_SigName" SG_ 2566838858 NumOfSwIdFields_FEDA4A "Number of Software Identification Fields";
BA_ "SPN" SG_ 2566838858 NumOfSwIdFields_FEDA4A 965;
BA_ "SigType" SG_ 2566838858 NumOfSwIdFields_FEDA4A 1;
BA_ "CI_ParId" SG_ 2566838861 SwIdField5_FEDA4D "234";
BA_ "CI_SigId" SG_ 2566838861 SwIdField5_FEDA4D 37248;
BA_ "CI_SigName" SG_ 2566838861 SwIdField5_FEDA4D "Software Identification - Field 5";
BA_ "SPN" SG_ 2566838861 SwIdField5_FEDA4D 234;
BA_ "SigType" SG_ 2566838861 SwIdField5_FEDA4D 8;
BA_ "CI_ParId" SG_ 2566838861 SwIdField4_FEDA4D "234";
BA_ "CI_SigId" SG_ 2566838861 SwIdField4_FEDA4D 37247;
BA_ "CI_SigName" SG_ 2566838861 SwIdField4_FEDA4D "Software Identification - Field 4";
BA_ "SPN" SG_ 2566838861 SwIdField4_FEDA4D 234;
BA_ "SigType" SG_ 2566838861 SwIdField4_FEDA4D 8;
BA_ "CI_ParId" SG_ 2566838861 SwIdField3_FEDA4D "234";
BA_ "CI_SigId" SG_ 2566838861 SwIdField3_FEDA4D 37246;
BA_ "CI_SigName" SG_ 2566838861 SwIdField3_FEDA4D "Software Identification - Field 3";
BA_ "SPN" SG_ 2566838861 SwIdField3_FEDA4D 234;
BA_ "SigType" SG_ 2566838861 SwIdField3_FEDA4D 8;
BA_ "CI_ParId" SG_ 2566838861 SwIdField2_FEDA4D "234";
BA_ "CI_SigId" SG_ 2566838861 SwIdField2_FEDA4D 37245;
BA_ "CI_SigName" SG_ 2566838861 SwIdField2_FEDA4D "Software Identification - Field 2";
BA_ "SPN" SG_ 2566838861 SwIdField2_FEDA4D 234;
BA_ "SigType" SG_ 2566838861 SwIdField2_FEDA4D 8;
BA_ "CI_ParId" SG_ 2566838861 SwIdField1_FEDA4D "234";
BA_ "CI_SigId" SG_ 2566838861 SwIdField1_FEDA4D 37244;
BA_ "CI_SigName" SG_ 2566838861 SwIdField1_FEDA4D "Software Identification - Field 1";
BA_ "SPN" SG_ 2566838861 SwIdField1_FEDA4D 234;
BA_ "SigType" SG_ 2566838861 SwIdField1_FEDA4D 8;
BA_ "CI_ParId" SG_ 2566838861 NumOfSwIdFields_FEDA4D "965";
BA_ "CI_SigId" SG_ 2566838861 NumOfSwIdFields_FEDA4D 37243;
BA_ "CI_SigName" SG_ 2566838861 NumOfSwIdFields_FEDA4D "Number of Software Identification Fields";
BA_ "SPN" SG_ 2566838861 NumOfSwIdFields_FEDA4D 965;
BA_ "SigType" SG_ 2566838861 NumOfSwIdFields_FEDA4D 1;
BA_ "CI_ParId" SG_ 2566838904 SwIdField5_FEDA78 "234";
BA_ "CI_SigId" SG_ 2566838904 SwIdField5_FEDA78 40201;
BA_ "CI_SigName" SG_ 2566838904 SwIdField5_FEDA78 "Software Identification - Field 5";
BA_ "SPN" SG_ 2566838904 SwIdField5_FEDA78 234;
BA_ "SigType" SG_ 2566838904 SwIdField5_FEDA78 8;
BA_ "CI_ParId" SG_ 2566838904 SwIdField4_FEDA78 "234";
BA_ "CI_SigId" SG_ 2566838904 SwIdField4_FEDA78 40200;
BA_ "CI_SigName" SG_ 2566838904 SwIdField4_FEDA78 "Software Identification - Field 4";
BA_ "SPN" SG_ 2566838904 SwIdField4_FEDA78 234;
BA_ "SigType" SG_ 2566838904 SwIdField4_FEDA78 8;
BA_ "CI_ParId" SG_ 2566838904 SwIdField3_FEDA78 "234";
BA_ "CI_SigId" SG_ 2566838904 SwIdField3_FEDA78 40199;
BA_ "CI_SigName" SG_ 2566838904 SwIdField3_FEDA78 "Software Identification - Field 3";
BA_ "SPN" SG_ 2566838904 SwIdField3_FEDA78 234;
BA_ "SigType" SG_ 2566838904 SwIdField3_FEDA78 8;
BA_ "CI_ParId" SG_ 2566838904 SwIdField2_FEDA78 "234";
BA_ "CI_SigId" SG_ 2566838904 SwIdField2_FEDA78 40198;
BA_ "CI_SigName" SG_ 2566838904 SwIdField2_FEDA78 "Software Identification - Field 2";
BA_ "SPN" SG_ 2566838904 SwIdField2_FEDA78 234;
BA_ "SigType" SG_ 2566838904 SwIdField2_FEDA78 8;
BA_ "CI_ParId" SG_ 2566838904 SwIdField1_FEDA78 "234";
BA_ "CI_SigId" SG_ 2566838904 SwIdField1_FEDA78 40197;
BA_ "CI_SigName" SG_ 2566838904 SwIdField1_FEDA78 "Software Identification - Field 1";
BA_ "SPN" SG_ 2566838904 SwIdField1_FEDA78 234;
BA_ "SigType" SG_ 2566838904 SwIdField1_FEDA78 8;
BA_ "CI_ParId" SG_ 2566838904 NumOfSwIdFields_FEDA78 "965";
BA_ "CI_SigId" SG_ 2566838904 NumOfSwIdFields_FEDA78 40196;
BA_ "CI_SigName" SG_ 2566838904 NumOfSwIdFields_FEDA78 "Number of Software Identification Fields";
BA_ "SPN" SG_ 2566838904 NumOfSwIdFields_FEDA78 965;
BA_ "SigType" SG_ 2566838904 NumOfSwIdFields_FEDA78 1;
BA_ "CI_ParId" SG_ 2566838908 SwIdField5_FEDA7C "234";
BA_ "CI_SigId" SG_ 2566838908 SwIdField5_FEDA7C 36833;
BA_ "CI_SigName" SG_ 2566838908 SwIdField5_FEDA7C "Software Identification - Field 5";
BA_ "SPN" SG_ 2566838908 SwIdField5_FEDA7C 234;
BA_ "SigType" SG_ 2566838908 SwIdField5_FEDA7C 8;
BA_ "CI_ParId" SG_ 2566838908 SwIdField4_FEDA7C "234";
BA_ "CI_SigId" SG_ 2566838908 SwIdField4_FEDA7C 36832;
BA_ "CI_SigName" SG_ 2566838908 SwIdField4_FEDA7C "Software Identification - Field 4";
BA_ "SPN" SG_ 2566838908 SwIdField4_FEDA7C 234;
BA_ "SigType" SG_ 2566838908 SwIdField4_FEDA7C 8;
BA_ "CI_ParId" SG_ 2566838908 SwIdField3_FEDA7C "234";
BA_ "CI_SigId" SG_ 2566838908 SwIdField3_FEDA7C 36831;
BA_ "CI_SigName" SG_ 2566838908 SwIdField3_FEDA7C "Software Identification - Field 3";
BA_ "SPN" SG_ 2566838908 SwIdField3_FEDA7C 234;
BA_ "SigType" SG_ 2566838908 SwIdField3_FEDA7C 8;
BA_ "CI_ParId" SG_ 2566838908 SwIdField2_FEDA7C "234";
BA_ "CI_SigId" SG_ 2566838908 SwIdField2_FEDA7C 36830;
BA_ "CI_SigName" SG_ 2566838908 SwIdField2_FEDA7C "Software Identification - Field 2";
BA_ "SPN" SG_ 2566838908 SwIdField2_FEDA7C 234;
BA_ "SigType" SG_ 2566838908 SwIdField2_FEDA7C 8;
BA_ "CI_ParId" SG_ 2566838908 SwIdField1_FEDA7C "234";
BA_ "CI_SigId" SG_ 2566838908 SwIdField1_FEDA7C 36829;
BA_ "CI_SigName" SG_ 2566838908 SwIdField1_FEDA7C "Software Identification - Field 1";
BA_ "SPN" SG_ 2566838908 SwIdField1_FEDA7C 234;
BA_ "SigType" SG_ 2566838908 SwIdField1_FEDA7C 8;
BA_ "CI_ParId" SG_ 2566838908 NumOfSwIdFields_FEDA7C "965";
BA_ "CI_SigId" SG_ 2566838908 NumOfSwIdFields_FEDA7C 36828;
BA_ "CI_SigName" SG_ 2566838908 NumOfSwIdFields_FEDA7C "Number of Software Identification Fields";
BA_ "SPN" SG_ 2566838908 NumOfSwIdFields_FEDA7C 965;
BA_ "SigType" SG_ 2566838908 NumOfSwIdFields_FEDA7C 1;
BA_ "CI_ParId" SG_ 2566839023 SwIdField5_FEDAEF "234";
BA_ "CI_SigId" SG_ 2566839023 SwIdField5_FEDAEF 34800;
BA_ "CI_SigName" SG_ 2566839023 SwIdField5_FEDAEF "Software Identification - Field 5";
BA_ "SPN" SG_ 2566839023 SwIdField5_FEDAEF 234;
BA_ "SigType" SG_ 2566839023 SwIdField5_FEDAEF 8;
BA_ "CI_ParId" SG_ 2566839023 SwIdField4_FEDAEF "234";
BA_ "CI_SigId" SG_ 2566839023 SwIdField4_FEDAEF 34799;
BA_ "CI_SigName" SG_ 2566839023 SwIdField4_FEDAEF "Software Identification - Field 4";
BA_ "SPN" SG_ 2566839023 SwIdField4_FEDAEF 234;
BA_ "SigType" SG_ 2566839023 SwIdField4_FEDAEF 8;
BA_ "CI_ParId" SG_ 2566839023 SwIdField3_FEDAEF "234";
BA_ "CI_SigId" SG_ 2566839023 SwIdField3_FEDAEF 34798;
BA_ "CI_SigName" SG_ 2566839023 SwIdField3_FEDAEF "Software Identification - Field 3";
BA_ "SPN" SG_ 2566839023 SwIdField3_FEDAEF 234;
BA_ "SigType" SG_ 2566839023 SwIdField3_FEDAEF 8;
BA_ "CI_ParId" SG_ 2566839023 SwIdField2_FEDAEF "234";
BA_ "CI_SigId" SG_ 2566839023 SwIdField2_FEDAEF 34797;
BA_ "CI_SigName" SG_ 2566839023 SwIdField2_FEDAEF "Software Identification - Field 2";
BA_ "SPN" SG_ 2566839023 SwIdField2_FEDAEF 234;
BA_ "SigType" SG_ 2566839023 SwIdField2_FEDAEF 8;
BA_ "CI_ParId" SG_ 2566839023 SwIdField1_FEDAEF "234";
BA_ "CI_SigId" SG_ 2566839023 SwIdField1_FEDAEF 34796;
BA_ "CI_SigName" SG_ 2566839023 SwIdField1_FEDAEF "Software Identification - Field 1";
BA_ "SPN" SG_ 2566839023 SwIdField1_FEDAEF 234;
BA_ "SigType" SG_ 2566839023 SwIdField1_FEDAEF 8;
BA_ "CI_ParId" SG_ 2566839023 NumOfSwIdFields_FEDAEF "965";
BA_ "CI_SigId" SG_ 2566839023 NumOfSwIdFields_FEDAEF 34795;
BA_ "CI_SigName" SG_ 2566839023 NumOfSwIdFields_FEDAEF "Number of Software Identification Fields";
BA_ "SPN" SG_ 2566839023 NumOfSwIdFields_FEDAEF 965;
BA_ "SigType" SG_ 2566839023 NumOfSwIdFields_FEDAEF 1;
BA_ "CI_ParId" SG_ 2566839026 SwIdField5_FEDAF2 "234";
BA_ "CI_SigId" SG_ 2566839026 SwIdField5_FEDAF2 39088;
BA_ "CI_SigName" SG_ 2566839026 SwIdField5_FEDAF2 "Software Identification - Field 5";
BA_ "SPN" SG_ 2566839026 SwIdField5_FEDAF2 234;
BA_ "SigType" SG_ 2566839026 SwIdField5_FEDAF2 8;
BA_ "CI_ParId" SG_ 2566839026 SwIdField4_FEDAF2 "234";
BA_ "CI_SigId" SG_ 2566839026 SwIdField4_FEDAF2 39087;
BA_ "CI_SigName" SG_ 2566839026 SwIdField4_FEDAF2 "Software Identification - Field 4";
BA_ "SPN" SG_ 2566839026 SwIdField4_FEDAF2 234;
BA_ "SigType" SG_ 2566839026 SwIdField4_FEDAF2 8;
BA_ "CI_ParId" SG_ 2566839026 SwIdField3_FEDAF2 "234";
BA_ "CI_SigId" SG_ 2566839026 SwIdField3_FEDAF2 39086;
BA_ "CI_SigName" SG_ 2566839026 SwIdField3_FEDAF2 "Software Identification - Field 3";
BA_ "SPN" SG_ 2566839026 SwIdField3_FEDAF2 234;
BA_ "SigType" SG_ 2566839026 SwIdField3_FEDAF2 8;
BA_ "CI_ParId" SG_ 2566839026 SwIdField2_FEDAF2 "234";
BA_ "CI_SigId" SG_ 2566839026 SwIdField2_FEDAF2 39085;
BA_ "CI_SigName" SG_ 2566839026 SwIdField2_FEDAF2 "Software Identification - Field 2";
BA_ "SPN" SG_ 2566839026 SwIdField2_FEDAF2 234;
BA_ "SigType" SG_ 2566839026 SwIdField2_FEDAF2 8;
BA_ "CI_ParId" SG_ 2566839026 SwIdField1_FEDAF2 "234";
BA_ "CI_SigId" SG_ 2566839026 SwIdField1_FEDAF2 39084;
BA_ "CI_SigName" SG_ 2566839026 SwIdField1_FEDAF2 "Software Identification - Field 1";
BA_ "SPN" SG_ 2566839026 SwIdField1_FEDAF2 234;
BA_ "SigType" SG_ 2566839026 SwIdField1_FEDAF2 8;
BA_ "CI_ParId" SG_ 2566839026 NumOfSwIdFields_FEDAF2 "965";
BA_ "CI_SigId" SG_ 2566839026 NumOfSwIdFields_FEDAF2 39083;
BA_ "CI_SigName" SG_ 2566839026 NumOfSwIdFields_FEDAF2 "Number of Software Identification Fields";
BA_ "SPN" SG_ 2566839026 NumOfSwIdFields_FEDAF2 965;
BA_ "SigType" SG_ 2566839026 NumOfSwIdFields_FEDAF2 1;
BA_ "CI_ParId" SG_ 2566839027 SwIdField5_FEDAF3 "234";
BA_ "CI_SigId" SG_ 2566839027 SwIdField5_FEDAF3 33386;
BA_ "CI_SigName" SG_ 2566839027 SwIdField5_FEDAF3 "Software Identification - Field 5";
BA_ "SPN" SG_ 2566839027 SwIdField5_FEDAF3 234;
BA_ "SigType" SG_ 2566839027 SwIdField5_FEDAF3 8;
BA_ "CI_ParId" SG_ 2566839027 SwIdField4_FEDAF3 "234";
BA_ "CI_SigId" SG_ 2566839027 SwIdField4_FEDAF3 33385;
BA_ "CI_SigName" SG_ 2566839027 SwIdField4_FEDAF3 "Software Identification - Field 4";
BA_ "SPN" SG_ 2566839027 SwIdField4_FEDAF3 234;
BA_ "SigType" SG_ 2566839027 SwIdField4_FEDAF3 8;
BA_ "CI_ParId" SG_ 2566839027 SwIdField3_FEDAF3 "234";
BA_ "CI_SigId" SG_ 2566839027 SwIdField3_FEDAF3 33384;
BA_ "CI_SigName" SG_ 2566839027 SwIdField3_FEDAF3 "Software Identification - Field 3";
BA_ "SPN" SG_ 2566839027 SwIdField3_FEDAF3 234;
BA_ "SigType" SG_ 2566839027 SwIdField3_FEDAF3 8;
BA_ "CI_ParId" SG_ 2566839027 SwIdField2_FEDAF3 "234";
BA_ "CI_SigId" SG_ 2566839027 SwIdField2_FEDAF3 33383;
BA_ "CI_SigName" SG_ 2566839027 SwIdField2_FEDAF3 "Software Identification - Field 2";
BA_ "SPN" SG_ 2566839027 SwIdField2_FEDAF3 234;
BA_ "SigType" SG_ 2566839027 SwIdField2_FEDAF3 8;
BA_ "CI_ParId" SG_ 2566839027 SwIdField1_FEDAF3 "234";
BA_ "CI_SigId" SG_ 2566839027 SwIdField1_FEDAF3 33382;
BA_ "CI_SigName" SG_ 2566839027 SwIdField1_FEDAF3 "Software Identification - Field 1";
BA_ "SPN" SG_ 2566839027 SwIdField1_FEDAF3 234;
BA_ "SigType" SG_ 2566839027 SwIdField1_FEDAF3 8;
BA_ "CI_ParId" SG_ 2566839027 NumOfSwIdFields_FEDAF3 "965";
BA_ "CI_SigId" SG_ 2566839027 NumOfSwIdFields_FEDAF3 33381;
BA_ "CI_SigName" SG_ 2566839027 NumOfSwIdFields_FEDAF3 "Number of Software Identification Fields";
BA_ "SPN" SG_ 2566839027 NumOfSwIdFields_FEDAF3 965;
BA_ "SigType" SG_ 2566839027 NumOfSwIdFields_FEDAF3 1;
BA_ "CI_ParId" SG_ 2364543755 PitchAngleFigOfMerit "3323";
BA_ "CI_SigId" SG_ 2364543755 PitchAngleFigOfMerit 895;
BA_ "CI_SigName" SG_ 2364543755 PitchAngleFigOfMerit "Pitch Angle Figure of Merit";
BA_ "GenSigTimeoutTime_PCM" SG_ 2364543755 PitchAngleFigOfMerit 500;
BA_ "SPN" SG_ 2364543755 PitchAngleFigOfMerit 3323;
BA_ "SigType" SG_ 2364543755 PitchAngleFigOfMerit 4;
BA_ "CI_ParId" SG_ 2364543755 PitchAngle "3318";
BA_ "CI_SigId" SG_ 2364543755 PitchAngle 892;
BA_ "CI_SigName" SG_ 2364543755 PitchAngle "Pitch Angle";
BA_ "GenSigTimeoutTime_PCM" SG_ 2364543755 PitchAngle 500;
BA_ "SPN" SG_ 2364543755 PitchAngle 3318;
BA_ "SigType" SG_ 2364543755 PitchAngle 1;
VAL_ 2566912807 VacuumPumpFail 0 "No Failure Detected" 1 "Failure Detected" 2 "Error" 3 "Not available" ;
VAL_ 2566912807 ParkLckFail 0 "No Failure Detected" 1 "Failure Detected" 2 "Error" 3 "Not available" ;
VAL_ 2566912807 ElLoadPrio 0 "No Selection" 1 "Only Batteries" 2 "Batteries + ePTO" 3 "Batteries + HVAC" 4 "Batteries + ePTO + HVAC" 5 "Reserved" 6 "Error" 7 "Not Available" ;
VAL_ 2566912807 HvacFunctSts 0 "Compressor Active" 1 "Compressor Derating" 2 "PTC Cabin Active" 3 "PTC Cabin Derating" 4 "Reserved" 5 "Reserved" 6 "Error" 7 "Not Available/ No Action" ;
VAL_ 2566912807 VmuHvSysSevFail 0 "No Failure Detected" 1 "Failure Detected" 2 "Error" 3 "Not available" ;
VAL_ 2566912807 VmuHvBatFail 0 "No Failure Detected" 1 "Failure Detected" 2 "Error" 3 "Not available" ;
VAL_ 2566912807 FastChgMode 0 "Standby" 1 "Fast Charging" 2 "Error" 3 "Not Available" ;
VAL_ 2566912807 SlowChgMode 0 "Standby" 1 "Slow Charging" 2 "Error" 3 "Not Available" ;
VAL_ 2566912807 EnergyInstEcon 64256 "Infinite" ;
VAL_ 2566892839 ParkBrkCmd_FFAD27 0 "Apply not requested" 1 "Apply requested" 2 "Reserved" 3 "Don�t Care / Take no action" ;
VAL_ 2566904641 RoadType 0 "Motorway" 4 "Major high importance road" 5 "Other major road" 6 "Secondary road" 8 "Local connecting road" 9 "Local high importance road" 10 "Residential connecting road" 12 "Residential road" 13 "Other road" 14 "Forbidden Road" 254 "Error Indicator" 255 "Not Available" ;
VAL_ 2566904641 NavSymCode2 0 "0x00" 1 "Arrival" 2 "BearLeft" 3 "BearRight" 4 "BifurcationBearLeft" 5 "BifurcationBearRight" 6 "BifurcationKeepLeft" 7 "BifurcationKeepLeftLane" 8 "BifurcationKeepRight" 9 "BifurcationKeepRightLane" 10 "TurnLeftThenEnterFreeway" 11 "TurnLeftThenEnterMotorway" 12 "TurnLeftThenReachDestination" 13 "TurnLeftThenReachFerry" 14 "TurnLeftThenTurnLeft" 15 "TurnLeftThenTurnRight" 16 "TurnRightThenEnterFreeway" 17 "TurnRightThenEnterMotorway" 18 "TurnRightThenReachDestination" 19 "TurnRightThenReachFerry" 20 "TurnRightThenTurnLeft" 21 "TurnRightThenTurnRight" 22 "Ferry" 23 "Freeway" 25 "Left" 26 "Right" 27 "RoundaboutBearLeft" 28 "RoundaboutBearRight" 29 "RoundaboutLeft" 30 "RoundaboutRight" 31 "RoundaboutSharpLeft" 32 "RoundaboutSharpRight" 33 "RoundaboutStraight" 34 "RoundaboutUkBearLeft" 35 "RoundaboutUkBearRight" 36 "RoundaboutUkLeft" 37 "RoundaboutUkSharpLeft" 38 "RoundaboutUkSharpRight" 39 "RoundaboutUkStraight" 40 "RoundaboutUkRight" 41 "RoundaboutUTurn" 42 "RoundaboutUkUTurn" 43 "SharpLeft" 44 "SharpRight" 45 "Straight" 46 "TurnLeft" 47 "TurnRight" 48 "Lets-go" 49 "NextInstructArrowTurnLeft2" 50 "NextInstructArrowTurnLeft3" 51 "NextInstructArrowTurnRight2" 52 "NextInstructArrowTurnRight3" 53 "NextInstructIcWaypoint" 60 "TurnLeftThenReachNextStop" 61 "TurnRightThenReachNextStop" 62 "ReCalculatingRoute" 63 "Navigation Stopped" 254 "Error Indicator" 255 "Not Available" ;
VAL_ 2566904641 DistToNextEvt 65024 "Error Indicator" 65535 "Not Available" ;
VAL_ 2566904641 DistResolIx 0 "1" 1 "0.1" 2 "0.01" 3 "Not Available" ;
VAL_ 2566904641 DistUnitsIx 0 "kilometer" 1 "meter" 2 "miles" 3 "feet" 4 "yards" 5 "Reserved" 6 "Reserved" 7 "Not Available" ;
VAL_ 2566892311 RearCrossTrafficAlertFunctCfg 0 "Disable" 1 "Enable" 2 "Error" 3 "Not Available" ;
VAL_ 2566892311 RearCrossTrafficAlertAcousticWar 0 "Disable" 1 "Enable" 2 "Error" 3 "Not Available" ;
VAL_ 2566892311 BlindSpotFunctCfg 0 "Disable" 1 "Enable" 2 "Error" 3 "Not Available" ;
VAL_ 2566892311 BlindSpotAcousticWarnCfg 0 "Disable" 1 "Enable" 2 "Error" 3 "Not Available" ;
VAL_ 2566892362 ZZS_22_18FFAB4A 0 "Disable" 1 "Enable" 2 "Error" 3 "Not Available" ;
VAL_ 2566892362 ZZS_20_18FFAB4A 0 "Disable" 1 "Enable" 2 "Error" 3 "Not Available" ;
VAL_ 2566892362 BlindSpotFunctCfg_FFAB4A 0 "Disable" 1 "Enable" 2 "Error" 3 "Not Available" ;
VAL_ 2566892362 BlindSpotAcousticWarnCfg_FFAB4A 0 "Disable" 1 "Enable" 2 "Error" 3 "Not Available" ;
VAL_ 2566892444 ObjTypeDetSts 0 "Object Not Detected" 1 "Pedestrian" 2 "Cyclist" 3 "Pedestrian and Cyclist" 4 "Generic" 5 "Licensed Vehicle" 6 "Error" 7 "Not Available" ;
VAL_ 2566892444 RearCrossTrafficAlertRightWarnIn 0 "No warning" 1 "Visual Warning" 2 "Not Used1" 3 "Collision Warn Lev 2 (acute)" 4 "Warning with Braking" 5 "Not Used2" 6 "Not Used3" 7 "Not Available" ;
VAL_ 2566892444 RearCrossTrafficAlertLeftWarnInf 0 "No warning" 1 "Visual Warning" 2 "Not Used1" 3 "Collision Warn Lev 2 (acute)" 4 "Warning with Braking" 5 "Not Used2" 6 "Not Used3" 7 "Not Available" ;
VAL_ 2566892444 BlindSpotRightWarnInfo 0 "No warning" 1 "Visual Warning" 2 "Not Used" 3 "Collision Warn Lev 2 (acute)" 7 "Not Available" ;
VAL_ 2566892444 BlindSpotLeftWarnInfo 0 "No warning" 1 "Visual Warning" 2 "Not Used" 3 "Collision Warn Lev 2 (acute)" 7 "Not Available" ;
VAL_ 2566892444 RearCrossTrafficAlertSts 0 "Initialization" 1 "Passive (function disabled)" 2 "Active (function enabled)" 3 "Not Used" 4 "Not Used" 5 "Not Used" 6 "Error/System Failure" 7 "Not Available/System Disabled" ;
VAL_ 2566892444 BlindSpotSts 0 "Initialization" 1 "Passive (function disabled)" 2 "Active (function enabled)" 3 "Not Used" 4 "Not Used" 5 "Not Used" 6 "Error/System Failure" 7 "NotAvailable/System Disabled" ;
VAL_ 2566892444 RctTypeOfFunctSts 0 "Function w warning only" 1 "Function w Braking" 2 "Function in Error" 3 "Function Not Available" ;
VAL_ 2566892567 BsisAcousticWarnCfg 0 "Disable" 1 "Enable" 2 "Error" 3 "Not Available" ;
VAL_ 2566892567 MoisFunctCfg 0 "Disable" 1 "Enable" 2 "Error" 3 "Not Available" ;
VAL_ 2566892567 MoisAcousticWarnCfg 0 "Disable" 1 "Enable" 2 "Error" 3 "Not Available" ;
VAL_ 2566892618 BsisAcousticWarnCfg_FFAC4A 0 "Disable" 1 "Enable" 2 "Error" 3 "Not Available" ;
VAL_ 2566892702 ObjTypeDetSts_FFAC9E 0 "Object Not Detected" 1 "Pedestrian" 2 "Cyclist" 3 "Pedestrian and Cyclist" 4 "Generic" 5 "Licensed Vehicle" 6 "Error" 7 "Not Available" ;
VAL_ 2566892702 MoisFunctSts 0 "Stand-by" 1 "Active" 2 "Not Used1" 3 "No operation" 4 "Function Disabled by driver" 5 "Not Used2" 6 "Not Used3" 7 "Not Available" ;
VAL_ 2566892702 MoisWarnInfo 0 "No warning" 1 "VRU Present Info" 2 "Collision Warn Lev 1" 3 "Collision Warn Lev 2 (acute)" 4 "Warning with Braking" 7 "Not Available" ;
VAL_ 2566892702 MoisSts 0 "Initialization" 1 "In Operation" 2 "System failure" 3 "Automatically Deactivated" 4 "Not Used1" 5 "Not Used2" 6 "Not Used3" 7 "Not available/System Disabled" ;
VAL_ 2566892702 MoisTypeOfFunctSts 0 "Function w warning only" 1 "Function w Braking" 2 "Function in Error" 3 "Function Not Available" ;
VAL_ 2566892703 ObjTypeDetSts_FFAC9F 0 "Object Not Detected" 1 "Pedestrian" 2 "Cyclist" 3 "Pedestrian and Cyclist" 4 "Generic" 5 "Licensed Vehicle" 6 "Error" 7 "Not Available" ;
VAL_ 2566892703 BsisFunctSts 0 "Stand-by" 1 "Active" 2 "Not Used1" 3 "No operation" 4 "Not Used2" 5 "Not Used3" 6 "Not Used4" 7 "Not Available" ;
VAL_ 2566892703 BsisWarnInfo 0 "No warning" 1 "VRU Present Info" 2 "Collision Warn Lev 1" 3 "Collision Warn Lev 2 (acute)" 4 "Warning with Braking" 7 "Not Available" ;
VAL_ 2566892703 BsisSts 0 "Initialization" 1 "In Operation" 2 "System failure" 3 "Automatically Deactivated" 4 "Not Used1" 5 "Not Used2" 6 "Not Used3" 7 "Not available/System Disabled" ;
VAL_ 2566892703 BsisTypeOfFunctSts 0 "Function w warning only" 1 "Function w Braking" 2 "Function in Error" 3 "Function Not Available" ;
VAL_ 2566865010 PtoDegrModeIx 0 "PTO1 No faults active" 1 "PTO1 Brake" 2 "PTO1 Handbrake" 3 "PTO1 BC/EM input" 4 "PTO1 Clutch" 5 "PTO1 Gear" 6 "PTO1 RPM" 7 "PTO1 Vehicle Speed" 8 "PTO1 Water Temp" 9 "PTO1 Eurotronic (MHCV only)" 10 "PTO1 Low eng. oil prs (LCV only)" 11 "PTO1 ESV (LCV only)" 15 "PTO2 Brake" 16 "PTO2 Handbrake" 17 "PTO2 BC/EM input" 18 "PTO2 Clutch" 19 "PTO2 Gear" 20 "PTO2 RPM" 21 "PTO2 Vehicle Speed" 22 "PTO2 Water Temp" 23 "PTO2 Eurotronic (MHCV only)" 24 "PTO1 Low eng. oil prs (LCV only)" 29 "PTO3 Brake" 30 "PTO3 Handbrake" 31 "PTO3 BC/EM input" 32 "PTO3 Clutch" 33 "PTO3 Gear" 34 "PTO3 RPM" 35 "PTO3 Vehicle Speed" 36 "PTO3 Water Temp" 37 "PTO3 Eurotronic (MHCV only)" 38 "PTO3 Low eng. oil prs (LCV only)" 255 "Transitorial time active" ;
VAL_ 2566865010 Pto3EsvCtrl 0 "No Shutoff/ Engage restr. active" 1 "Shutoff/ Engage restr. active" ;
VAL_ 2566865010 Pto3LowOilPrs 0 "No Shutoff/ Engage restr. active" 1 "Shutoff/ Engage restr. active" ;
VAL_ 2566865010 Pto3Et2Ctrl 0 "No Shutoff/ Engage restr. active" 1 "Shutoff/ Engage restr. active" ;
VAL_ 2566865010 Pto3WaterTemp 0 "Water temp in range" 1 "Water temp out of range" ;
VAL_ 2566865010 Pto3VehSpeed 0 "Vehicle speed in range" 1 "Vehicle speed out of range" ;
VAL_ 2566865010 Pto3EngRpm 0 "No Shutoff/ Engage restr. active" 1 "Shutoff/ Engage restr. active" ;
VAL_ 2566865010 Pto3Gear 0 "No Shutoff/ Engage restr. active" 1 "Shutoff/ Engage restr. active" ;
VAL_ 2566865010 Pto3Clt 0 "No Shutoff/ Engage restr. active" 1 "Shutoff/ Engage restr. active" ;
VAL_ 2566865010 Pto3Handbrake 0 "No Shutoff/ Engage restr. active" 1 "Shutoff/ Engage restr. active" ;
VAL_ 2566865010 Pto3Brk 0 "No Shutoff/ Engage restr. active" 1 "Shutoff/ Engage restr. active" ;
VAL_ 2566865010 Pto3DegrOpMode 0 "Not active" 1 "Active not confirmed" 2 "Active confirmed" 3 "Active PTO mission deleted" ;
VAL_ 2566865010 Pto2EsvCtrl 0 "No Shutoff/ Engage restr. active" 1 "Shutoff/ Engage restr. active" ;
VAL_ 2566865010 Pto2LowOilPrs 0 "No Shutoff/ Engage restr. active" 1 "Shutoff/ Engage restr. active" ;
VAL_ 2566865010 Pto2Et2Ctrl 0 "No Shutoff/ Engage restr. active" 1 "Shutoff/ Engage restr. active" ;
VAL_ 2566865010 Pto2WaterTemp 0 "No Shutoff/ Engage restr. active" 1 "Shutoff/ Engage restr. active" ;
VAL_ 2566865010 Pto2VehSpeed 0 "No Shutoff/ Engage restr. active" 1 "Shutoff/ Engage restr. active" ;
VAL_ 2566865010 Pto2EngRpm 0 "No Shutoff/ Engage restr. active" 1 "Shutoff/ Engage restr. active" ;
VAL_ 2566865010 Pto2Gear 0 "No Shutoff/ Engage restr. active" 1 "Shutoff/ Engage restr. active" ;
VAL_ 2566865010 Pto2Clt 0 "No Shutoff/ Engage restr. active" 1 "Shutoff/ Engage restr. active" ;
VAL_ 2566865010 Pto2Handbrake 0 "No Shutoff/ Engage restr. active" 1 "Shutoff/ Engage restr. active" ;
VAL_ 2566865010 Pto2Brk 0 "No Shutoff/ Engage restr. active" 1 "Shutoff/ Engage restr. active" ;
VAL_ 2566865010 Pto2DegrOpMode 0 "Not active" 1 "Active not confirmed" 2 "Active confirmed" 3 "Active PTO mission deleted" ;
VAL_ 2566865010 Pto1EsvCtrl 0 "No Shutoff/ Engage restr. active" 1 "Shutoff/ Engage restr. active" ;
VAL_ 2566865010 Pto1LowOilPrs 0 "No Shutoff/ Engage restr. active" 1 "Shutoff/ Engage restr. active" ;
VAL_ 2566865010 Pto1Et2Ctrl 0 "No Shutoff/ Engage restr. active" 1 "Shutoff/ Engage restr. active" ;
VAL_ 2566865010 Pto1WaterTemp 0 "No Shutoff/ Engage restr. active" 1 "Shutoff/ Engage restr. active" ;
VAL_ 2566865010 Pto1VehSpeed 0 "No Shutoff/ Engage restr. active" 1 "Shutoff/ Engage restr. active" ;
VAL_ 2566865010 Pto1EngRpm 0 "No Shutoff/ Engage restr. active" 1 "Shutoff/ Engage restr. active" ;
VAL_ 2566865010 Pto1Gear 0 "No Shutoff/ Engage restr. active" 1 "Shutoff/ Engage restr. active" ;
VAL_ 2566865010 Pto1Clt 0 "No Shutoff/ Engage restr. active" 1 "Shutoff/ Engage restr. active" ;
VAL_ 2566865010 Pto1Handbrake 0 "No Shutoff/ Engage restr. active" 1 "Shutoff/ Engage restr. active" ;
VAL_ 2566865010 Pto1Brk 0 "No Shutoff/ Engage restr. active" 1 "Shutoff/ Engage restr. active" ;
VAL_ 2566865010 Pto1DegrOpMode 0 "Not active" 1 "Active not confirmed" 2 "Active confirmed" 3 "Active PTO mission deleted" ;
VAL_ 2566865010 Pto1EngdSts 0 "Not engaged" 1 "Engaged" 2 "Requested (Error on Daily)" 3 "Not installed" ;
VAL_ 2566865010 Pto2EngdSts 0 "Not engaged" 1 "Engaged" 2 "Requested (Error on Daily)" 3 "Not installed" ;
VAL_ 2566865010 Pto3EngdSts 0 "Not engaged" 1 "Engaged" 2 "Requested (Error on Daily)" 3 "Not installed" ;
VAL_ 2566865010 DegrModeSts 0 "Not active" 1 "Active not confirmed" 2 "Active confirmed" 3 "Active PTO mission deleted" ;
VAL_ 2566840592 RetCtrlMethod 0 "Continuous control" 1 "On/Off control" ;
VAL_ 2566840592 RetLoc 0 "Primary, Eng. Compr. or CEB" 1 "Primary, Eng. Exhaust Brake" 2 "Primary, Transm. Input" 3 "Secondary, Transm. Output" 4 "Secondary, Driveline" 5 "Trailer, Vehicle speed" 14 "Other" 15 "Not Available" ;
VAL_ 2566840592 RetType 0 "Electric/Magnetic" 1 "Hydraulic" 2 "Cooled Friction" 3 "Compr. Release (Eng Ret) or CEB" 4 "Exhaust" 14 "Other" 15 "Not Available" ;
VAL_ 2565537610 PgnRqst 37120 "VLSI1" 40448 "DM29" 41216 "DM33" 41728 "DM31" 41984 "DM30" 47360 "PLLT (Plan List Lifetime)" 47872 "PLD (Plan List Distance)" 49408 "DM21" 49664 "DM20" 49920 "DM22" 53504 "MaintBcIc" 54016 "DM19" 60928 "ACL" 61184 "STOD" 64341 "HVESP3HIST" 64342 "HVESP3CFG" 64343 "HVESP2HIST" 64344 "HVESP2CFG" 64345 "HVESP1HIST" 64346 "HVESP1CFG" 64529 "TGFI" 64579 "TCSI" 64582 "TSIS" 64583 "MTI" 64605 "HVESSCFG" 64606 "HVESSHIST" 64653 "PII" 64701 "A1SCRSI2" 64782 "AT1OGC2" 64784 "AT1IGC2" 64839 "TML" 64879 "EEC8" 64896 "DM28" 64905 "VDS2" 64906 "J2012" 64912 "AETC" 64920 "AT1HI1" 64949 "DM23" 64950 "DM24" 64951 "DM25" 64952 "DM26" 64953 "TPRI" 64965 "ECUID" 64981 "EEC5" 65039 "LC" 65099 "TCFG2" 65109 "GFD" 65127 "CCC" 65131 "DI" 65136 "CVW" 65144 "TP1" 65145 "TP2" 65146 "TP3" 65195 "ETC6" 65196 "EBC4" 65199 "GFC" 65201 "EH" 65202 "GFI1" 65203 "LFI1" 65208 "GTFI" 65212 "CBI" 65214 "EEC4" 65216 "SERV" 65219 "ETC5" 65221 "ETC4" 65223 "ETC3" 65227 "DM02" 65228 "DM03" 65229 "DM04" 65230 "DM05" 65231 "DM06" 65234 "DM10" 65235 "DM11" 65236 "DM12" 65242 "SOFT" 65244 "IO" 65248 "VD" 65250 "TCFG" 65253 "HOURS" 65254 "TD" 65255 "VH" 65256 "VDS" 65257 "LFC1" 65258 "VW" 65259 "CI" 65260 "VI" 65261 "CCSS" 65284 "PB_DriversConsentOnPersonalData" 65340 "PB_HVESSCFG" 65376 "VehCfg" 65413 "PB_3CT" 65482 "PB_ID1" 65484 "PB_VNS" 65502 "Av2" 65520 "SCh" 65521 "DIS" 65524 "PB_IVA" ;
VAL_ 2565472330 PgnRqst_EA004A 37120 "VLSI1" 40448 "DM29" 41216 "DM33" 41728 "DM31" 41984 "DM30" 47360 "PLLT (Plan List Lifetime)" 47872 "PLD (Plan List Distance)" 49408 "DM21" 49664 "DM20" 49920 "DM22" 53504 "MaintBcIc" 54016 "DM19" 60928 "ACL" 61184 "STOD" 64341 "HVESP3HIST" 64342 "HVESP3CFG" 64343 "HVESP2HIST" 64344 "HVESP2CFG" 64345 "HVESP1HIST" 64346 "HVESP1CFG" 64529 "TGFI" 64579 "TCSI" 64582 "TSIS" 64583 "MTI" 64605 "HVESSCFG" 64606 "HVESSHIST" 64653 "PII" 64701 "A1SCRSI2" 64782 "AT1OGC2" 64784 "AT1IGC2" 64839 "TML" 64879 "EEC8" 64896 "DM28" 64905 "VDS2" 64906 "J2012" 64912 "AETC" 64920 "AT1HI1" 64949 "DM23" 64950 "DM24" 64951 "DM25" 64952 "DM26" 64953 "TPRI" 64965 "ECUID" 64981 "EEC5" 65039 "LC" 65099 "TCFG2" 65109 "GFD" 65127 "CCC" 65131 "DI" 65136 "CVW" 65144 "TP1" 65145 "TP2" 65146 "TP3" 65195 "ETC6" 65196 "EBC4" 65199 "GFC" 65201 "EH" 65202 "GFI1" 65203 "LFI1" 65208 "GTFI" 65212 "CBI" 65214 "EEC4" 65216 "SERV" 65219 "ETC5" 65221 "ETC4" 65223 "ETC3" 65227 "DM02" 65228 "DM03" 65229 "DM04" 65230 "DM05" 65231 "DM06" 65234 "DM10" 65235 "DM11" 65236 "DM12" 65242 "SOFT" 65244 "IO" 65248 "VD" 65250 "TCFG" 65253 "HOURS" 65254 "TD" 65255 "VH" 65256 "VDS" 65257 "LFC1" 65258 "VW" 65259 "CI" 65260 "VI" 65261 "CCSS" 65284 "PB_DriversConsentOnPersonalData" 65340 "PB_HVESSCFG" 65376 "VehCfg" 65413 "PB_3CT" 65482 "PB_ID1" 65484 "PB_VNS" 65502 "Av2" 65520 "SCh" 65521 "DIS" 65524 "PB_IVA" ;
VAL_ 2565473098 PgnRqst_EA034A 37120 "VLSI1" 40448 "DM29" 41216 "DM33" 41728 "DM31" 41984 "DM30" 47360 "PLLT (Plan List Lifetime)" 47872 "PLD (Plan List Distance)" 49408 "DM21" 49664 "DM20" 49920 "DM22" 53504 "MaintBcIc" 54016 "DM19" 60928 "ACL" 61184 "STOD" 64341 "HVESP3HIST" 64342 "HVESP3CFG" 64343 "HVESP2HIST" 64344 "HVESP2CFG" 64345 "HVESP1HIST" 64346 "HVESP1CFG" 64529 "TGFI" 64579 "TCSI" 64582 "TSIS" 64583 "MTI" 64605 "HVESSCFG" 64606 "HVESSHIST" 64653 "PII" 64701 "A1SCRSI2" 64782 "AT1OGC2" 64784 "AT1IGC2" 64839 "TML" 64879 "EEC8" 64896 "DM28" 64905 "VDS2" 64906 "J2012" 64912 "AETC" 64920 "AT1HI1" 64949 "DM23" 64950 "DM24" 64951 "DM25" 64952 "DM26" 64953 "TPRI" 64965 "ECUID" 64981 "EEC5" 65039 "LC" 65099 "TCFG2" 65109 "GFD" 65127 "CCC" 65131 "DI" 65136 "CVW" 65144 "TP1" 65145 "TP2" 65146 "TP3" 65195 "ETC6" 65196 "EBC4" 65199 "GFC" 65201 "EH" 65202 "GFI1" 65203 "LFI1" 65208 "GTFI" 65212 "CBI" 65214 "EEC4" 65216 "SERV" 65219 "ETC5" 65221 "ETC4" 65223 "ETC3" 65227 "DM02" 65228 "DM03" 65229 "DM04" 65230 "DM05" 65231 "DM06" 65234 "DM10" 65235 "DM11" 65236 "DM12" 65242 "SOFT" 65244 "IO" 65248 "VD" 65250 "TCFG" 65253 "HOURS" 65254 "TD" 65255 "VH" 65256 "VDS" 65257 "LFC1" 65258 "VW" 65259 "CI" 65260 "VI" 65261 "CCSS" 65284 "PB_DriversConsentOnPersonalData" 65340 "PB_HVESSCFG" 65376 "VehCfg" 65413 "PB_3CT" 65482 "PB_ID1" 65484 "PB_VNS" 65502 "Av2" 65520 "SCh" 65521 "DIS" 65524 "PB_IVA" ;
VAL_ 2565474122 PgnRqst_EA074A 37120 "VLSI1" 40448 "DM29" 41216 "DM33" 41728 "DM31" 41984 "DM30" 47360 "PLLT (Plan List Lifetime)" 47872 "PLD (Plan List Distance)" 49408 "DM21" 49664 "DM20" 49920 "DM22" 53504 "MaintBcIc" 54016 "DM19" 60928 "ACL" 61184 "STOD" 64341 "HVESP3HIST" 64342 "HVESP3CFG" 64343 "HVESP2HIST" 64344 "HVESP2CFG" 64345 "HVESP1HIST" 64346 "HVESP1CFG" 64529 "TGFI" 64579 "TCSI" 64582 "TSIS" 64583 "MTI" 64605 "HVESSCFG" 64606 "HVESSHIST" 64653 "PII" 64701 "A1SCRSI2" 64782 "AT1OGC2" 64784 "AT1IGC2" 64839 "TML" 64879 "EEC8" 64896 "DM28" 64905 "VDS2" 64906 "J2012" 64912 "AETC" 64920 "AT1HI1" 64949 "DM23" 64950 "DM24" 64951 "DM25" 64952 "DM26" 64953 "TPRI" 64965 "ECUID" 64981 "EEC5" 65039 "LC" 65099 "TCFG2" 65109 "GFD" 65127 "CCC" 65131 "DI" 65136 "CVW" 65144 "TP1" 65145 "TP2" 65146 "TP3" 65195 "ETC6" 65196 "EBC4" 65199 "GFC" 65201 "EH" 65202 "GFI1" 65203 "LFI1" 65208 "GTFI" 65212 "CBI" 65214 "EEC4" 65216 "SERV" 65219 "ETC5" 65221 "ETC4" 65223 "ETC3" 65227 "DM02" 65228 "DM03" 65229 "DM04" 65230 "DM05" 65231 "DM06" 65234 "DM10" 65235 "DM11" 65236 "DM12" 65242 "SOFT" 65244 "IO" 65248 "VD" 65250 "TCFG" 65253 "HOURS" 65254 "TD" 65255 "VH" 65256 "VDS" 65257 "LFC1" 65258 "VW" 65259 "CI" 65260 "VI" 65261 "CCSS" 65284 "PB_DriversConsentOnPersonalData" 65340 "PB_HVESSCFG" 65376 "VehCfg" 65413 "PB_3CT" 65482 "PB_ID1" 65484 "PB_VNS" 65502 "Av2" 65520 "SCh" 65521 "DIS" 65524 "PB_IVA" ;
VAL_ 2565478986 PgnRqst_EA1A4A 37120 "VLSI1" 40448 "DM29" 41216 "DM33" 41728 "DM31" 41984 "DM30" 47360 "PLLT (Plan List Lifetime)" 47872 "PLD (Plan List Distance)" 49408 "DM21" 49664 "DM20" 49920 "DM22" 53504 "MaintBcIc" 54016 "DM19" 60928 "ACL" 61184 "STOD" 64341 "HVESP3HIST" 64342 "HVESP3CFG" 64343 "HVESP2HIST" 64344 "HVESP2CFG" 64345 "HVESP1HIST" 64346 "HVESP1CFG" 64529 "TGFI" 64579 "TCSI" 64582 "TSIS" 64583 "MTI" 64605 "HVESSCFG" 64606 "HVESSHIST" 64653 "PII" 64701 "A1SCRSI2" 64782 "AT1OGC2" 64784 "AT1IGC2" 64839 "TML" 64879 "EEC8" 64896 "DM28" 64905 "VDS2" 64906 "J2012" 64912 "AETC" 64920 "AT1HI1" 64949 "DM23" 64950 "DM24" 64951 "DM25" 64952 "DM26" 64953 "TPRI" 64965 "ECUID" 64981 "EEC5" 65039 "LC" 65099 "TCFG2" 65109 "GFD" 65127 "CCC" 65131 "DI" 65136 "CVW" 65144 "TP1" 65145 "TP2" 65146 "TP3" 65195 "ETC6" 65196 "EBC4" 65199 "GFC" 65201 "EH" 65202 "GFI1" 65203 "LFI1" 65208 "GTFI" 65212 "CBI" 65214 "EEC4" 65216 "SERV" 65219 "ETC5" 65221 "ETC4" 65223 "ETC3" 65227 "DM02" 65228 "DM03" 65229 "DM04" 65230 "DM05" 65231 "DM06" 65234 "DM10" 65235 "DM11" 65236 "DM12" 65242 "SOFT" 65244 "IO" 65248 "VD" 65250 "TCFG" 65253 "HOURS" 65254 "TD" 65255 "VH" 65256 "VDS" 65257 "LFC1" 65258 "VW" 65259 "CI" 65260 "VI" 65261 "CCSS" 65284 "PB_DriversConsentOnPersonalData" 65340 "PB_HVESSCFG" 65376 "VehCfg" 65413 "PB_3CT" 65482 "PB_ID1" 65484 "PB_VNS" 65502 "Av2" 65520 "SCh" 65521 "DIS" 65524 "PB_IVA" ;
VAL_ 2565480778 PgnRqst_EA214A 37120 "VLSI1" 40448 "DM29" 41216 "DM33" 41728 "DM31" 41984 "DM30" 47360 "PLLT (Plan List Lifetime)" 47872 "PLD (Plan List Distance)" 49408 "DM21" 49664 "DM20" 49920 "DM22" 53504 "MaintBcIc" 54016 "DM19" 60928 "ACL" 61184 "STOD" 64341 "HVESP3HIST" 64342 "HVESP3CFG" 64343 "HVESP2HIST" 64344 "HVESP2CFG" 64345 "HVESP1HIST" 64346 "HVESP1CFG" 64529 "TGFI" 64579 "TCSI" 64582 "TSIS" 64583 "MTI" 64605 "HVESSCFG" 64606 "HVESSHIST" 64653 "PII" 64701 "A1SCRSI2" 64782 "AT1OGC2" 64784 "AT1IGC2" 64839 "TML" 64879 "EEC8" 64896 "DM28" 64905 "VDS2" 64906 "J2012" 64912 "AETC" 64920 "AT1HI1" 64949 "DM23" 64950 "DM24" 64951 "DM25" 64952 "DM26" 64953 "TPRI" 64965 "ECUID" 64981 "EEC5" 65039 "LC" 65099 "TCFG2" 65109 "GFD" 65127 "CCC" 65131 "DI" 65136 "CVW" 65144 "TP1" 65145 "TP2" 65146 "TP3" 65195 "ETC6" 65196 "EBC4" 65199 "GFC" 65201 "EH" 65202 "GFI1" 65203 "LFI1" 65208 "GTFI" 65212 "CBI" 65214 "EEC4" 65216 "SERV" 65219 "ETC5" 65221 "ETC4" 65223 "ETC3" 65227 "DM02" 65228 "DM03" 65229 "DM04" 65230 "DM05" 65231 "DM06" 65234 "DM10" 65235 "DM11" 65236 "DM12" 65242 "SOFT" 65244 "IO" 65248 "VD" 65250 "TCFG" 65253 "HOURS" 65254 "TD" 65255 "VH" 65256 "VDS" 65257 "LFC1" 65258 "VW" 65259 "CI" 65260 "VI" 65261 "CCSS" 65284 "PB_DriversConsentOnPersonalData" 65340 "PB_HVESSCFG" 65376 "VehCfg" 65413 "PB_3CT" 65482 "PB_ID1" 65484 "PB_VNS" 65502 "Av2" 65520 "SCh" 65521 "DIS" 65524 "PB_IVA" ;
VAL_ 2565481546 PgnRqst_EA244A 37120 "VLSI1" 40448 "DM29" 41216 "DM33" 41728 "DM31" 41984 "DM30" 47360 "PLLT (Plan List Lifetime)" 47872 "PLD (Plan List Distance)" 49408 "DM21" 49664 "DM20" 49920 "DM22" 53504 "MaintBcIc" 54016 "DM19" 60928 "ACL" 61184 "STOD" 64341 "HVESP3HIST" 64342 "HVESP3CFG" 64343 "HVESP2HIST" 64344 "HVESP2CFG" 64345 "HVESP1HIST" 64346 "HVESP1CFG" 64529 "TGFI" 64579 "TCSI" 64582 "TSIS" 64583 "MTI" 64605 "HVESSCFG" 64606 "HVESSHIST" 64653 "PII" 64701 "A1SCRSI2" 64782 "AT1OGC2" 64784 "AT1IGC2" 64839 "TML" 64879 "EEC8" 64896 "DM28" 64905 "VDS2" 64906 "J2012" 64912 "AETC" 64920 "AT1HI1" 64949 "DM23" 64950 "DM24" 64951 "DM25" 64952 "DM26" 64953 "TPRI" 64965 "ECUID" 64981 "EEC5" 65039 "LC" 65099 "TCFG2" 65109 "GFD" 65127 "CCC" 65131 "DI" 65136 "CVW" 65144 "TP1" 65145 "TP2" 65146 "TP3" 65195 "ETC6" 65196 "EBC4" 65199 "GFC" 65201 "EH" 65202 "GFI1" 65203 "LFI1" 65208 "GTFI" 65212 "CBI" 65214 "EEC4" 65216 "SERV" 65219 "ETC5" 65221 "ETC4" 65223 "ETC3" 65227 "DM02" 65228 "DM03" 65229 "DM04" 65230 "DM05" 65231 "DM06" 65234 "DM10" 65235 "DM11" 65236 "DM12" 65242 "SOFT" 65244 "IO" 65248 "VD" 65250 "TCFG" 65253 "HOURS" 65254 "TD" 65255 "VH" 65256 "VDS" 65257 "LFC1" 65258 "VW" 65259 "CI" 65260 "VI" 65261 "CCSS" 65284 "PB_DriversConsentOnPersonalData" 65340 "PB_HVESSCFG" 65376 "VehCfg" 65413 "PB_3CT" 65482 "PB_ID1" 65484 "PB_VNS" 65502 "Av2" 65520 "SCh" 65521 "DIS" 65524 "PB_IVA" ;
VAL_ 2565482314 PgnRqst_EA274A 37120 "VLSI1" 40448 "DM29" 41216 "DM33" 41728 "DM31" 41984 "DM30" 47360 "PLLT (Plan List Lifetime)" 47872 "PLD (Plan List Distance)" 49408 "DM21" 49664 "DM20" 49920 "DM22" 53504 "MaintBcIc" 54016 "DM19" 60928 "ACL" 61184 "STOD" 64341 "HVESP3HIST" 64342 "HVESP3CFG" 64343 "HVESP2HIST" 64344 "HVESP2CFG" 64345 "HVESP1HIST" 64346 "HVESP1CFG" 64529 "TGFI" 64579 "TCSI" 64582 "TSIS" 64583 "MTI" 64605 "HVESSCFG" 64606 "HVESSHIST" 64653 "PII" 64701 "A1SCRSI2" 64782 "AT1OGC2" 64784 "AT1IGC2" 64839 "TML" 64879 "EEC8" 64896 "DM28" 64905 "VDS2" 64906 "J2012" 64912 "AETC" 64920 "AT1HI1" 64949 "DM23" 64950 "DM24" 64951 "DM25" 64952 "DM26" 64953 "TPRI" 64965 "ECUID" 64981 "EEC5" 65039 "LC" 65099 "TCFG2" 65109 "GFD" 65127 "CCC" 65131 "DI" 65136 "CVW" 65144 "TP1" 65145 "TP2" 65146 "TP3" 65195 "ETC6" 65196 "EBC4" 65199 "GFC" 65201 "EH" 65202 "GFI1" 65203 "LFI1" 65208 "GTFI" 65212 "CBI" 65214 "EEC4" 65216 "SERV" 65219 "ETC5" 65221 "ETC4" 65223 "ETC3" 65227 "DM02" 65228 "DM03" 65229 "DM04" 65230 "DM05" 65231 "DM06" 65234 "DM10" 65235 "DM11" 65236 "DM12" 65242 "SOFT" 65244 "IO" 65248 "VD" 65250 "TCFG" 65253 "HOURS" 65254 "TD" 65255 "VH" 65256 "VDS" 65257 "LFC1" 65258 "VW" 65259 "CI" 65260 "VI" 65261 "CCSS" 65284 "PB_DriversConsentOnPersonalData" 65340 "PB_HVESSCFG" 65376 "VehCfg" 65413 "PB_3CT" 65482 "PB_ID1" 65484 "PB_VNS" 65502 "Av2" 65520 "SCh" 65521 "DIS" 65524 "PB_IVA" ;
VAL_ 2565485386 PgnRqst_EA334A 37120 "VLSI1" 40448 "DM29" 41216 "DM33" 41728 "DM31" 41984 "DM30" 47360 "PLLT (Plan List Lifetime)" 47872 "PLD (Plan List Distance)" 49408 "DM21" 49664 "DM20" 49920 "DM22" 53504 "MaintBcIc" 54016 "DM19" 60928 "ACL" 61184 "STOD" 64341 "HVESP3HIST" 64342 "HVESP3CFG" 64343 "HVESP2HIST" 64344 "HVESP2CFG" 64345 "HVESP1HIST" 64346 "HVESP1CFG" 64529 "TGFI" 64579 "TCSI" 64582 "TSIS" 64583 "MTI" 64605 "HVESSCFG" 64606 "HVESSHIST" 64653 "PII" 64701 "A1SCRSI2" 64782 "AT1OGC2" 64784 "AT1IGC2" 64839 "TML" 64879 "EEC8" 64896 "DM28" 64905 "VDS2" 64906 "J2012" 64912 "AETC" 64920 "AT1HI1" 64949 "DM23" 64950 "DM24" 64951 "DM25" 64952 "DM26" 64953 "TPRI" 64965 "ECUID" 64981 "EEC5" 65039 "LC" 65099 "TCFG2" 65109 "GFD" 65127 "CCC" 65131 "DI" 65136 "CVW" 65144 "TP1" 65145 "TP2" 65146 "TP3" 65195 "ETC6" 65196 "EBC4" 65199 "GFC" 65201 "EH" 65202 "GFI1" 65203 "LFI1" 65208 "GTFI" 65212 "CBI" 65214 "EEC4" 65216 "SERV" 65219 "ETC5" 65221 "ETC4" 65223 "ETC3" 65227 "DM02" 65228 "DM03" 65229 "DM04" 65230 "DM05" 65231 "DM06" 65234 "DM10" 65235 "DM11" 65236 "DM12" 65242 "SOFT" 65244 "IO" 65248 "VD" 65250 "TCFG" 65253 "HOURS" 65254 "TD" 65255 "VH" 65256 "VDS" 65257 "LFC1" 65258 "VW" 65259 "CI" 65260 "VI" 65261 "CCSS" 65284 "PB_DriversConsentOnPersonalData" 65340 "PB_HVESSCFG" 65376 "VehCfg" 65413 "PB_3CT" 65482 "PB_ID1" 65484 "PB_VNS" 65502 "Av2" 65520 "SCh" 65521 "DIS" 65524 "PB_IVA" ;
VAL_ 2565488970 PgnRqst_EA414A 37120 "VLSI1" 40448 "DM29" 41216 "DM33" 41728 "DM31" 41984 "DM30" 47360 "PLLT (Plan List Lifetime)" 47872 "PLD (Plan List Distance)" 49408 "DM21" 49664 "DM20" 49920 "DM22" 53504 "MaintBcIc" 54016 "DM19" 60928 "ACL" 61184 "STOD" 64341 "HVESP3HIST" 64342 "HVESP3CFG" 64343 "HVESP2HIST" 64344 "HVESP2CFG" 64345 "HVESP1HIST" 64346 "HVESP1CFG" 64529 "TGFI" 64579 "TCSI" 64582 "TSIS" 64583 "MTI" 64605 "HVESSCFG" 64606 "HVESSHIST" 64653 "PII" 64701 "A1SCRSI2" 64782 "AT1OGC2" 64784 "AT1IGC2" 64839 "TML" 64879 "EEC8" 64896 "DM28" 64905 "VDS2" 64906 "J2012" 64912 "AETC" 64920 "AT1HI1" 64949 "DM23" 64950 "DM24" 64951 "DM25" 64952 "DM26" 64953 "TPRI" 64965 "ECUID" 64981 "EEC5" 65039 "LC" 65099 "TCFG2" 65109 "GFD" 65127 "CCC" 65131 "DI" 65136 "CVW" 65144 "TP1" 65145 "TP2" 65146 "TP3" 65195 "ETC6" 65196 "EBC4" 65199 "GFC" 65201 "EH" 65202 "GFI1" 65203 "LFI1" 65208 "GTFI" 65212 "CBI" 65214 "EEC4" 65216 "SERV" 65219 "ETC5" 65221 "ETC4" 65223 "ETC3" 65227 "DM02" 65228 "DM03" 65229 "DM04" 65230 "DM05" 65231 "DM06" 65234 "DM10" 65235 "DM11" 65236 "DM12" 65242 "SOFT" 65244 "IO" 65248 "VD" 65250 "TCFG" 65253 "HOURS" 65254 "TD" 65255 "VH" 65256 "VDS" 65257 "LFC1" 65258 "VW" 65259 "CI" 65260 "VI" 65261 "CCSS" 65284 "PB_DriversConsentOnPersonalData" 65340 "PB_HVESSCFG" 65376 "VehCfg" 65413 "PB_3CT" 65482 "PB_ID1" 65484 "PB_VNS" 65502 "Av2" 65520 "SCh" 65521 "DIS" 65524 "PB_IVA" ;
VAL_ 2565491018 PgnRqst_EA494A 37120 "VLSI1" 40448 "DM29" 41216 "DM33" 41728 "DM31" 41984 "DM30" 47360 "PLLT (Plan List Lifetime)" 47872 "PLD (Plan List Distance)" 49408 "DM21" 49664 "DM20" 49920 "DM22" 53504 "MaintBcIc" 54016 "DM19" 60928 "ACL" 61184 "STOD" 64341 "HVESP3HIST" 64342 "HVESP3CFG" 64343 "HVESP2HIST" 64344 "HVESP2CFG" 64345 "HVESP1HIST" 64346 "HVESP1CFG" 64529 "TGFI" 64579 "TCSI" 64582 "TSIS" 64583 "MTI" 64605 "HVESSCFG" 64606 "HVESSHIST" 64653 "PII" 64701 "A1SCRSI2" 64782 "AT1OGC2" 64784 "AT1IGC2" 64839 "TML" 64879 "EEC8" 64896 "DM28" 64905 "VDS2" 64906 "J2012" 64912 "AETC" 64920 "AT1HI1" 64949 "DM23" 64950 "DM24" 64951 "DM25" 64952 "DM26" 64953 "TPRI" 64965 "ECUID" 64981 "EEC5" 65039 "LC" 65099 "TCFG2" 65109 "GFD" 65127 "CCC" 65131 "DI" 65136 "CVW" 65144 "TP1" 65145 "TP2" 65146 "TP3" 65195 "ETC6" 65196 "EBC4" 65199 "GFC" 65201 "EH" 65202 "GFI1" 65203 "LFI1" 65208 "GTFI" 65212 "CBI" 65214 "EEC4" 65216 "SERV" 65219 "ETC5" 65221 "ETC4" 65223 "ETC3" 65227 "DM02" 65228 "DM03" 65229 "DM04" 65230 "DM05" 65231 "DM06" 65234 "DM10" 65235 "DM11" 65236 "DM12" 65242 "SOFT" 65244 "IO" 65248 "VD" 65250 "TCFG" 65253 "HOURS" 65254 "TD" 65255 "VH" 65256 "VDS" 65257 "LFC1" 65258 "VW" 65259 "CI" 65260 "VI" 65261 "CCSS" 65284 "PB_DriversConsentOnPersonalData" 65340 "PB_HVESSCFG" 65376 "VehCfg" 65413 "PB_3CT" 65482 "PB_ID1" 65484 "PB_VNS" 65502 "Av2" 65520 "SCh" 65521 "DIS" 65524 "PB_IVA" ;
VAL_ 2565504074 PgnRqst_EA7C4A 37120 "VLSI1" 40448 "DM29" 41216 "DM33" 41728 "DM31" 41984 "DM30" 47360 "PLLT (Plan List Lifetime)" 47872 "PLD (Plan List Distance)" 49408 "DM21" 49664 "DM20" 49920 "DM22" 53504 "MaintBcIc" 54016 "DM19" 60928 "ACL" 61184 "STOD" 64341 "HVESP3HIST" 64342 "HVESP3CFG" 64343 "HVESP2HIST" 64344 "HVESP2CFG" 64345 "HVESP1HIST" 64346 "HVESP1CFG" 64529 "TGFI" 64579 "TCSI" 64582 "TSIS" 64583 "MTI" 64605 "HVESSCFG" 64606 "HVESSHIST" 64653 "PII" 64701 "A1SCRSI2" 64782 "AT1OGC2" 64784 "AT1IGC2" 64839 "TML" 64879 "EEC8" 64896 "DM28" 64905 "VDS2" 64906 "J2012" 64912 "AETC" 64920 "AT1HI1" 64949 "DM23" 64950 "DM24" 64951 "DM25" 64952 "DM26" 64953 "TPRI" 64965 "ECUID" 64981 "EEC5" 65039 "LC" 65099 "TCFG2" 65109 "GFD" 65127 "CCC" 65131 "DI" 65136 "CVW" 65144 "TP1" 65145 "TP2" 65146 "TP3" 65195 "ETC6" 65196 "EBC4" 65199 "GFC" 65201 "EH" 65202 "GFI1" 65203 "LFI1" 65208 "GTFI" 65212 "CBI" 65214 "EEC4" 65216 "SERV" 65219 "ETC5" 65221 "ETC4" 65223 "ETC3" 65227 "DM02" 65228 "DM03" 65229 "DM04" 65230 "DM05" 65231 "DM06" 65234 "DM10" 65235 "DM11" 65236 "DM12" 65242 "SOFT" 65244 "IO" 65248 "VD" 65250 "TCFG" 65253 "HOURS" 65254 "TD" 65255 "VH" 65256 "VDS" 65257 "LFC1" 65258 "VW" 65259 "CI" 65260 "VI" 65261 "CCSS" 65284 "PB_DriversConsentOnPersonalData" 65340 "PB_HVESSCFG" 65376 "VehCfg" 65413 "PB_3CT" 65482 "PB_ID1" 65484 "PB_VNS" 65502 "Av2" 65520 "SCh" 65521 "DIS" 65524 "PB_IVA" ;
VAL_ 2565506634 PgnRqst_EA864A 37120 "VLSI1" 40448 "DM29" 41216 "DM33" 41728 "DM31" 41984 "DM30" 47360 "PLLT (Plan List Lifetime)" 47872 "PLD (Plan List Distance)" 49408 "DM21" 49664 "DM20" 49920 "DM22" 53504 "MaintBcIc" 54016 "DM19" 60928 "ACL" 61184 "STOD" 64341 "HVESP3HIST" 64342 "HVESP3CFG" 64343 "HVESP2HIST" 64344 "HVESP2CFG" 64345 "HVESP1HIST" 64346 "HVESP1CFG" 64529 "TGFI" 64579 "TCSI" 64582 "TSIS" 64583 "MTI" 64605 "HVESSCFG" 64606 "HVESSHIST" 64653 "PII" 64701 "A1SCRSI2" 64782 "AT1OGC2" 64784 "AT1IGC2" 64839 "TML" 64879 "EEC8" 64896 "DM28" 64905 "VDS2" 64906 "J2012" 64912 "AETC" 64920 "AT1HI1" 64949 "DM23" 64950 "DM24" 64951 "DM25" 64952 "DM26" 64953 "TPRI" 64965 "ECUID" 64981 "EEC5" 65039 "LC" 65099 "TCFG2" 65109 "GFD" 65127 "CCC" 65131 "DI" 65136 "CVW" 65144 "TP1" 65145 "TP2" 65146 "TP3" 65195 "ETC6" 65196 "EBC4" 65199 "GFC" 65201 "EH" 65202 "GFI1" 65203 "LFI1" 65208 "GTFI" 65212 "CBI" 65214 "EEC4" 65216 "SERV" 65219 "ETC5" 65221 "ETC4" 65223 "ETC3" 65227 "DM02" 65228 "DM03" 65229 "DM04" 65230 "DM05" 65231 "DM06" 65234 "DM10" 65235 "DM11" 65236 "DM12" 65242 "SOFT" 65244 "IO" 65248 "VD" 65250 "TCFG" 65253 "HOURS" 65254 "TD" 65255 "VH" 65256 "VDS" 65257 "LFC1" 65258 "VW" 65259 "CI" 65260 "VI" 65261 "CCSS" 65284 "PB_DriversConsentOnPersonalData" 65340 "PB_HVESSCFG" 65376 "VehCfg" 65413 "PB_3CT" 65482 "PB_ID1" 65484 "PB_VNS" 65502 "Av2" 65520 "SCh" 65521 "DIS" 65524 "PB_IVA" ;
VAL_ 2565506890 PgnRqst_EA874A 37120 "VLSI1" 40448 "DM29" 41216 "DM33" 41728 "DM31" 41984 "DM30" 47360 "PLLT (Plan List Lifetime)" 47872 "PLD (Plan List Distance)" 49408 "DM21" 49664 "DM20" 49920 "DM22" 53504 "MaintBcIc" 54016 "DM19" 60928 "ACL" 61184 "STOD" 64341 "HVESP3HIST" 64342 "HVESP3CFG" 64343 "HVESP2HIST" 64344 "HVESP2CFG" 64345 "HVESP1HIST" 64346 "HVESP1CFG" 64529 "TGFI" 64579 "TCSI" 64582 "TSIS" 64583 "MTI" 64605 "HVESSCFG" 64606 "HVESSHIST" 64653 "PII" 64701 "A1SCRSI2" 64782 "AT1OGC2" 64784 "AT1IGC2" 64839 "TML" 64879 "EEC8" 64896 "DM28" 64905 "VDS2" 64906 "J2012" 64912 "AETC" 64920 "AT1HI1" 64949 "DM23" 64950 "DM24" 64951 "DM25" 64952 "DM26" 64953 "TPRI" 64965 "ECUID" 64981 "EEC5" 65039 "LC" 65099 "TCFG2" 65109 "GFD" 65127 "CCC" 65131 "DI" 65136 "CVW" 65144 "TP1" 65145 "TP2" 65146 "TP3" 65195 "ETC6" 65196 "EBC4" 65199 "GFC" 65201 "EH" 65202 "GFI1" 65203 "LFI1" 65208 "GTFI" 65212 "CBI" 65214 "EEC4" 65216 "SERV" 65219 "ETC5" 65221 "ETC4" 65223 "ETC3" 65227 "DM02" 65228 "DM03" 65229 "DM04" 65230 "DM05" 65231 "DM06" 65234 "DM10" 65235 "DM11" 65236 "DM12" 65242 "SOFT" 65244 "IO" 65248 "VD" 65250 "TCFG" 65253 "HOURS" 65254 "TD" 65255 "VH" 65256 "VDS" 65257 "LFC1" 65258 "VW" 65259 "CI" 65260 "VI" 65261 "CCSS" 65284 "PB_DriversConsentOnPersonalData" 65340 "PB_HVESSCFG" 65376 "VehCfg" 65413 "PB_3CT" 65482 "PB_ID1" 65484 "PB_VNS" 65502 "Av2" 65520 "SCh" 65521 "DIS" 65524 "PB_IVA" ;
VAL_ 2565533258 PgnRqst_EAEE4A 37120 "VLSI1" 40448 "DM29" 41216 "DM33" 41728 "DM31" 41984 "DM30" 47360 "PLLT (Plan List Lifetime)" 47872 "PLD (Plan List Distance)" 49408 "DM21" 49664 "DM20" 49920 "DM22" 53504 "MaintBcIc" 54016 "DM19" 60928 "ACL" 61184 "STOD" 64341 "HVESP3HIST" 64342 "HVESP3CFG" 64343 "HVESP2HIST" 64344 "HVESP2CFG" 64345 "HVESP1HIST" 64346 "HVESP1CFG" 64529 "TGFI" 64579 "TCSI" 64582 "TSIS" 64583 "MTI" 64605 "HVESSCFG" 64606 "HVESSHIST" 64653 "PII" 64701 "A1SCRSI2" 64782 "AT1OGC2" 64784 "AT1IGC2" 64839 "TML" 64879 "EEC8" 64896 "DM28" 64905 "VDS2" 64906 "J2012" 64912 "AETC" 64920 "AT1HI1" 64949 "DM23" 64950 "DM24" 64951 "DM25" 64952 "DM26" 64953 "TPRI" 64965 "ECUID" 64981 "EEC5" 65039 "LC" 65099 "TCFG2" 65109 "GFD" 65127 "CCC" 65131 "DI" 65136 "CVW" 65144 "TP1" 65145 "TP2" 65146 "TP3" 65195 "ETC6" 65196 "EBC4" 65199 "GFC" 65201 "EH" 65202 "GFI1" 65203 "LFI1" 65208 "GTFI" 65212 "CBI" 65214 "EEC4" 65216 "SERV" 65219 "ETC5" 65221 "ETC4" 65223 "ETC3" 65227 "DM02" 65228 "DM03" 65229 "DM04" 65230 "DM05" 65231 "DM06" 65234 "DM10" 65235 "DM11" 65236 "DM12" 65242 "SOFT" 65244 "IO" 65248 "VD" 65250 "TCFG" 65253 "HOURS" 65254 "TD" 65255 "VH" 65256 "VDS" 65257 "LFC1" 65258 "VW" 65259 "CI" 65260 "VI" 65261 "CCSS" 65284 "PB_DriversConsentOnPersonalData" 65340 "PB_HVESSCFG" 65376 "VehCfg" 65413 "PB_3CT" 65482 "PB_ID1" 65484 "PB_VNS" 65502 "Av2" 65520 "SCh" 65521 "DIS" 65524 "PB_IVA" ;
VAL_ 2565533514 PgnRqst_EAEF4A 37120 "VLSI1" 40448 "DM29" 41216 "DM33" 41728 "DM31" 41984 "DM30" 47360 "PLLT (Plan List Lifetime)" 47872 "PLD (Plan List Distance)" 49408 "DM21" 49664 "DM20" 49920 "DM22" 53504 "MaintBcIc" 54016 "DM19" 60928 "ACL" 61184 "STOD" 64341 "HVESP3HIST" 64342 "HVESP3CFG" 64343 "HVESP2HIST" 64344 "HVESP2CFG" 64345 "HVESP1HIST" 64346 "HVESP1CFG" 64529 "TGFI" 64579 "TCSI" 64582 "TSIS" 64583 "MTI" 64605 "HVESSCFG" 64606 "HVESSHIST" 64653 "PII" 64701 "A1SCRSI2" 64782 "AT1OGC2" 64784 "AT1IGC2" 64839 "TML" 64879 "EEC8" 64896 "DM28" 64905 "VDS2" 64906 "J2012" 64912 "AETC" 64920 "AT1HI1" 64949 "DM23" 64950 "DM24" 64951 "DM25" 64952 "DM26" 64953 "TPRI" 64965 "ECUID" 64981 "EEC5" 65039 "LC" 65099 "TCFG2" 65109 "GFD" 65127 "CCC" 65131 "DI" 65136 "CVW" 65144 "TP1" 65145 "TP2" 65146 "TP3" 65195 "ETC6" 65196 "EBC4" 65199 "GFC" 65201 "EH" 65202 "GFI1" 65203 "LFI1" 65208 "GTFI" 65212 "CBI" 65214 "EEC4" 65216 "SERV" 65219 "ETC5" 65221 "ETC4" 65223 "ETC3" 65227 "DM02" 65228 "DM03" 65229 "DM04" 65230 "DM05" 65231 "DM06" 65234 "DM10" 65235 "DM11" 65236 "DM12" 65242 "SOFT" 65244 "IO" 65248 "VD" 65250 "TCFG" 65253 "HOURS" 65254 "TD" 65255 "VH" 65256 "VDS" 65257 "LFC1" 65258 "VW" 65259 "CI" 65260 "VI" 65261 "CCSS" 65284 "PB_DriversConsentOnPersonalData" 65340 "PB_HVESSCFG" 65376 "VehCfg" 65413 "PB_3CT" 65482 "PB_ID1" 65484 "PB_VNS" 65502 "Av2" 65520 "SCh" 65521 "DIS" 65524 "PB_IVA" ;
VAL_ 2565534282 PgnRqst_EAF24A 37120 "VLSI1" 40448 "DM29" 41216 "DM33" 41728 "DM31" 41984 "DM30" 47360 "PLLT (Plan List Lifetime)" 47872 "PLD (Plan List Distance)" 49408 "DM21" 49664 "DM20" 49920 "DM22" 53504 "MaintBcIc" 54016 "DM19" 60928 "ACL" 61184 "STOD" 64341 "HVESP3HIST" 64342 "HVESP3CFG" 64343 "HVESP2HIST" 64344 "HVESP2CFG" 64345 "HVESP1HIST" 64346 "HVESP1CFG" 64529 "TGFI" 64579 "TCSI" 64582 "TSIS" 64583 "MTI" 64605 "HVESSCFG" 64606 "HVESSHIST" 64653 "PII" 64701 "A1SCRSI2" 64782 "AT1OGC2" 64784 "AT1IGC2" 64839 "TML" 64879 "EEC8" 64896 "DM28" 64905 "VDS2" 64906 "J2012" 64912 "AETC" 64920 "AT1HI1" 64949 "DM23" 64950 "DM24" 64951 "DM25" 64952 "DM26" 64953 "TPRI" 64965 "ECUID" 64981 "EEC5" 65039 "LC" 65099 "TCFG2" 65109 "GFD" 65127 "CCC" 65131 "DI" 65136 "CVW" 65144 "TP1" 65145 "TP2" 65146 "TP3" 65195 "ETC6" 65196 "EBC4" 65199 "GFC" 65201 "EH" 65202 "GFI1" 65203 "LFI1" 65208 "GTFI" 65212 "CBI" 65214 "EEC4" 65216 "SERV" 65219 "ETC5" 65221 "ETC4" 65223 "ETC3" 65227 "DM02" 65228 "DM03" 65229 "DM04" 65230 "DM05" 65231 "DM06" 65234 "DM10" 65235 "DM11" 65236 "DM12" 65242 "SOFT" 65244 "IO" 65248 "VD" 65250 "TCFG" 65253 "HOURS" 65254 "TD" 65255 "VH" 65256 "VDS" 65257 "LFC1" 65258 "VW" 65259 "CI" 65260 "VI" 65261 "CCSS" 65284 "PB_DriversConsentOnPersonalData" 65340 "PB_HVESSCFG" 65376 "VehCfg" 65413 "PB_3CT" 65482 "PB_ID1" 65484 "PB_VNS" 65502 "Av2" 65520 "SCh" 65521 "DIS" 65524 "PB_IVA" ;
VAL_ 2565534538 PgnRqst_EAF34A 37120 "VLSI1" 40448 "DM29" 41216 "DM33" 41728 "DM31" 41984 "DM30" 47360 "PLLT (Plan List Lifetime)" 47872 "PLD (Plan List Distance)" 49408 "DM21" 49664 "DM20" 49920 "DM22" 53504 "MaintBcIc" 54016 "DM19" 60928 "ACL" 61184 "STOD" 64341 "HVESP3HIST" 64342 "HVESP3CFG" 64343 "HVESP2HIST" 64344 "HVESP2CFG" 64345 "HVESP1HIST" 64346 "HVESP1CFG" 64529 "TGFI" 64579 "TCSI" 64582 "TSIS" 64583 "MTI" 64605 "HVESSCFG" 64606 "HVESSHIST" 64653 "PII" 64701 "A1SCRSI2" 64782 "AT1OGC2" 64784 "AT1IGC2" 64839 "TML" 64879 "EEC8" 64896 "DM28" 64905 "VDS2" 64906 "J2012" 64912 "AETC" 64920 "AT1HI1" 64949 "DM23" 64950 "DM24" 64951 "DM25" 64952 "DM26" 64953 "TPRI" 64965 "ECUID" 64981 "EEC5" 65039 "LC" 65099 "TCFG2" 65109 "GFD" 65127 "CCC" 65131 "DI" 65136 "CVW" 65144 "TP1" 65145 "TP2" 65146 "TP3" 65195 "ETC6" 65196 "EBC4" 65199 "GFC" 65201 "EH" 65202 "GFI1" 65203 "LFI1" 65208 "GTFI" 65212 "CBI" 65214 "EEC4" 65216 "SERV" 65219 "ETC5" 65221 "ETC4" 65223 "ETC3" 65227 "DM02" 65228 "DM03" 65229 "DM04" 65230 "DM05" 65231 "DM06" 65234 "DM10" 65235 "DM11" 65236 "DM12" 65242 "SOFT" 65244 "IO" 65248 "VD" 65250 "TCFG" 65253 "HOURS" 65254 "TD" 65255 "VH" 65256 "VDS" 65257 "LFC1" 65258 "VW" 65259 "CI" 65260 "VI" 65261 "CCSS" 65284 "PB_DriversConsentOnPersonalData" 65340 "PB_HVESSCFG" 65376 "VehCfg" 65413 "PB_3CT" 65482 "PB_ID1" 65484 "PB_VNS" 65502 "Av2" 65520 "SCh" 65521 "DIS" 65524 "PB_IVA" ;
VAL_ 2565534794 PgnRqst_EAF44A 37120 "VLSI1" 40448 "DM29" 41216 "DM33" 41728 "DM31" 41984 "DM30" 47360 "PLLT (Plan List Lifetime)" 47872 "PLD (Plan List Distance)" 49408 "DM21" 49664 "DM20" 49920 "DM22" 53504 "MaintBcIc" 54016 "DM19" 60928 "ACL" 61184 "STOD" 64341 "HVESP3HIST" 64342 "HVESP3CFG" 64343 "HVESP2HIST" 64344 "HVESP2CFG" 64345 "HVESP1HIST" 64346 "HVESP1CFG" 64529 "TGFI" 64579 "TCSI" 64582 "TSIS" 64583 "MTI" 64605 "HVESSCFG" 64606 "HVESSHIST" 64653 "PII" 64701 "A1SCRSI2" 64782 "AT1OGC2" 64784 "AT1IGC2" 64839 "TML" 64879 "EEC8" 64896 "DM28" 64905 "VDS2" 64906 "J2012" 64912 "AETC" 64920 "AT1HI1" 64949 "DM23" 64950 "DM24" 64951 "DM25" 64952 "DM26" 64953 "TPRI" 64965 "ECUID" 64981 "EEC5" 65039 "LC" 65099 "TCFG2" 65109 "GFD" 65127 "CCC" 65131 "DI" 65136 "CVW" 65144 "TP1" 65145 "TP2" 65146 "TP3" 65195 "ETC6" 65196 "EBC4" 65199 "GFC" 65201 "EH" 65202 "GFI1" 65203 "LFI1" 65208 "GTFI" 65212 "CBI" 65214 "EEC4" 65216 "SERV" 65219 "ETC5" 65221 "ETC4" 65223 "ETC3" 65227 "DM02" 65228 "DM03" 65229 "DM04" 65230 "DM05" 65231 "DM06" 65234 "DM10" 65235 "DM11" 65236 "DM12" 65242 "SOFT" 65244 "IO" 65248 "VD" 65250 "TCFG" 65253 "HOURS" 65254 "TD" 65255 "VH" 65256 "VDS" 65257 "LFC1" 65258 "VW" 65259 "CI" 65260 "VI" 65261 "CCSS" 65284 "PB_DriversConsentOnPersonalData" 65340 "PB_HVESSCFG" 65376 "VehCfg" 65413 "PB_3CT" 65482 "PB_ID1" 65484 "PB_VNS" 65502 "Av2" 65520 "SCh" 65521 "DIS" 65524 "PB_IVA" ;
VAL_ 2565535050 PgnRqst_EAF54A 37120 "VLSI1" 40448 "DM29" 41216 "DM33" 41728 "DM31" 41984 "DM30" 47360 "PLLT (Plan List Lifetime)" 47872 "PLD (Plan List Distance)" 49408 "DM21" 49664 "DM20" 49920 "DM22" 53504 "MaintBcIc" 54016 "DM19" 60928 "ACL" 61184 "STOD" 64341 "HVESP3HIST" 64342 "HVESP3CFG" 64343 "HVESP2HIST" 64344 "HVESP2CFG" 64345 "HVESP1HIST" 64346 "HVESP1CFG" 64529 "TGFI" 64579 "TCSI" 64582 "TSIS" 64583 "MTI" 64605 "HVESSCFG" 64606 "HVESSHIST" 64653 "PII" 64701 "A1SCRSI2" 64782 "AT1OGC2" 64784 "AT1IGC2" 64839 "TML" 64879 "EEC8" 64896 "DM28" 64905 "VDS2" 64906 "J2012" 64912 "AETC" 64920 "AT1HI1" 64949 "DM23" 64950 "DM24" 64951 "DM25" 64952 "DM26" 64953 "TPRI" 64965 "ECUID" 64981 "EEC5" 65039 "LC" 65099 "TCFG2" 65109 "GFD" 65127 "CCC" 65131 "DI" 65136 "CVW" 65144 "TP1" 65145 "TP2" 65146 "TP3" 65195 "ETC6" 65196 "EBC4" 65199 "GFC" 65201 "EH" 65202 "GFI1" 65203 "LFI1" 65208 "GTFI" 65212 "CBI" 65214 "EEC4" 65216 "SERV" 65219 "ETC5" 65221 "ETC4" 65223 "ETC3" 65227 "DM02" 65228 "DM03" 65229 "DM04" 65230 "DM05" 65231 "DM06" 65234 "DM10" 65235 "DM11" 65236 "DM12" 65242 "SOFT" 65244 "IO" 65248 "VD" 65250 "TCFG" 65253 "HOURS" 65254 "TD" 65255 "VH" 65256 "VDS" 65257 "LFC1" 65258 "VW" 65259 "CI" 65260 "VI" 65261 "CCSS" 65284 "PB_DriversConsentOnPersonalData" 65340 "PB_HVESSCFG" 65376 "VehCfg" 65413 "PB_3CT" 65482 "PB_ID1" 65484 "PB_VNS" 65502 "Av2" 65520 "SCh" 65521 "DIS" 65524 "PB_IVA" ;
VAL_ 2565535306 PgnRqst_EAF64A 37120 "VLSI1" 40448 "DM29" 41216 "DM33" 41728 "DM31" 41984 "DM30" 47360 "PLLT (Plan List Lifetime)" 47872 "PLD (Plan List Distance)" 49408 "DM21" 49664 "DM20" 49920 "DM22" 53504 "MaintBcIc" 54016 "DM19" 60928 "ACL" 61184 "STOD" 64341 "HVESP3HIST" 64342 "HVESP3CFG" 64343 "HVESP2HIST" 64344 "HVESP2CFG" 64345 "HVESP1HIST" 64346 "HVESP1CFG" 64529 "TGFI" 64579 "TCSI" 64582 "TSIS" 64583 "MTI" 64605 "HVESSCFG" 64606 "HVESSHIST" 64653 "PII" 64701 "A1SCRSI2" 64782 "AT1OGC2" 64784 "AT1IGC2" 64839 "TML" 64879 "EEC8" 64896 "DM28" 64905 "VDS2" 64906 "J2012" 64912 "AETC" 64920 "AT1HI1" 64949 "DM23" 64950 "DM24" 64951 "DM25" 64952 "DM26" 64953 "TPRI" 64965 "ECUID" 64981 "EEC5" 65039 "LC" 65099 "TCFG2" 65109 "GFD" 65127 "CCC" 65131 "DI" 65136 "CVW" 65144 "TP1" 65145 "TP2" 65146 "TP3" 65195 "ETC6" 65196 "EBC4" 65199 "GFC" 65201 "EH" 65202 "GFI1" 65203 "LFI1" 65208 "GTFI" 65212 "CBI" 65214 "EEC4" 65216 "SERV" 65219 "ETC5" 65221 "ETC4" 65223 "ETC3" 65227 "DM02" 65228 "DM03" 65229 "DM04" 65230 "DM05" 65231 "DM06" 65234 "DM10" 65235 "DM11" 65236 "DM12" 65242 "SOFT" 65244 "IO" 65248 "VD" 65250 "TCFG" 65253 "HOURS" 65254 "TD" 65255 "VH" 65256 "VDS" 65257 "LFC1" 65258 "VW" 65259 "CI" 65260 "VI" 65261 "CCSS" 65284 "PB_DriversConsentOnPersonalData" 65340 "PB_HVESSCFG" 65376 "VehCfg" 65413 "PB_3CT" 65482 "PB_ID1" 65484 "PB_VNS" 65502 "Av2" 65520 "SCh" 65521 "DIS" 65524 "PB_IVA" ;
VAL_ 2566832128 ServCompId 0 "Serv. check for entire vehicle" 1 "Brake lining FA Left" 2 "Brake lining FA Right" 3 "Brake lining RA Left" 4 "Brake lining RA Right" 5 "Clutch lining" 6 "Reserved" 7 "Reserved" 8 "Reserved" 9 "Reserved" 10 "Reserved" 11 "Brake lining RA2 Left" 12 "Brake lining RA2 Right" 13 "Brake lining RA3 Left" 14 "Brake lining RA3 Right" 15 "Brake lining: general" 16 "Reg. gen. check for entire veh." 17 "Brake system special check" 18 "In-between check" 19 "Check trip recorder" 20 "Check exhaust gas" 21 "Check vehicle speed limiter" 22 "Reserved" 23 "Reserved" 24 "Reserved" 25 "Reserved" 26 "Reserved" 27 "Reserved" 28 "Reserved" 29 "Reserved" 30 "Engine coolant change" 31 "Engine coolant filter change" 32 "Engine oil-engine #1" 33 "Engine oil-engine #2" 34 "Reserved" 35 "Steering oil" 36 "Reserved" 37 "Transmission #1 oil" 38 "Transmission #2 oil" 39 "Transm. oil filter � Transm #1" 40 "Intermediate transm.n oil" 41 "Reserved" 42 "Front axle oil" 43 "Rear axle oil" 48 "Tires" 49 "Engine air filter" 50 "Engine oil filter" 51 "Engine Fuel Filter" 52 "Reserved" 53 "Reserved" 54 "Reserved" 55 "Reserved" 56 "Reserved" 57 "Reserved" 58 "Reserved" 59 "Reserved" 60 "Reserved" 61 "Tachograph" 62 "Driver card #1" 63 "Driver card #2" 64 "Reserved" 65 "Reserved" 66 "Reserved" 67 "Reserved" 68 "Reserved" 69 "Reserved" 70 "Reserved" 71 "DPF 1 Ash" 72 "DPF 2 Ash" 73 "AT DEF Doser Cooldown Intr. Cnt" 74 "AT DEF Doser Purge Intr. Cnt" 75 "Reserved" 239 "Reserved" 240 "Manufacturer specific" 241 "Manufacturer specific" 242 "Manufacturer specific" 243 "Manufacturer specific" 244 "Manufacturer specific" 245 "Manufacturer specific" 246 "Manufacturer specific" 247 "Manufacturer specific" 248 "Manufacturer specific" 249 "Manufacturer specific" 250 "Reserved" 251 "Reserved" 252 "Reset all components" 253 "No action to be taken" 254 "Error" 255 "Not available" ;
VAL_ 2566832161 ServCompId3 0 "Serv. check for entire vehicle" 1 "Brake lining FA Left" 2 "Brake lining FA Right" 3 "Brake lining RA Left" 4 "Brake lining RA Right" 5 "Clutch lining" 6 "Reserved" 7 "Reserved" 8 "Reserved" 9 "Reserved" 10 "Reserved" 11 "Brake lining RA2 Left" 12 "Brake lining RA2 Right" 13 "Brake lining RA3 Left" 14 "Brake lining RA3 Right" 15 "Brake lining: general" 16 "Reg. gen. check for entire veh." 17 "Brake system special check" 18 "In-between check" 19 "Check trip recorder" 20 "Check exhaust gas" 21 "Check vehicle speed limiter" 22 "Reserved" 23 "Reserved" 24 "Reserved" 25 "Reserved" 26 "Reserved" 27 "Reserved" 28 "Reserved" 29 "Reserved" 30 "Engine coolant change" 31 "Engine coolant filter change" 32 "Engine oil-engine #1" 33 "Engine oil-engine #2" 34 "Reserved" 35 "Steering oil" 36 "Reserved" 37 "Transmission #1 oil" 38 "Transmission #2 oil" 39 "Transm. oil filter � Transm #1" 40 "Intermediate transm.n oil" 41 "Reserved" 42 "Front axle oil" 43 "Rear axle oil" 48 "Tires" 49 "Engine air filter" 50 "Engine oil filter" 51 "Engine Fuel Filter" 52 "Reserved" 53 "Reserved" 54 "Reserved" 55 "Reserved" 56 "Reserved" 57 "Reserved" 58 "Reserved" 59 "Reserved" 60 "Reserved" 61 "Tachograph" 62 "Driver card #1" 63 "Driver card #2" 64 "Reserved" 65 "Reserved" 66 "Reserved" 67 "Reserved" 68 "Reserved" 69 "Reserved" 70 "Reserved" 71 "DPF 1 Ash" 72 "DPF 2 Ash" 73 "AT DEF Doser Cooldown Intr. Cnt" 74 "AT DEF Doser Purge Intr. Cnt" 75 "Reserved" 239 "Reserved" 240 "Manufacturer specific" 241 "Manufacturer specific" 242 "Manufacturer specific" 243 "Manufacturer specific" 244 "Manufacturer specific" 245 "Manufacturer specific" 246 "Manufacturer specific" 247 "Manufacturer specific" 248 "Manufacturer specific" 249 "Manufacturer specific" 250 "Reserved" 251 "Reserved" 252 "Reset all components" 253 "No action to be taken" 254 "Error" 255 "Not available" ;
VAL_ 2566832161 ServCompId2 0 "Serv. check for entire vehicle" 1 "Brake lining, FA Left" 2 "Brake lining, FA Right" 3 "Brake lining, RA Left" 4 "Brake lining, RA Right" 5 "Clutch lining" 6 "Reserved" 7 "Reserved" 8 "Reserved" 9 "Reserved" 10 "Reserved" 11 "Brake lining, RA2 Left" 12 "Brake lining, RA2 Right" 13 "Brake lining, RA3 Left" 14 "Brake lining, RA3 Right" 15 "Brake lining: general" 16 "Reg. gen. check for entire veh." 17 "Brake system special check" 18 "In-between check" 19 "Check trip recorder" 20 "Check exhaust gas" 21 "Check vehicle speed limiter" 22 "Reserved" 23 "Reserved" 24 "Reserved" 25 "Reserved" 26 "Reserved" 27 "Reserved" 28 "Reserved" 29 "Reserved" 30 "Engine coolant change" 31 "Engine coolant filter change" 32 "Engine oil-engine #1" 33 "Engine oil-engine #2" 34 "Reserved" 35 "Steering oil" 36 "Reserved" 37 "Transmission #1 oil" 38 "Transmission #2 oil" 39 "Reserved" 40 "Intermediate transm.n oil" 41 "Reserved" 42 "Front axle oil" 43 "Rear axle oil" 48 "Tires" 49 "Engine air filter" 50 "Engine oil filter" 51 "Engine Fuel Filter" 52 "Reserved" 53 "Reserved" 54 "Reserved" 55 "Reserved" 56 "Reserved" 57 "Reserved" 58 "Reserved" 59 "Reserved" 60 "Reserved" 61 "Tachograph" 62 "Driver card #1" 63 "Driver card #2" 64 "Reserved" 65 "Reserved" 66 "Reserved" 67 "Reserved" 68 "Reserved" 69 "Reserved" 70 "Reserved" 71 "DPF 1 Ash" 72 "DPF 2 Ash" 73 "AT DEF Doser Cooldown Intr. Cnt" 74 "AT DEF Doser Purge Intr. Cnt" 75 "Reserved" 239 "Reserved" 240 "Manufacturer specific" 241 "Manufacturer specific" 242 "Manufacturer specific" 243 "Manufacturer specific" 244 "Manufacturer specific" 245 "Manufacturer specific" 246 "Manufacturer specific" 247 "Manufacturer specific" 248 "Manufacturer specific" 249 "Manufacturer specific" 250 "Reserved" 251 "Reserved" 252 "Reset all components" 253 "No Action to be taken" 254 "Error" 255 "Not Available" ;
VAL_ 2566832161 ServCompId_FEC021 0 "Serv. check for entire vehicle" 1 "Brake lining FA Left" 2 "Brake lining FA Right" 3 "Brake lining RA Left" 4 "Brake lining RA Right" 5 "Clutch lining" 6 "Reserved" 7 "Reserved" 8 "Reserved" 9 "Reserved" 10 "Reserved" 11 "Brake lining RA2 Left" 12 "Brake lining RA2 Right" 13 "Brake lining RA3 Left" 14 "Brake lining RA3 Right" 15 "Brake lining: general" 16 "Reg. gen. check for entire veh." 17 "Brake system special check" 18 "In-between check" 19 "Check trip recorder" 20 "Check exhaust gas" 21 "Check vehicle speed limiter" 22 "Reserved" 23 "Reserved" 24 "Reserved" 25 "Reserved" 26 "Reserved" 27 "Reserved" 28 "Reserved" 29 "Reserved" 30 "Engine coolant change" 31 "Engine coolant filter change" 32 "Engine oil-engine #1" 33 "Engine oil-engine #2" 34 "Reserved" 35 "Steering oil" 36 "Reserved" 37 "Transmission #1 oil" 38 "Transmission #2 oil" 39 "Transm. oil filter � Transm #1" 40 "Intermediate transm.n oil" 41 "Reserved" 42 "Front axle oil" 43 "Rear axle oil" 48 "Tires" 49 "Engine air filter" 50 "Engine oil filter" 51 "Engine Fuel Filter" 52 "Reserved" 53 "Reserved" 54 "Reserved" 55 "Reserved" 56 "Reserved" 57 "Reserved" 58 "Reserved" 59 "Reserved" 60 "Reserved" 61 "Tachograph" 62 "Driver card #1" 63 "Driver card #2" 64 "Reserved" 65 "Reserved" 66 "Reserved" 67 "Reserved" 68 "Reserved" 69 "Reserved" 70 "Reserved" 71 "DPF 1 Ash" 72 "DPF 2 Ash" 73 "AT DEF Doser Cooldown Intr. Cnt" 74 "AT DEF Doser Purge Intr. Cnt" 75 "Reserved" 239 "Reserved" 240 "Manufacturer specific" 241 "Manufacturer specific" 242 "Manufacturer specific" 243 "Manufacturer specific" 244 "Manufacturer specific" 245 "Manufacturer specific" 246 "Manufacturer specific" 247 "Manufacturer specific" 248 "Manufacturer specific" 249 "Manufacturer specific" 250 "Reserved" 251 "Reserved" 252 "Reset all components" 253 "No action to be taken" 254 "Error" 255 "Not available" ;
VAL_ 2566832366 ServCompId2_FEC0EE 0 "Serv. check for entire vehicle" 1 "Brake lining, FA Left" 2 "Brake lining, FA Right" 3 "Brake lining, RA Left" 4 "Brake lining, RA Right" 5 "Clutch lining" 6 "Reserved" 7 "Reserved" 8 "Reserved" 9 "Reserved" 10 "Reserved" 11 "Brake lining, RA2 Left" 12 "Brake lining, RA2 Right" 13 "Brake lining, RA3 Left" 14 "Brake lining, RA3 Right" 15 "Brake lining: general" 16 "Reg. gen. check for entire veh." 17 "Brake system special check" 18 "In-between check" 19 "Check trip recorder" 20 "Check exhaust gas" 21 "Check vehicle speed limiter" 22 "Reserved" 23 "Reserved" 24 "Reserved" 25 "Reserved" 26 "Reserved" 27 "Reserved" 28 "Reserved" 29 "Reserved" 30 "Engine coolant change" 31 "Engine coolant filter change" 32 "Engine oil-engine #1" 33 "Engine oil-engine #2" 34 "Reserved" 35 "Steering oil" 36 "Reserved" 37 "Transmission #1 oil" 38 "Transmission #2 oil" 39 "Reserved" 40 "Intermediate transm.n oil" 41 "Reserved" 42 "Front axle oil" 43 "Rear axle oil" 48 "Tires" 49 "Engine air filter" 50 "Engine oil filter" 51 "Engine Fuel Filter" 52 "Reserved" 53 "Reserved" 54 "Reserved" 55 "Reserved" 56 "Reserved" 57 "Reserved" 58 "Reserved" 59 "Reserved" 60 "Reserved" 61 "Tachograph" 62 "Driver card #1" 63 "Driver card #2" 64 "Reserved" 65 "Reserved" 66 "Reserved" 67 "Reserved" 68 "Reserved" 69 "Reserved" 70 "Reserved" 71 "DPF 1 Ash" 72 "DPF 2 Ash" 73 "AT DEF Doser Cooldown Intr. Cnt" 74 "AT DEF Doser Purge Intr. Cnt" 75 "Reserved" 239 "Reserved" 240 "Manufacturer specific" 241 "Manufacturer specific" 242 "Manufacturer specific" 243 "Manufacturer specific" 244 "Manufacturer specific" 245 "Manufacturer specific" 246 "Manufacturer specific" 247 "Manufacturer specific" 248 "Manufacturer specific" 249 "Manufacturer specific" 250 "Reserved" 251 "Reserved" 252 "Reset all components" 253 "No Action to be taken" 254 "Error" 255 "Not Available" ;
VAL_ 2566841344 EngProtSysApprShutdn 0 "Not approaching" 1 "Approaching" 2 "Error" 3 "Not Available" ;
VAL_ 2566841344 EngProtSysHasShutdnEng 0 "No" 1 "Yes" 2 "Error" 3 "Not Available" ;
VAL_ 2566841344 EngWaitToStartLamp 0 "Off" 1 "On" 2 "Error" 3 "Not Available" ;
VAL_ 2364543755 PitchAngleFigOfMerit 0 "Fully functional" 1 "Degraded" 2 "Error" 3 "Not Available" ;
